VERSION "created by canmatrix"

NS_ :

BS_:

BU_: HUT T_BOX GW XBOX_D CEM Tester

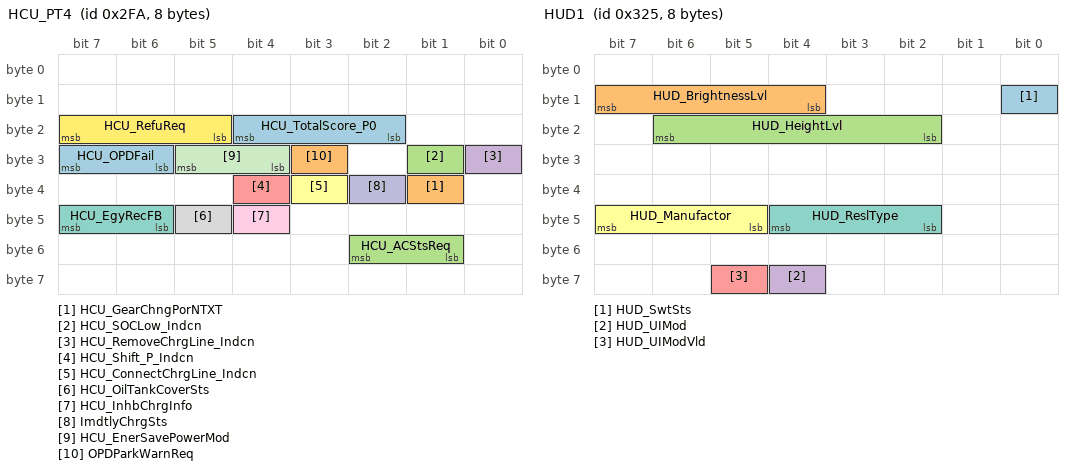
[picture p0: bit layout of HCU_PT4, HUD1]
BO_ 762 HCU_PT4: 8 GW
 SG_ HCU_TotalScore_P0 : 20|3@0+ (1,0) [0|5] "" HUT
 SG_ HCU_GearChngPorNTXT : 33|1@0+ (1,0) [0|1] "" HUT
 SG_ HCU_SOCLow_Indcn : 25|1@0+ (1,0) [0|1] "" HUT
 SG_ HCU_RemoveChrgLine_Indcn : 24|1@0+ (1,0) [0|1] "" HUT
 SG_ HCU_Shift_P_Indcn : 36|1@0+ (1,0) [0|1] "" HUT
 SG_ HCU_ConnectChrgLine_Indcn : 35|1@0+ (1,0) [0|1] "" HUT
 SG_ HCU_EgyRecFB : 47|2@0+ (1,0) [0|3] "" HUT
 SG_ HCU_OilTankCoverSts : 45|1@0+ (1,0) [0|1] "" HUT
 SG_ HCU_InhbChrgInfo : 44|1@0+ (1,0) [0|1] "" HUT
 SG_ ImdtlyChrgSts : 34|1@0+ (1,0) [0|1] "" HUT
 SG_ HCU_EnerSavePowerMod : 29|2@0+ (1,0) [0|3] "" HUT
 SG_ HCU_RefuReq : 23|3@0+ (1,0) [0|7] "" HUT
 SG_ HCU_OPDFail : 31|2@0+ (1,0) [0|3] "" HUT
 SG_ OPDParkWarnReq : 27|1@0+ (1,0) [0|1] "" HUT
 SG_ HCU_ACStsReq : 50|2@0+ (1,0) [0|3] "" HUT

BO_ 584 HCU_PT7: 8 GW
 SG_ HCU_12VSysErr_1 : 24|1@0+ (1,0) [0|1] "" HUT
 SG_ HCU_12VSysErr_2 : 39|1@0+ (1,0) [0|1] "" HUT
 SG_ HCU_HybSysErr_1 : 15|1@0+ (1,0) [0|1] "" HUT
 SG_ HCU_HybSysErr_2 : 14|1@0+ (1,0) [0|1] "" HUT
 SG_ HCU_HybSysErr_5 : 11|1@0+ (1,0) [0|1] "" HUT
 SG_ HCU_HybSysErr_6 : 10|1@0+ (1,0) [0|1] "" HUT
 SG_ HCU_HybSysErr_7 : 9|1@0+ (1,0) [0|1] "" HUT
 SG_ HCU_12VSysErrLmpSts : 8|1@0+ (1,0) [0|1] "" HUT
 SG_ HCU_HybSysErrLmpSts : 27|2@0+ (1,0) [0|3] "" HUT
 SG_ HCU_PowerRedWarnLmpCmd : 25|1@0+ (1,0) [0|1] "" HUT
 SG_ HCU_EnrgFlowInd : 55|5@0+ (1,0) [0|31] "" HUT
 SG_ HCU_HybSysErr_3 : 13|1@0+ (1,0) [0|1] "" HUT
 SG_ HCU_RdyLmpSts : 37|1@0+ (1,0) [0|1] "" HUT
 SG_ CheckSum_HCU_PT7 : 7|8@0+ (1,0) [0|255] "" HUT
 SG_ HCU_HybSysErr_4 : 12|1@0+ (1,0) [0|1] "" HUT
 SG_ HCU_EnrgFlowInd_P2 : 23|5@0+ (1,0) [0|31] "" HUT
 SG_ HCU_12VSysErr_3 : 38|1@0+ (1,0) [0|1] "" HUT
 SG_ HCU_OPDLmpSts : 36|1@0+ (1,0) [0|1] "" HUT
 SG_ HCU_OPDSts : 43|3@0+ (1,0) [0|7] "" HUT
 SG_ HCU_ModSwtFail : 63|4@0+ (1,0) [0|15] "" HUT
 SG_ RollingCounter_HCU_PT7 : 59|4@0+ (1,0) [0|15] "" HUT

BO_ 805 HUD1: 8 GW
 SG_ HUD_SwtSts : 8|1@0+ (1,0) [0|1] "" HUT
 SG_ HUD_BrightnessLvl : 15|4@0+ (1,0) [0|15] "" HUT
 SG_ HUD_HeightLvl : 22|5@0+ (1,0) [0|31] "" HUT
 SG_ HUD_UIMod : 60|1@0+ (1,0) [0|1] "" HUT
 SG_ HUD_UIModVld : 61|1@0+ (1,0) [0|1] "" HUT
 SG_ HUD_Manufactor : 47|3@0+ (1,0) [0|7] "" HUT
 SG_ HUD_ReslType : 44|3@0+ (1,0) [0|7] "" HUT

BO_ 707 HUT_FD1: 64 HUT
 SG_ SSSSet_HUT : 64|1@0+ (1,0) [0|1] "" Vector__XXX
 SG_ IFC_SnvtySet : 77|2@0+ (1,0) [0|3] "" GW
 SG_ DOWSwtReq : 104|1@0+ (1,0) [0|1] "" GW
 SG_ AEB_PedSwtReq : 105|1@0+ (1,0) [0|1] "" GW
 SG_ ALCMLightLvlSet : 75|4@0+ (1,0) [0|15] "" CEM
 SG_ FlashLmpSwtReq : 86|1@0+ (1,0) [0|1] "" CEM
 SG_ LCASwtReq : 85|1@0+ (1,0) [0|1] "" GW
 SG_ RCTASwtReq : 84|1@0+ (1,0) [0|1] "" GW
 SG_ RCTABrkSwtReq : 83|1@0+ (1,0) [0|1] "" GW
 SG_ RCWSwtReq : 82|1@0+ (1,0) [0|1] "" GW
 SG_ FCW_SnvtySet : 81|2@0+ (1,0) [0|3] "" GW
 SG_ AEB_VehSwtReq : 95|1@0+ (1,0) [0|1] "" GW
 SG_ LKASwtReq : 93|1@0+ (1,0) [0|1] "" GW
 SG_ LCKSwtReq : 92|1@0+ (1,0) [0|1] "" GW
 SG_ ELKSwtReq : 91|1@0+ (1,0) [0|1] "" GW
 SG_ ESS_PedSwtReq : 90|1@0+ (1,0) [0|1] "" GW
 SG_ ESS_VehSwtReq : 89|1@0+ (1,0) [0|1] "" GW
 SG_ LDWSwtReq : 88|1@0+ (1,0) [0|1] "" GW
 SG_ TSRSwtReq : 102|1@0+ (1,0) [0|1] "" GW
 SG_ TSRWarnSwtReq : 101|1@0+ (1,0) [0|1] "" GW
 SG_ ICA_HandsOffSwtReq : 127|1@0+ (1,0) [0|1] "" GW
 SG_ ISLSwtReq : 126|1@0+ (1,0) [0|1] "" GW
 SG_ TSR_SnvtySet : 125|5@0+ (1,-15) [-15|15] "kmh" GW
 SG_ HFASwtSts : 87|1@0+ (1,0) [0|1] "" CEM
 SG_ EPSSteerModSwtReq : 114|2@0+ (1,0) [0|3] "" GW
 SG_ DSTSwtReq : 112|1@0+ (1,0) [0|1] "" GW
 SG_ LSSWarnFormSwtReq : 100|2@0+ (1,0) [0|3] "" GW
 SG_ HUT_ESPFuncOffSwtSts : 98|1@0+ (1,0) [0|1] "" GW
 SG_ DrivingModReq_HUT : 111|4@0+ (1,0) [0|15] "" GW
 SG_ OilLvlDispReq : 115|1@0+ (1,0) [0|1] "" GW
 SG_ DrvgModeMemReq : 120|1@0+ (1,0) [0|1] "" CEM,T_BOX
 SG_ IntelligentEvaSwtReq : 107|1@0+ (1,0) [0|1] "" GW
 SG_ LSSSwtReq : 106|1@0+ (1,0) [0|1] "" GW
 SG_ HUTRadioFrq : 143|12@0+ (1,0) [0|4095] "AM: kHzFM: MHz" Vector__XXX
 SG_ MediaPlaySrc : 159|4@0+ (1,0) [0|15] "" Vector__XXX
 SG_ USB_AudioSts : 169|2@0+ (1,0) [0|3] "" Vector__XXX
 SG_ USB_VideoSts : 177|2@0+ (1,0) [0|3] "" Vector__XXX
 SG_ BT_AudioSts : 179|2@0+ (1,0) [0|3] "" Vector__XXX
 SG_ IPod_Sts : 181|2@0+ (1,0) [0|3] "" Vector__XXX
 SG_ AM_Sts : 183|2@0+ (1,0) [0|3] "" Vector__XXX
 SG_ FM_Sts : 185|2@0+ (1,0) [0|3] "" Vector__XXX
 SG_ APPLink_Sts : 187|2@0+ (1,0) [0|3] "" Vector__XXX
 SG_ QQMusic_Sts : 189|2@0+ (1,0) [0|3] "" Vector__XXX
 SG_ KaolaFM_Sts : 191|2@0+ (1,0) [0|3] "" Vector__XXX
 SG_ OnlineNews_Sts : 145|2@0+ (1,0) [0|3] "" Vector__XXX
 SG_ HUT_WadeModeSet : 161|1@0+ (1,0) [0|1] "" GW
 SG_ ExpertModReq_HUT_ECM : 175|3@0+ (1,0) [0|7] "" GW
 SG_ ExpertModReq_HUT_TCU : 172|3@0+ (1,0) [0|7] "" GW
 SG_ ExpertModReq_HUT_TOD : 163|2@0+ (1,0) [0|3] "" GW
 SG_ ChairMemPosnSet : 244|2@0+ (1,0) [0|3] "" CEM
 SG_ ChairMemPosnSetResult : 255|4@0+ (1,0) [0|15] "" CEM
 SG_ TABSwtReq_HUT : 224|1@0+ (1,0) [0|1] "" Vector__XXX
 SG_ NavVehToTrafEyeDist : 239|10@0+ (1,0) [0|1023] "" GW
 SG_ NavRoadType : 311|4@0+ (1,0) [0|15] "" GW
 SG_ NavSpdLimType : 307|2@0+ (1,0) [0|3] "" GW
 SG_ NavSpdLimValue : 271|6@0+ (1,0) [0|63] "" GW
 SG_ NavSpdLimUnit_HUT : 265|2@0+ (1,0) [0|3] "" GW
 SG_ NavCtryType : 279|10@0+ (1,0) [0|1023] "" GW
 SG_ NavSpdLimSignSts : 285|3@0+ (1,0) [0|7] "" GW
 SG_ NavTSRTrafSign : 295|8@0+ (1,0) [0|255] "" GW
 SG_ AESSwtReq : 298|1@0+ (1,0) [0|1] "" GW
 SG_ HWA_SwtReq : 280|1@0+ (1,0) [0|1] "" GW
 SG_ HWA_SnvtySet : 303|2@0+ (1,0) [0|3] "" GW
 SG_ FCTASwtReq : 301|1@0+ (1,0) [0|1] "" GW
 SG_ FCTABrkSwtReq : 300|1@0+ (1,0) [0|1] "" GW
 SG_ AEB_JASwtReq : 299|1@0+ (1,0) [0|1] "" GW
 SG_ HWA_WarnFormSwtReq : 297|1@0+ (1,0) [0|1] "" Vector__XXX
 SG_ SteerCorrnReq : 316|1@0+ (1,0) [0|1] "" GW
 SG_ ALC_SwtReq : 296|1@0+ (1,0) [0|1] "" GW
 SG_ ExpertModSwtReq_HUT : 319|1@0+ (1,0) [0|1] "" GW
 SG_ ExpertModReq_HUT_ESP : 318|2@0+ (1,0) [0|3] "" GW
 SG_ ADAS_Posn_MsgTye : 327|3@0+ (1,0) [0|7] "" GW
 SG_ ADAS_Posn_Offset : 324|13@0+ (1,0) [0|8190] "m" GW
 SG_ ADAS_Posn_CycCnt : 343|2@0+ (1,0) [0|3] "" GW
 SG_ ADAS_Posn_Pathldx : 341|6@0+ (1,0) [0|63] "" GW
 SG_ ADAS_Posn_Idx : 351|2@0+ (1,0) [0|3] "m" GW
 SG_ ADAS_Posn_PosProbb : 349|5@0+ (3.33,0) [0|100] "" GW
 SG_ ADAS_Posn_Age : 344|9@0+ (5,0) [0|2545] "ms" GW
 SG_ ADAS_Posn_PosConfdc : 366|3@0+ (1,0) [0|7] "" GW
 SG_ ADAS_Posn_CurLane : 363|3@0+ (1,0) [0|7] "" GW
 SG_ ADAS_Posn_Spd : 360|9@0+ (0.2,-12.8) [-12.8|89.2] "ms" GW
 SG_ ADAS_Posn_Rehead : 383|8@0+ (1.41732283464567,0) [0|358.583] "" GW
 SG_ FreshnessValue_HUT_FD1 : 455|16@0+ (1,0) [0|65535] "" GW
 SG_ MAC_Check_HUT_FD1 : 471|48@0+ (1,0) [0|281474976710655] "" GW
 SG_ EngStrtDischrgn : 70|1@0+ (1,0) [0|1] "" GW
 SG_ HUT_HybModReq : 119|2@0+ (1,0) [0|3] "" GW
 SG_ HUT_HybFctnReq : 117|2@0+ (1,0) [0|3] "" GW
 SG_ HUT_DrvModReq : 167|4@0+ (1,0) [0|15] "" GW

BO_ 515 HUT_FD2: 64 HUT
 SG_ HUT_OD_Obj0_ID : 15|4@0+ (1,0) [0|9] "" GW
 SG_ HUT_OD_Obj0_type : 23|3@0+ (1,0) [0|7] "" GW
 SG_ HUT_OD_Obj0_Confidence : 11|4@0+ (0.1,0) [0|1] "" GW
 SG_ HUT_OD_Obj0_width : 20|7@0+ (0.1,0) [0|12.6] "m" GW
 SG_ HUT_OD_Obj0_Ground_Pos_X : 39|12@0+ (0.01,0) [0|40] "m" GW
 SG_ HUT_OD_Obj0_Ground_Pos_Y : 43|12@0+ (0.01,-20) [-20|20] "m" GW
 SG_ HTU_OD_Obj1_ID : 79|4@0+ (1,0) [0|9] "" GW
 SG_ HUT_OD_Obj1_type : 87|3@0+ (1,0) [0|7] "" GW
 SG_ HUT_OD_Obj1_Confidence : 75|4@0+ (0.1,0) [0|1] "" GW
 SG_ HUT_OD_Obj1_width : 84|7@0+ (0.1,0) [0|12.6] "m" GW
 SG_ HUT_OD_Obj1_Ground_Pos_X : 103|12@0+ (0.01,0) [0|40] "m" GW
 SG_ HUT_OD_Obj1_Ground_Pos_Y : 107|12@0+ (0.01,-20) [-20|20] "m" GW
 SG_ HUT_OD_Obj2_ID : 143|4@0+ (1,0) [0|9] "" GW
 SG_ HUT_OD_Obj2_type : 151|3@0+ (1,0) [0|7] "" GW
 SG_ HUT_OD_Obj2_Confidence : 139|4@0+ (0.1,0) [0|1] "" GW
 SG_ HUT_OD_Obj2_width : 148|7@0+ (0.1,0) [0|12.6] "m" GW
 SG_ HUT_OD_Obj2_Ground_Pos_X : 167|12@0+ (0.01,0) [0|40] "m" GW
 SG_ HUT_OD_Obj2_Ground_Pos_Y : 171|12@0+ (0.01,-20) [-20|20] "m" GW
 SG_ HUT_OD_Obj3_ID : 207|4@0+ (1,0) [0|9] "" GW
 SG_ HUT_OD_Obj3_type : 215|3@0+ (1,0) [0|7] "" GW
 SG_ HUT_OD_Obj3_Confidence : 203|4@0+ (0.1,0) [0|1] "" GW
 SG_ HUT_OD_Obj3_width : 212|7@0+ (0.1,0) [0|12.6] "m" GW
 SG_ HUT_OD_Obj3_Ground_Pos_X : 231|12@0+ (0.01,0) [0|40] "m" GW
 SG_ HUT_OD_Obj3_Ground_Pos_Y : 235|12@0+ (0.01,-20) [-20|20] "m" GW
 SG_ HUT_OD_Obj4_ID : 271|4@0+ (1,0) [0|9] "" GW
 SG_ HUT_OD_Obj4_type : 279|3@0+ (1,0) [0|7] "" GW
 SG_ HUT_OD_Obj4_Confidence : 267|4@0+ (0.1,0) [0|1] "" GW
 SG_ HUT_OD_Obj4_width : 276|7@0+ (0.1,0) [0|12.6] "m" GW
 SG_ HUT_OD_Obj4_Ground_Pos_X : 295|12@0+ (0.01,0) [0|40] "m" GW
 SG_ HUT_OD_Obj4_Ground_Pos_Y : 299|12@0+ (0.01,-20) [-20|20] "m" GW
 SG_ HUT_OD_Obj5_ID : 335|4@0+ (1,0) [0|9] "" GW
 SG_ HUT_OD_Obj5_type : 343|3@0+ (1,0) [0|7] "" GW
 SG_ HUT_OD_Obj5_Confidence : 331|4@0+ (0.1,0) [0|1] "" GW
 SG_ HUT_OD_Obj5_width : 340|7@0+ (0.1,0) [0|12.6] "m" GW
 SG_ HUT_OD_Obj5_Ground_Pos_X : 359|12@0+ (0.01,0) [0|40] "m" GW
 SG_ HUT_OD_Obj5_Ground_Pos_Y : 363|12@0+ (0.01,-20) [-20|20] "m" GW
 SG_ HUT_OD_Obj6_ID : 399|4@0+ (1,0) [0|9] "" GW
 SG_ HUT_OD_Obj6_type : 407|3@0+ (1,0) [0|7] "" GW
 SG_ HUT_OD_Obj6_Confidence : 395|4@0+ (0.1,0) [0|1] "" GW
 SG_ HUT_OD_Obj6_width : 404|7@0+ (0.1,0) [0|12.6] "m" GW
 SG_ HUT_OD_Obj6_Ground_Pos_X : 423|12@0+ (0.01,0) [0|40] "m" GW
 SG_ HUT_OD_Obj6_Ground_Pos_Y : 427|12@0+ (0.01,-20) [-20|20] "m" GW

BO_ 579 HUT_FD3: 64 HUT
 SG_ HUT_OD_Obj7_ID : 15|4@0+ (1,0) [0|9] "" GW
 SG_ HUT_OD_Obj7_type : 23|3@0+ (1,0) [0|7] "" GW
 SG_ HUT_OD_Obj7_Confidence : 11|4@0+ (0.1,0) [0|1] "" GW
 SG_ HUT_OD_Obj7_width : 20|7@0+ (0.1,0) [0|12.6] "m" GW
 SG_ HUT_OD_Obj7_Ground_Pos_X : 39|12@0+ (0.01,0) [0|40] "m" GW
 SG_ HUT_OD_Obj7_Ground_Pos_Y : 43|12@0+ (0.01,-20) [-20|20] "m" GW
 SG_ AutoSpdSetSwt : 25|1@0+ (1,0) [0|1] "" GW
 SG_ LaneChngCfmSwt : 24|1@0+ (1,0) [0|1] "" GW
 SG_ VoiceBrdcSwt : 63|1@0+ (1,0) [0|1] "" GW
 SG_ UsrManSts : 29|4@0+ (1,0) [0|15] "" GW
 SG_ HUT_OD_WorkSts : 113|2@0+ (1,0) [0|3] "" GW
 SG_ HUT_OD_Obj_Timestamp : 79|16@0+ (1,0) [0|65535] "ms" GW
 SG_ HUT_FSD1_distance : 95|6@0+ (0.1,0) [0|6] "m" GW
 SG_ HUT_FSD2_distance : 89|6@0+ (0.1,0) [0|6] "m" GW
 SG_ HUT_FSD3_distance : 99|6@0+ (0.1,0) [0|6] "m" GW
 SG_ HUT_FSD4_distance : 109|6@0+ (0.1,0) [0|6] "m" GW
 SG_ HUT_FSD5_distance : 119|6@0+ (0.1,0) [0|6] "m" GW
 SG_ HUT_FSD6_distance : 143|6@0+ (0.1,0) [0|6] "m" GW
 SG_ HUT_FSD7_distance : 137|6@0+ (0.1,0) [0|6] "m" GW
 SG_ HUT_FSD8_distance : 147|6@0+ (0.1,0) [0|6] "m" GW
 SG_ HUT_FSD9_distance : 157|6@0+ (0.1,0) [0|6] "m" GW
 SG_ HUT_FSD10_distance : 167|6@0+ (0.1,0) [0|6] "m" GW
 SG_ HUT_FSD11_distance : 161|6@0+ (0.1,0) [0|6] "m" GW
 SG_ HUT_FSD12_distance : 171|6@0+ (0.1,0) [0|6] "m" GW
 SG_ HUT_FSD13_distance : 181|6@0+ (0.1,0) [0|6] "m" GW
 SG_ HUT_FSD14_distance : 207|6@0+ (0.1,0) [0|6] "m" GW
 SG_ HUT_FSD15_distance : 201|6@0+ (0.1,0) [0|6] "m" GW
 SG_ HUT_FSD16_distance : 211|6@0+ (0.1,0) [0|6] "m" GW
 SG_ HUT_FSD17_distance : 221|6@0+ (0.1,0) [0|6] "m" GW
 SG_ HUT_FSD18_distance : 231|6@0+ (0.1,0) [0|6] "m" GW
 SG_ NOH_Swt_Req : 335|1@0+ (1,0) [0|1] "" GW
 SG_ NOH_Act_Req : 334|1@0+ (1,0) [0|1] "" GW

BO_ 474 HUT_FD4: 64 HUT
 SG_ SlotNum_VR : 35|4@0+ (1,0) [0|15] "" GW
 SG_ UserDefinedParkCmd : 44|1@0+ (1,0) [0|1] "" GW
 SG_ HUT_HAVP_Set_Starting : 10|1@0+ (1,0) [0|1] "" GW
 SG_ HUT_HAVP_Set_Path_Ending : 21|1@0+ (1,0) [0|1] "" GW
 SG_ HUT_HAVP_APA_Permit : 43|2@0+ (1,0) [0|3] "" GW
 SG_ UserDefPrkMenuSelCmd : 18|3@0+ (1,0) [0|1] "" GW
 SG_ HUT_HAVP_SelfParLot_Ending : 9|1@0+ (1,0) [0|1] "" GW
 SG_ HUT_HAVP_Return_Btn : 11|1@0+ (1,0) [0|1] "" GW

BO_ 475 HUT_FD5: 64 HUT
 SG_ HUT_ExternalDevice : 7|512@0+ (1,0) [0|3.40282366920938E+038] "" XBOX_D

BO_ 871 HUT1: 8 HUT
 SG_ DomeLmpDlyTimSet : 7|3@0+ (1,0) [0|7] "" CEM
 SG_ FolwMeHomeDlyTimSet : 3|3@0+ (1,0) [0|7] "" CEM
 SG_ TranPMode_Req : 15|1@0+ (1,0) [0|1] "" GW,CEM
 SG_ RearviewFoldModSet : 14|1@0+ (1,0) [0|1] "" CEM
 SG_ BattSaveDelayTimeSet : 13|2@0+ (1,0) [0|3] "" CEM
 SG_ ACDualReq_TC : 21|2@0+ (1,0) [0|3] "" GW
 SG_ ACAutoModReq_TC : 19|2@0+ (1,0) [0|3] "" GW
 SG_ ACAirInletReq_TC : 17|2@0+ (1,0) [0|3] "" GW
 SG_ ACFrntHMIDis_TC : 33|1@0+ (1,0) [0|1] "" GW
 SG_ ACRearHMIDis_TC : 32|1@0+ (1,0) [0|1] "" GW
 SG_ ACAQSReq_TC : 31|2@0+ (1,0) [0|3] "" GW
 SG_ ACCmprReq_TC : 29|2@0+ (1,0) [0|3] "" GW
 SG_ ACFrntDefrstReq_TC : 27|2@0+ (1,0) [0|3] "" GW
 SG_ ACFrntBlwrSpdDecReq_TC : 25|2@0+ (1,0) [0|3] "" GW
 SG_ ACRearBlwrSpdDecReq_TC : 23|1@0+ (1,0) [0|1] "" GW
 SG_ ACRearBlwrSpdIncReq_TC : 22|1@0+ (1,0) [0|1] "" GW
 SG_ DrvDrowsnsDetnSet : 36|1@0+ (1,0) [0|1] "" CEM
 SG_ ACFrntBlwrSpdIncReq_TC : 47|2@0+ (1,0) [0|3] "" GW
 SG_ ACDrvAirDistribModReq_TC : 45|3@0+ (1,0) [0|7] "" GW
 SG_ ACDrvTempDecReq_TC : 42|2@0+ (1,0) [0|3] "" GW
 SG_ ChairMemPosnEna : 40|1@0+ (1,0) [0|1] "" CEM
 SG_ ACDrvTempIncReq_TC : 55|2@0+ (1,0) [0|3] "" GW
 SG_ ACFrntPassTempDecReq_TC : 53|2@0+ (1,0) [0|3] "" GW
 SG_ ACFrntPassTempIncReq_TC : 51|2@0+ (1,0) [0|3] "" GW
 SG_ ACAIUReq_TC : 48|1@0+ (1,0) [0|1] "" GW
 SG_ ACOffReq_TC : 63|2@0+ (1,0) [0|3] "" GW
 SG_ ACBlwrsteplsSpdReq_TC : 59|4@0+ (1,0) [0|15] "" GW
 SG_ ACZoneReq_TC : 4|1@0+ (1,0) [0|1] "" GW

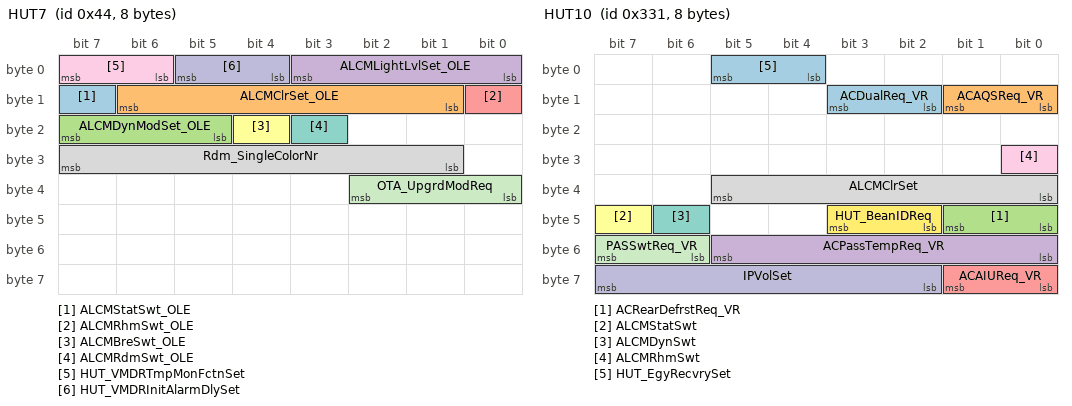
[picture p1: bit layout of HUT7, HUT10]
BO_ 68 HUT7: 8 HUT
 SG_ ALCMStatSwt_OLE : 15|1@0+ (1,0) [0|1] "" CEM
 SG_ ALCMClrSet_OLE : 14|6@0+ (1,0) [0|63] "" CEM
 SG_ ALCMDynModSet_OLE : 23|3@0+ (1,0) [0|7] "" CEM
 SG_ ALCMLightLvlSet_OLE : 3|4@0+ (1,0) [0|15] "" CEM
 SG_ ALCMRhmSwt_OLE : 8|1@0+ (1,0) [0|1] "" CEM
 SG_ ALCMBreSwt_OLE : 20|1@0+ (1,0) [0|1] "" CEM
 SG_ ALCMRdmSwt_OLE : 19|1@0+ (1,0) [0|1] "" CEM
 SG_ Rdm_SingleColorNr : 31|7@0+ (1,0) [0|127] "" CEM
 SG_ HUT_VMDRTmpMonFctnSet : 7|2@0+ (1,0) [0|3] "" Vector__XXX
 SG_ HUT_VMDRInitAlarmDlySet : 5|2@0+ (1,0) [0|3] "" Vector__XXX
 SG_ OTA_UpgrdModReq : 34|3@0+ (1,0) [0|7] "" CEM

BO_ 817 HUT10: 8 HUT
 SG_ ACDualReq_VR : 11|2@0+ (1,0) [0|3] "" GW,CEM
 SG_ ACAQSReq_VR : 9|2@0+ (1,0) [0|3] "" GW,CEM
 SG_ ACRearDefrstReq_VR : 41|2@0+ (1,0) [0|3] "" GW,CEM
 SG_ ACPassTempReq_VR : 53|6@0+ (0.5,15.5) [16|32] "Ã‚Â°C" GW,CEM
 SG_ ACAIUReq_VR : 57|2@0+ (1,0) [0|3] "" GW,CEM
 SG_ ALCMStatSwt : 47|1@0+ (1,0) [0|1] "" CEM
 SG_ ALCMDynSwt : 46|1@0+ (1,0) [0|1] "" CEM
 SG_ ALCMClrSet : 37|6@0+ (1,0) [0|63] "" CEM
 SG_ ALCMRhmSwt : 24|1@0+ (1,0) [0|1] "" CEM
 SG_ IPVolSet : 63|6@0+ (1,0) [0|63] "" GW
 SG_ PASSwtReq_VR : 55|2@0+ (1,0) [0|3] "" CEM
 SG_ HUT_BeanIDReq : 43|2@0+ (1,0) [0|3] "" GW
 SG_ HUT_EgyRecvrySet : 5|2@0+ (1,0) [0|3] "" GW

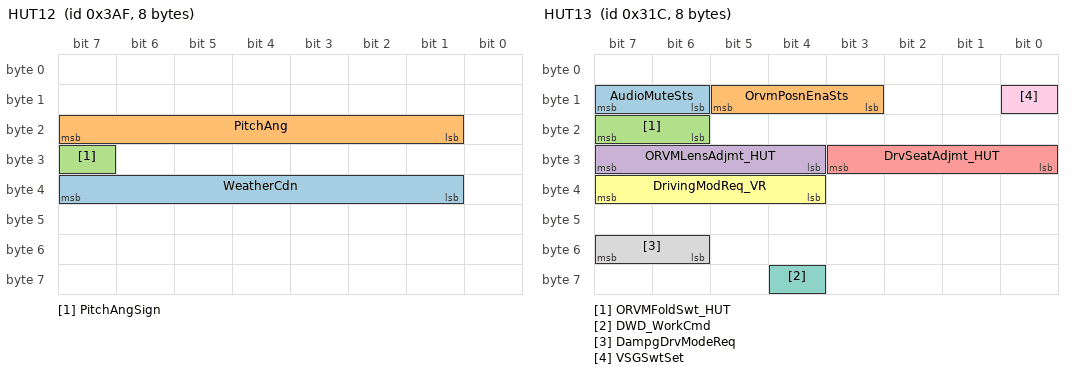
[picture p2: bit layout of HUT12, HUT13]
BO_ 943 HUT12: 8 HUT
 SG_ WeatherCdn : 39|7@0+ (1,0) [0|127] "" Vector__XXX
 SG_ PitchAng : 23|7@0+ (1,0) [0|90] "" Vector__XXX
 SG_ PitchAngSign : 31|1@0+ (1,0) [0|1] "" Vector__XXX

BO_ 796 HUT13: 8 HUT
 SG_ AudioMuteSts : 15|2@0+ (1,0) [0|3] "" T_BOX
 SG_ OrvmPosnEnaSts : 13|3@0+ (1,0) [0|7] "" CEM
 SG_ ORVMFoldSwt_HUT : 23|2@0+ (1,0) [0|3] "" CEM
 SG_ ORVMLensAdjmt_HUT : 31|4@0+ (1,0) [0|15] "" CEM
 SG_ DrvSeatAdjmt_HUT : 27|4@0+ (1,0) [0|15] "" CEM
 SG_ DrivingModReq_VR : 39|4@0+ (1,0) [0|15] "" Vector__XXX
 SG_ DWD_WorkCmd : 60|1@0+ (1,0) [0|1] "" Vector__XXX
 SG_ DampgDrvModeReq : 55|2@0+ (1,0) [0|3] "" Vector__XXX
 SG_ VSGSwtSet : 8|1@0+ (1,0) [0|1] "" GW

BO_ 494 HUT15: 16 HUT
 SG_ ACOperMod_TC : 7|2@0+ (1,0) [0|3] "" GW,CEM
 SG_ ACOperMod_VR : 5|2@0+ (1,0) [0|3] "" GW,CEM
 SG_ ACDrvSetTempSteplsReq_TC : 23|6@0+ (0.5,15.5) [16|32] "" GW,CEM
 SG_ ACPassSetTempSteplsReq_TC : 31|6@0+ (0.5,15.5) [16|32] "" GW,CEM
 SG_ SDWSwtSet : 39|1@0+ (1,0) [0|1] "" GW
 SG_ APSSwtReq_VR : 55|2@0+ (1,0) [0|3] "" GW
 SG_ APSPrkgTypSeln : 34|2@0+ (1,0) [0|3] "" GW
 SG_ SunShadeSwtReq_VR : 43|4@0+ (1,0) [0|15] "" CEM
 SG_ SunRoofSwtReq_VR : 47|4@0+ (1,0) [0|15] "" CEM
 SG_ SportModLightSet : 1|2@0+ (1,0) [0|3] "" CEM
 SG_ ABSLmpSet : 14|1@0+ (1,0) [0|1] "" CEM
 SG_ AutoWshWipSet : 12|2@0+ (1,0) [0|3] "" CEM
 SG_ SeekVehSet : 10|2@0+ (1,0) [0|3] "" CEM
 SG_ SpdAutoLockModSet : 25|2@0+ (1,0) [0|3] "" CEM
 SG_ ParkLmpSet : 8|1@0+ (1,0) [0|1] "" CEM
 SG_ DoorUnlockModSet : 15|1@0+ (1,0) [0|1] "" CEM
 SG_ SteerWheelHeatSwtReq : 3|2@0+ (1,0) [0|3] "" GW
 SG_ PASExitSpdSwt : 53|2@0+ (1,0) [0|3] "" CEM
 SG_ FrntRearACDispSts : 49|2@0+ (1,0) [0|3] "" GW,CEM
 SG_ FreshnessValue_HUT15 : 71|16@0+ (1,0) [0|65535] "" GW
 SG_ MAC_Check_HUT15 : 87|48@0+ (1,0) [0|281474976710655] "" GW

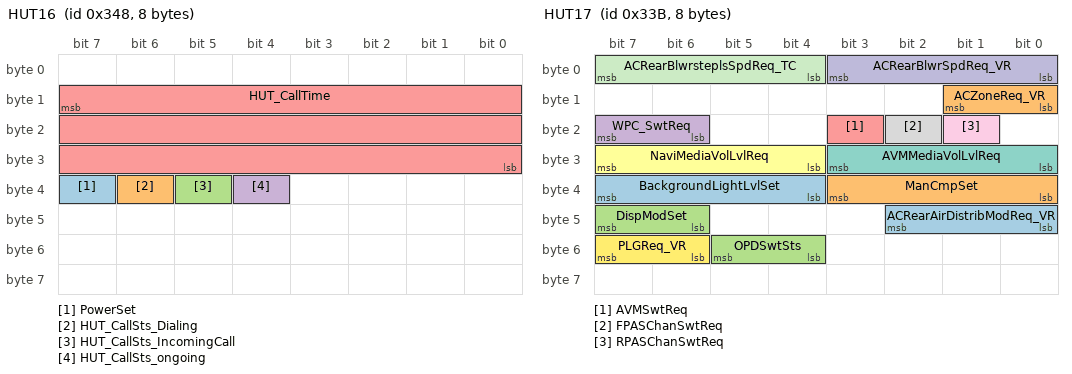
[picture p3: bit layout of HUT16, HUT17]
BO_ 840 HUT16: 8 HUT
 SG_ PowerSet : 39|1@0+ (1,0) [0|1] "" GW
 SG_ HUT_CallSts_Dialing : 38|1@0+ (1,0) [0|1] "" Vector__XXX
 SG_ HUT_CallSts_IncomingCall : 37|1@0+ (1,0) [0|1] "" Vector__XXX
 SG_ HUT_CallSts_ongoing : 36|1@0+ (1,0) [0|1] "" Vector__XXX
 SG_ HUT_CallTime : 15|24@0+ (1,0) [0|359999] "" Vector__XXX

BO_ 827 HUT17: 8 HUT
 SG_ BackgroundLightLvlSet : 39|4@0+ (1,0) [0|15] "" CEM
 SG_ ManCmpSet : 35|4@0+ (1,0) [0|15] "" Vector__XXX
 SG_ DispModSet : 47|2@0+ (1,0) [0|3] "" Vector__XXX
 SG_ WPC_SwtReq : 23|2@0+ (1,0) [0|3] "" GW
 SG_ AVMSwtReq : 19|1@0+ (1,0) [0|1] "" GW
 SG_ NaviMediaVolLvlReq : 31|4@0+ (1,0) [0|15] "" GW
 SG_ AVMMediaVolLvlReq : 27|4@0+ (1,0) [0|15] "" GW
 SG_ FPASChanSwtReq : 18|1@0+ (1,0) [0|1] "" GW
 SG_ RPASChanSwtReq : 17|1@0+ (1,0) [0|1] "" GW
 SG_ ACRearBlwrSpdReq_VR : 3|4@0+ (1,0) [0|15] "" GW,CEM
 SG_ ACRearBlwrsteplsSpdReq_TC : 7|4@0+ (1,0) [0|15] "" GW,CEM
 SG_ PLGReq_VR : 55|2@0+ (1,0) [0|3] "" CEM
 SG_ ACRearAirDistribModReq_VR : 42|3@0+ (1,0) [0|7] "" GW,CEM
 SG_ ACZoneReq_VR : 9|2@0+ (1,0) [0|3] "" GW,CEM
 SG_ OPDSwtSts : 53|2@0+ (1,0) [0|3] "" GW

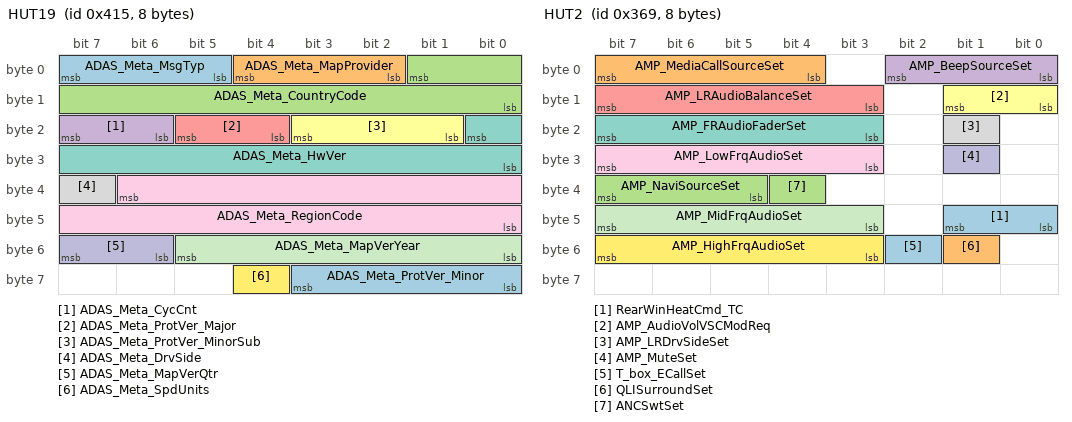
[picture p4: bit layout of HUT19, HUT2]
BO_ 1045 HUT19: 8 HUT
 SG_ ADAS_Meta_MsgTyp : 7|3@0+ (1,0) [0|7] "" GW
 SG_ ADAS_Meta_MapProvider : 4|3@0+ (1,0) [0|7] "" GW
 SG_ ADAS_Meta_CountryCode : 1|10@0+ (1,0) [0|1023] "" GW
 SG_ ADAS_Meta_CycCnt : 23|2@0+ (1,0) [0|3] "" GW
 SG_ ADAS_Meta_ProtVer_Major : 21|2@0+ (1,0) [0|3] "" GW
 SG_ ADAS_Meta_ProtVer_MinorSub : 19|3@0+ (1,0) [0|7] "" GW
 SG_ ADAS_Meta_HwVer : 16|9@0+ (1,0) [0|511] "" GW
 SG_ ADAS_Meta_DrvSide : 39|1@0+ (1,0) [0|1] "" GW
 SG_ ADAS_Meta_RegionCode : 38|15@0+ (1,0) [0|32767] "" GW
 SG_ ADAS_Meta_MapVerQtr : 55|2@0+ (1,0) [0|3] "" GW
 SG_ ADAS_Meta_MapVerYear : 53|6@0+ (1,0) [0|63] "" GW
 SG_ ADAS_Meta_SpdUnits : 60|1@0+ (1,0) [0|1] "" GW
 SG_ ADAS_Meta_ProtVer_Minor : 59|4@0+ (1,0) [0|15] "" GW

BO_ 873 HUT2: 8 HUT
 SG_ RearWinHeatCmd_TC : 41|2@0+ (1,0) [0|3] "" GW
 SG_ AMP_MediaCallSourceSet : 7|4@0+ (1,0) [0|15] "" GW
 SG_ AMP_NaviSourceSet : 39|3@0+ (1,0) [0|7] "" GW
 SG_ AMP_BeepSourceSet : 2|3@0+ (1,0) [0|7] "" GW
 SG_ AMP_LRAudioBalanceSet : 15|5@0+ (1,0) [0|20] "" GW
 SG_ AMP_AudioVolVSCModReq : 9|2@0+ (1,0) [0|3] "" GW
 SG_ AMP_FRAudioFaderSet : 23|5@0+ (1,0) [0|20] "" GW
 SG_ AMP_LRDrvSideSet : 17|1@0+ (1,0) [0|1] "" GW
 SG_ AMP_LowFrqAudioSet : 31|5@0+ (1,0) [0|20] "" GW
 SG_ AMP_MuteSet : 25|1@0+ (1,0) [0|1] "" GW
 SG_ AMP_MidFrqAudioSet : 47|5@0+ (1,0) [0|20] "" GW
 SG_ AMP_HighFrqAudioSet : 55|5@0+ (1,0) [0|20] "" GW
 SG_ T_box_ECallSet : 50|1@0+ (1,0) [0|1] "" GW
 SG_ QLISurroundSet : 49|1@0+ (1,0) [0|1] "" GW
 SG_ ANCSwtSet : 36|1@0+ (1,0) [0|1] "" GW

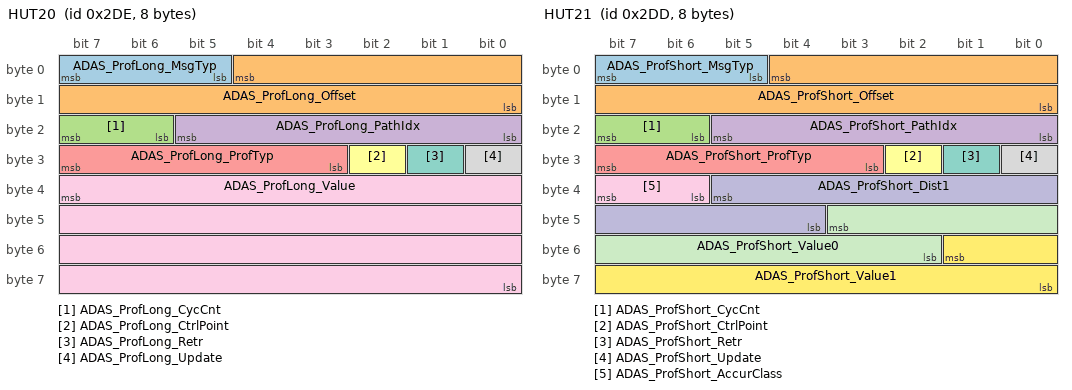
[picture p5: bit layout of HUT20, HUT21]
BO_ 734 HUT20: 8 HUT
 SG_ ADAS_ProfLong_MsgTyp : 7|3@0+ (1,0) [0|7] "" GW
 SG_ ADAS_ProfLong_Offset : 4|13@0+ (1,0) [0|8190] "m" GW
 SG_ ADAS_ProfLong_CycCnt : 23|2@0+ (1,0) [0|3] "" GW
 SG_ ADAS_ProfLong_PathIdx : 21|6@0+ (1,0) [0|63] "" GW
 SG_ ADAS_ProfLong_ProfTyp : 31|5@0+ (1,0) [0|31] "" GW
 SG_ ADAS_ProfLong_CtrlPoint : 26|1@0+ (1,0) [0|1] "" GW
 SG_ ADAS_ProfLong_Retr : 25|1@0+ (1,0) [0|1] "" GW
 SG_ ADAS_ProfLong_Update : 24|1@0+ (1,0) [0|1] "" GW
 SG_ ADAS_ProfLong_Value : 39|32@0+ (1,0) [0|4294967295] "" GW

BO_ 733 HUT21: 8 HUT
 SG_ ADAS_ProfShort_MsgTyp : 7|3@0+ (1,0) [0|7] "" GW
 SG_ ADAS_ProfShort_Offset : 4|13@0+ (1,0) [0|8190] "m" GW
 SG_ ADAS_ProfShort_CycCnt : 23|2@0+ (1,0) [0|3] "" GW
 SG_ ADAS_ProfShort_PathIdx : 21|6@0+ (1,0) [0|63] "" GW
 SG_ ADAS_ProfShort_ProfTyp : 31|5@0+ (1,0) [0|31] "" GW
 SG_ ADAS_ProfShort_CtrlPoint : 26|1@0+ (1,0) [0|1] "" GW
 SG_ ADAS_ProfShort_Retr : 25|1@0+ (1,0) [0|1] "" GW
 SG_ ADAS_ProfShort_Update : 24|1@0+ (1,0) [0|1] "" GW
 SG_ ADAS_ProfShort_AccurClass : 39|2@0+ (1,0) [0|3] "" GW
 SG_ ADAS_ProfShort_Dist1 : 37|10@0+ (1,0) [0|1022] "m" GW
 SG_ ADAS_ProfShort_Value0 : 43|10@0+ (1,0) [0|1022] "" GW
 SG_ ADAS_ProfShort_Value1 : 49|10@0+ (1,0) [0|1022] "" GW

BO_ 730 HUT22: 8 HUT
 SG_ ADAS_Seg_MsgTyp : 7|3@0+ (1,0) [0|7] "" GW
 SG_ ADAS_Seg_Offset : 4|13@0+ (1,0) [0|8190] "m" GW
 SG_ ADAS_Seg_CycCnt : 23|2@0+ (1,0) [0|3] "" GW
 SG_ ADAS_Seg_PathIdx : 21|6@0+ (1,0) [0|63] "" GW
 SG_ ADAS_Seg_Tunnel : 31|2@0+ (1,0) [0|3] "" GW
 SG_ ADAS_Seg_Brdg : 29|2@0+ (1,0) [0|3] "" GW
 SG_ ADAS_Seg_BuildUpArea : 27|2@0+ (1,0) [0|3] "" GW
 SG_ ADAS_Seg_Retr : 25|1@0+ (1,0) [0|1] "" GW
 SG_ ADAS_Seg_Update : 24|1@0+ (1,0) [0|1] "" GW
 SG_ ADAS_Seg_RelProbb : 39|5@0+ (3.33333333333333,0) [0|100] "" GW
 SG_ ADAS_Seg_FuncRoadClass : 34|3@0+ (1,0) [0|7] "" GW
 SG_ ADAS_Seg_PartOfCalcRoute : 47|2@0+ (1,0) [0|3] "" GW
 SG_ ADAS_Seg_CmplxInsct : 45|2@0+ (1,0) [0|3] "" GW
 SG_ ADAS_Seg_FormOfWay : 43|4@0+ (1,0) [0|15] "" GW
 SG_ ADAS_Seg_EffSpdLmt : 55|5@0+ (1,0) [0|31] "" GW
 SG_ ADAS_Seg_EffSpdLmtTyp : 50|3@0+ (1,0) [0|7] "" GW
 SG_ ADAS_Seg_DivideRoad : 62|2@0+ (1,0) [0|3] "" GW
 SG_ ADAS_Seg_NumOfLaneOppDir : 60|2@0+ (1,0) [0|3] "" GW
 SG_ ADAS_Seg_NumOfLaneDrvDir : 58|3@0+ (1,0) [0|7] "" GW

CM_ SG_ 762 HCU_TotalScore_P0 "the Total score of the  driverÃ¢Â€Â˜s drive style and  energy consumption in this dirve cycle";
CM_ SG_ 762 HCU_GearChngPorNTXT "Change To Gear P or N Ã¯Â¼ÂˆÃ¦ÂÂÃ§Â¤ÂºÃ¤Â¿Â¡Ã¦ÂÂ¯Ã¯Â¼ÂšÃ¨Â¯Â·Ã¥ÂˆÂ‡Ã¦ÂÂ¢Ã¨Â‡Â³PÃ¦Â¡Â£Ã¦ÂˆÂ–NÃ¦Â¡Â£Ã¯Â¼Â‰IP Received";
CM_ SG_ 762 HCU_SOCLow_Indcn "Indicate word:
Battery lowÃ¯Â¼ÂŒcharge immediatelyIP Received";
CM_ SG_ 762 HCU_RemoveChrgLine_Indcn "Indicate word:
Remove the charge lineIP Received";
CM_ SG_ 762 HCU_Shift_P_Indcn "Indicate word:
Shift to P gear levelIP Received";
CM_ SG_ 762 HCU_ConnectChrgLine_Indcn "Indicate word:
connect  the charge lineIP Received";
CM_ SG_ 762 HCU_EgyRecFB "Energy recuperation FeedbackHUT";
CM_ SG_ 762 HCU_OilTankCoverSts "Oil tank cover status";
CM_ SG_ 762 HCU_InhbChrgInfo "Inhibit Charge InformationIP Received";
CM_ SG_ 762 ImdtlyChrgSts "Immediately Charge Status";
CM_ SG_ 762 HCU_EnerSavePowerMod "Storage battery power low active , vehicle enter save power mode.HUT";
CM_ SG_ 762 HCU_RefuReq "HCU refueling  RequestIP Received";
CM_ SG_ 762 HCU_OPDFail "One Pedal Driving Failure Status";
CM_ SG_ 762 OPDParkWarnReq "OPD Parking Warning Request";
CM_ SG_ 762 HCU_ACStsReq "AC status requestHUT";
CM_ SG_ 584 HCU_12VSysErr_1 "12V system error indicate word:12V system error Ã¯Â¼ÂŒstop the vehicle in a safety place.IP Received";
CM_ SG_ 584 HCU_12VSysErr_2 "12V system error indicate word:12V system error Ã¯Â¼ÂŒgo to the service piont.IP Received";
CM_ SG_ 584 HCU_HybSysErr_1 "Hybrid error indicate word: Hybrid system error stop the vehicle in a safety place.IP Received";
CM_ SG_ 584 HCU_HybSysErr_2 "Hybrid error indicate word: Hybrid system not available due to collision .IP Received";
CM_ SG_ 584 HCU_HybSysErr_5 "Hybrid error indicate word: BSG system error Ã¯Â¼ÂŒgo to the service piont.IP Received";
CM_ SG_ 584 HCU_HybSysErr_6 "Hybrid error indicate word:  temporary hybrid system limitations drive carefullyIP Received";
CM_ SG_ 584 HCU_HybSysErr_7 "Hybrid error indicate word: Braking energy recovery system error,go to the service piont.IP Received";
CM_ SG_ 584 HCU_12VSysErrLmpSts "12V system error indicate lamp  statusIP Received";
CM_ SG_ 584 HCU_HybSysErrLmpSts "Hybrid system error  indicate lamp statusIP Received";
CM_ SG_ 584 HCU_PowerRedWarnLmpCmd "The power reduction warning lamp comes on. Whenever a power reduction warning happens.IP Received";
CM_ SG_ 584 HCU_EnrgFlowInd "the mode of current energy flowIP Received";
CM_ SG_ 584 HCU_HybSysErr_3 "Hybrid error indicate word: Hybrid system error ,go to the service piont.IP Received";
CM_ SG_ 584 HCU_RdyLmpSts "Hybrid system ready lampÃ¯Â¼ÂˆÃ§Â‚Â¹Ã¤ÂºÂ®readyÃ§ÂÂ¯Ã¯Â¼Â‰";
CM_ SG_ 584 CheckSum_HCU_PT7 "Use the checksum strategy from document Ã¢Â€ÂœEnd-to-End Communication Protection SpecificationÃ¢Â€Â";
CM_ SG_ 584 HCU_HybSysErr_4 "Hybrid error indicate word: Rear traction system error ,go to the service piont.IP";
CM_ SG_ 584 HCU_EnrgFlowInd_P2 "the mode of current energy flowHUT";
CM_ SG_ 584 HCU_12VSysErr_3 "12V system error indicate word:12V system error Ã¯Â¼ÂŒcomfort function limited.IP";
CM_ SG_ 584 HCU_OPDLmpSts "OPD indicator light requestIP Received";
CM_ SG_ 584 HCU_OPDSts "One Pedal Driving StatusIP Received";
CM_ SG_ 584 HCU_ModSwtFail "Mode Switch Failure prompt MessageIPHUT Received";
CM_ SG_ 584 RollingCounter_HCU_PT7 "Rolling counter";
CM_ SG_ 805 HUD_SwtSts "Status of HUD Switch";
CM_ SG_ 805 HUD_BrightnessLvl "Brightness Level of HUD";
CM_ SG_ 805 HUD_HeightLvl "Height Level of HUD";
CM_ SG_ 805 HUD_UIMod "UI Mode of HUD";
CM_ SG_ 805 HUD_UIModVld "UI Mode Valid of HUD";
CM_ SG_ 805 HUD_Manufactor "HUD manufactor";
CM_ SG_ 805 HUD_ReslType "Resolution type of HUD";
CM_ SG_ 707 SSSSet_HUT "Smart Start and stop set by HUT";
CM_ SG_ 707 IFC_SnvtySet "IFC(Intelligent Forward Camera) sensitivity setADAS-CANFD To:IFC,IDC_L2";
CM_ SG_ 707 DOWSwtReq "Request of DOW(Door Open Warning) function SwitchADAS-CANFD To:RSDS_R,RSDS_L";
CM_ SG_ 707 AEB_PedSwtReq "Request of AEB(Auto Emergency Brake) function Switch for Pedestrian modeADAS-CANFD To:IFC,IDC_L2";
CM_ SG_ 707 ALCMLightLvlSet "ALCM(Ambient Light Control Module) Light level set";
CM_ SG_ 707 FlashLmpSwtReq "Request of Flash Lamp Switch";
CM_ SG_ 707 LCASwtReq "Request of LCA (Lane Change Assist) function SwitchADAS-CANFD To:RSDS_R,RSDS_L";
CM_ SG_ 707 RCTASwtReq "Request of CTA(Cross Traffic Assist) function SwitchADAS-CANFD To:RSDS_R,RSDS_L";
CM_ SG_ 707 RCTABrkSwtReq "Request of CTABrake(Cross Traffic Assist with Brake) SwitchADAS-CANFD To:RSDS_R,RSDS_L";
CM_ SG_ 707 RCWSwtReq "Request of Control RCW (Rear Collision Warning ) SwitchADAS-CANFD To:RSDS_R,RSDS_L";
CM_ SG_ 707 FCW_SnvtySet "FCW(Front Crash Warning) sensitivity setADAS-CANFD To:IFC,CR_L,CR_R,IDC_L2";
CM_ SG_ 707 AEB_VehSwtReq "Request of Control AEB (Auto Emergency Brake) Switch for Vehicle modeADAS-CANFD To:IFC,IDC_L2";
CM_ SG_ 707 LKASwtReq "Request of Control LKA(Lane Keeping Assist) SwitchADAS-CANFD To:IFC,IDC_L2";
CM_ SG_ 707 LCKSwtReq "Request of Control LCK(Lane Center Keeping) SwitchADAS-CANFD To:IFC,IDC_L2";
CM_ SG_ 707 ELKSwtReq "Request of Control ELK(Emergency Lane Keeping) SwitchADAS-CANFD To:IFC,IDC_L2";
CM_ SG_ 707 ESS_PedSwtReq "ESS(Evasive Steering Support)-Pedestrian switch requestADAS-CANFD To:IFC,IDC_L2";
CM_ SG_ 707 ESS_VehSwtReq "ESS(Evasive Steering Support)-Vehicle switch requestADAS-CANFD To:IFC,IDC_L2";
CM_ SG_ 707 LDWSwtReq "Request of Control LDW(Lane Detection Warning) SwitchADAS-CANFD To:IFC,IDC_L2";
CM_ SG_ 707 TSRSwtReq "Request of Control TSR(Traffic Sign Recognition) SwitchADAS-CANFD To:IFC,IDC_L2";
CM_ SG_ 707 TSRWarnSwtReq "Request of Control TSRWarn(Traffic Sign Recognition Warning) SwitchADAS-CANFD To:IFC,IDC_L2";
CM_ SG_ 707 ICA_HandsOffSwtReq "Request of Control ICA_HandsOff(Intelligent Cruise Assist Hands Off) SwitchADAS-CANFD To:IFC,IDC_L2";
CM_ SG_ 707 ISLSwtReq "Request of Control ISL(Intelligent Speed Limit) SwitchADAS-CANFD To:IFC,IDC_L2";
CM_ SG_ 707 TSR_SnvtySet "TSR(Traffic Sign Recognition) sensitivity setADAS-CANFD To:IFC,IDC_L2";
CM_ SG_ 707 HFASwtSts "HFA(Hands Free Access) Switch Status";
CM_ SG_ 707 EPSSteerModSwtReq "Resquet of EPS(Electric Power Steering) steering mode switchPT_CAN To:EPS";
CM_ SG_ 707 DSTSwtReq "Request of DST(Dynamic Steering Torque) SwitchPT_CAN To:ESP";
CM_ SG_ 707 LSSWarnFormSwtReq "LSS(Lane Support System) Warning Form SwitchADAS-CANFD To:IFC,IDC_L2";
CM_ SG_ 707 HUT_ESPFuncOffSwtSts "Control ESP switch status of HUTÃ£Â€Â‚
When it is 0x0, switch is not pressed,ESP function is ON
when it is 0x1, switch is pressed,ESP function is OffPT_CAN:To ESP";
CM_ SG_ 707 DrivingModReq_HUT "Driving mode request by HUT(Head Unit System)BD2_CAN:To AMP";
CM_ SG_ 707 OilLvlDispReq "Oil level display requestPT_CAN:To ECM";
CM_ SG_ 707 DrvgModeMemReq "Driving mode memory request";
CM_ SG_ 707 IntelligentEvaSwtReq "Intelligent evade switch requestADAS-CANFD To:IFC,IDC_L2";
CM_ SG_ 707 LSSSwtReq "Request of Control  LSS(Lane Support System) SwitchADAS-CANFD To:IFC,IDC_L2";
CM_ SG_ 707 HUTRadioFrq "HUT(Head Unit System) Radio frequencyÃ§Â‹Â¬Ã§Â«Â‹AMP";
CM_ SG_ 707 MediaPlaySrc "Media Play SourcesÃ¤Â¸ÂŽRHDSÃ¥ÂÂŒÃ¦Â­Â¥";
CM_ SG_ 707 USB_AudioSts "USB Audio StatusÃ¤Â¸ÂŽRHDSÃ¥ÂÂŒÃ¦Â­Â¥";
CM_ SG_ 707 USB_VideoSts "USB Video StatusÃ¤Â¸ÂŽRHDSÃ¥ÂÂŒÃ¦Â­Â¥";
CM_ SG_ 707 BT_AudioSts "BT Audio StatusÃ¤Â¸ÂŽRHDSÃ¥ÂÂŒÃ¦Â­Â¥";
CM_ SG_ 707 IPod_Sts "IPod StatusÃ¤Â¸ÂŽRHDSÃ¥ÂÂŒÃ¦Â­Â¥";
CM_ SG_ 707 AM_Sts "AM StatusÃ¤Â¸ÂŽRHDSÃ¥ÂÂŒÃ¦Â­Â¥";
CM_ SG_ 707 FM_Sts "FM StatusÃ¤Â¸ÂŽRHDSÃ¥ÂÂŒÃ¦Â­Â¥";
CM_ SG_ 707 APPLink_Sts "APPLink StatusÃ¤Â¸ÂŽRHDSÃ¥ÂÂŒÃ¦Â­Â¥";
CM_ SG_ 707 QQMusic_Sts "QQ Music StatusÃ¤Â¸ÂŽRHDSÃ¥ÂÂŒÃ¦Â­Â¥";
CM_ SG_ 707 KaolaFM_Sts "Kaola FM StatusÃ¤Â¸ÂŽRHDSÃ¥ÂÂŒÃ¦Â­Â¥";
CM_ SG_ 707 OnlineNews_Sts "Online News StatusÃ¤Â¸ÂŽRHDSÃ¥ÂÂŒÃ¦Â­Â¥";
CM_ SG_ 707 HUT_WadeModeSet "Wade Mode SetPT-CAN To:ESP";
CM_ SG_ 707 ExpertModReq_HUT_ECM "ECM mode  request by HUTPT_CAN:To ECM";
CM_ SG_ 707 ExpertModReq_HUT_TCU "TCU mode  request by HUTPT_CAN:To TCU";
CM_ SG_ 707 ExpertModReq_HUT_TOD "TOD mode  request by HUTBD2_CAN:To TOD";
CM_ SG_ 707 ChairMemPosnSet "Chair Memory Position Set";
CM_ SG_ 707 ChairMemPosnSetResult "Chair memory position set result";
CM_ SG_ 707 TABSwtReq_HUT "TAB(Turning Assistant by Braking) Switch Request";
CM_ SG_ 707 NavVehToTrafEyeDist "Indicate the distance between the vehicle and  traffic EyeADAS_CAN:To IFC,IDC_L2";
CM_ SG_ 707 NavRoadType "Indicate the rode type of current location that this vehicle is driving detected by navigationADAS_CAN:To IFC,IDC_L2";
CM_ SG_ 707 NavSpdLimType "Indicate speed limit  sign type of current road detected by navigationADAS_CAN:To IFC,IDC_L2";
CM_ SG_ 707 NavSpdLimValue "Indicate the value of speed limit sign of current road detected by navigationADAS_CAN:To IFC,IDC_L2";
CM_ SG_ 707 NavSpdLimUnit_HUT "Indicate speed limit unit of current rode detected by navigationADAS_CAN:To IFC,IDC_L2";
CM_ SG_ 707 NavCtryType "Indicate the country type of current location that this vehicle is drivingADAS_CAN:To IFC,IDC_L2";
CM_ SG_ 707 NavSpdLimSignSts "Indicate whether the navigation detects single or multiple speed limit signsADAS_CAN:To IFC,IDC_L2";
CM_ SG_ 707 NavTSRTrafSign "Indicate the value of traffic sign of current road detected by navigationADAS_CAN:To IFC,IDC_L2";
CM_ SG_ 707 AESSwtReq "AES(Automatic Emergency Steering) function switch requestADAS_CAN:To IFC,IDC_L2";
CM_ SG_ 707 HWA_SwtReq "HWA Switch RequestADAS-CANFD To:IDC_L2";
CM_ SG_ 707 HWA_SnvtySet "HWA Sensitive SetADAS-CANFD To:IDC_L2";
CM_ SG_ 707 FCTASwtReq "FCTA Switch RequestADAS-CANFD To:CR_L,CR_R";
CM_ SG_ 707 FCTABrkSwtReq "FCTA Brake Switch RequestADAS-CANFD To:CR_L,CR_R";
CM_ SG_ 707 AEB_JASwtReq "AEB-JA fuction switch requestADAS-CANFD To:IFC,IDC_L2";
CM_ SG_ 707 HWA_WarnFormSwtReq "HWA(Highway Assist) Warning Form Switch";
CM_ SG_ 707 SteerCorrnReq "Steering Correction Reminder Switch RequestPT_CAN:To EPS";
CM_ SG_ 707 ALC_SwtReq "ALC(Automatic lane change assistance) fuction switch requestADAS-CANFD To:IDC_L2";
CM_ SG_ 707 ExpertModSwtReq_HUT "Expert mode switch request by HUTPT_CAN:To ESP,TCU,ECM
BD2_CAN:To TOD";
CM_ SG_ 707 ExpertModReq_HUT_ESP "Expert mode  request by HUTPT_CAN:To ESP";
CM_ SG_ 707 ADAS_Posn_MsgTye "Identify type of messageADAS-CANFD To:IFC,IDC_L2";
CM_ SG_ 707 ADAS_Posn_Offset "Distance btween vehicle and start locationADAS-CANFD To:IFC,IDC_L2";
CM_ SG_ 707 ADAS_Posn_CycCnt "Message rollingcounterADAS-CANFD To:IFC,IDC_L2";
CM_ SG_ 707 ADAS_Posn_Pathldx "Current path quotation markADAS-CANFD To:IFC,IDC_L2";
CM_ SG_ 707 ADAS_Posn_Idx "If  Av2HP supports Positioning alternative ,this is condidate quotation markADAS-CANFD To:IFC,IDC_L2";
CM_ SG_ 707 ADAS_Posn_PosProbb "ADAS_Posn_PosProbbADAS-CANFD To:IFC,IDC_L2";
CM_ SG_ 707 ADAS_Posn_Age "Duration between message transmits and vehcle position is gotADAS-CANFD To:IFC,IDC_L2";
CM_ SG_ 707 ADAS_Posn_PosConfdc "Confidence degree of positionADAS-CANFD To:IFC,IDC_L2";
CM_ SG_ 707 ADAS_Posn_CurLane "Type of currentADAS-CANFD To:IFC,IDC_L2";
CM_ SG_ 707 ADAS_Posn_Spd "Estimated speed of vehicles along the pathADAS-CANFD To:IFC,IDC_L2";
CM_ SG_ 707 ADAS_Posn_Rehead "Head orientation relative to pathADAS-CANFD To:IFC,IDC_L2";
CM_ SG_ 707 FreshnessValue_HUT_FD1 "ADAS-CANFD To:IDC_L2";
CM_ SG_ 707 MAC_Check_HUT_FD1 "MAC protection mechanism should comply with the GWM MAC SpecificatioADAS-CANFD To:IDC_L2";
CM_ SG_ 707 EngStrtDischrgn "enable start engine for dischargingPT_CAN:To PDCU";
CM_ SG_ 707 HUT_HybModReq "Hybrid mode requestPT_CAN:To PDCU";
CM_ SG_ 707 HUT_HybFctnReq "Hybrid Battery SOC management mode and Sport plus mode reqestPT_CAN:To PDCU";
CM_ SG_ 707 HUT_DrvModReq "driver mode requestHC_CAN:To PDCU";
CM_ SG_ 515 HUT_OD_Obj0_ID "ID of the Target obstacleADAS-CANFD To:PAS,RPAS";
CM_ SG_ 515 HUT_OD_Obj0_type "OD_typeADAS-CANFD To:PAS,RPAS";
CM_ SG_ 515 HUT_OD_Obj0_Confidence "Confidence of the Target obstacleADAS-CANFD To:PAS,RPAS";
CM_ SG_ 515 HUT_OD_Obj0_width "Width of the Target obstacleADAS-CANFD To:PAS,RPAS";
CM_ SG_ 515 HUT_OD_Obj0_Ground_Pos_X "X-Axis Position of the Target obstacleADAS-CANFD To:PAS,RPAS";
CM_ SG_ 515 HUT_OD_Obj0_Ground_Pos_Y "Y-Axis Position of the Target obstacleADAS-CANFD To:PAS,RPAS";
CM_ SG_ 515 HTU_OD_Obj1_ID "ID of the Target obstacleADAS-CANFD To:PAS,RPAS";
CM_ SG_ 515 HUT_OD_Obj1_type "OD_typeADAS-CANFD To:PAS,RPAS";
CM_ SG_ 515 HUT_OD_Obj1_Confidence "Confidence of the Target obstacleADAS-CANFD To:PAS,RPAS";
CM_ SG_ 515 HUT_OD_Obj1_width "Width of the Target obstacleADAS-CANFD To:PAS,RPAS";
CM_ SG_ 515 HUT_OD_Obj1_Ground_Pos_X "X-Axis Position of the Target obstacleADAS-CANFD To:PAS,RPAS";
CM_ SG_ 515 HUT_OD_Obj1_Ground_Pos_Y "Y-Axis Position of the Target obstacleADAS-CANFD To:PAS,RPAS";
CM_ SG_ 515 HUT_OD_Obj2_ID "ID of the Target obstacleADAS-CANFD To:PAS,RPAS";
CM_ SG_ 515 HUT_OD_Obj2_type "OD_typeADAS-CANFD To:PAS,RPAS";
CM_ SG_ 515 HUT_OD_Obj2_Confidence "Confidence of the Target obstacleADAS-CANFD To:PAS,RPAS";
CM_ SG_ 515 HUT_OD_Obj2_width "Width of the Target obstacleADAS-CANFD To:PAS,RPAS";
CM_ SG_ 515 HUT_OD_Obj2_Ground_Pos_X "X-Axis Position of the Target obstacleADAS-CANFD To:PAS,RPAS";
CM_ SG_ 515 HUT_OD_Obj2_Ground_Pos_Y "Y-Axis Position of the Target obstacleADAS-CANFD To:PAS,RPAS";
CM_ SG_ 515 HUT_OD_Obj3_ID "ID of the Target obstacleADAS-CANFD To:PAS,RPAS";
CM_ SG_ 515 HUT_OD_Obj3_type "OD_typeADAS-CANFD To:PAS,RPAS";
CM_ SG_ 515 HUT_OD_Obj3_Confidence "Confidence of the Target obstacleADAS-CANFD To:PAS,RPAS";
CM_ SG_ 515 HUT_OD_Obj3_width "Width of the Target obstacleADAS-CANFD To:PAS,RPAS";
CM_ SG_ 515 HUT_OD_Obj3_Ground_Pos_X "X-Axis Position of the Target obstacleADAS-CANFD To:PAS,RPAS";
CM_ SG_ 515 HUT_OD_Obj3_Ground_Pos_Y "Y-Axis Position of the Target obstacleADAS-CANFD To:PAS,RPAS";
CM_ SG_ 515 HUT_OD_Obj4_ID "ID of the Target obstacleADAS-CANFD To:PAS,RPAS";
CM_ SG_ 515 HUT_OD_Obj4_type "OD_typeADAS-CANFD To:PAS,RPAS";
CM_ SG_ 515 HUT_OD_Obj4_Confidence "Confidence of the Target obstacleADAS-CANFD To:PAS,RPAS";
CM_ SG_ 515 HUT_OD_Obj4_width "Width of the Target obstacleADAS-CANFD To:PAS,RPAS";
CM_ SG_ 515 HUT_OD_Obj4_Ground_Pos_X "X-Axis Position of the Target obstacleADAS-CANFD To:PAS,RPAS";
CM_ SG_ 515 HUT_OD_Obj4_Ground_Pos_Y "Y-Axis Position of the Target obstacleADAS-CANFD To:PAS,RPAS";
CM_ SG_ 515 HUT_OD_Obj5_ID "ID of the Target obstacleADAS-CANFD To:PAS,RPAS";
CM_ SG_ 515 HUT_OD_Obj5_type "OD_typeADAS-CANFD To:PAS,RPAS";
CM_ SG_ 515 HUT_OD_Obj5_Confidence "Confidence of the Target obstacleADAS-CANFD To:PAS,RPAS";
CM_ SG_ 515 HUT_OD_Obj5_width "Width of the Target obstacleADAS-CANFD To:PAS,RPAS";
CM_ SG_ 515 HUT_OD_Obj5_Ground_Pos_X "X-Axis Position of the Target obstacleADAS-CANFD To:PAS,RPAS";
CM_ SG_ 515 HUT_OD_Obj5_Ground_Pos_Y "Y-Axis Position of the Target obstacleADAS-CANFD To:PAS,RPAS";
CM_ SG_ 515 HUT_OD_Obj6_ID "ID of the Target obstacleADAS-CANFD To:PAS,RPAS";
CM_ SG_ 515 HUT_OD_Obj6_type "OD_typeADAS-CANFD To:PAS,RPAS";
CM_ SG_ 515 HUT_OD_Obj6_Confidence "Confidence of the Target obstacleADAS-CANFD To:PAS,RPAS";
CM_ SG_ 515 HUT_OD_Obj6_width "Width of the Target obstacleADAS-CANFD To:PAS,RPAS";
CM_ SG_ 515 HUT_OD_Obj6_Ground_Pos_X "X-Axis Position of the Target obstacleADAS-CANFD To:PAS,RPAS";
CM_ SG_ 515 HUT_OD_Obj6_Ground_Pos_Y "Y-Axis Position of the Target obstacleADAS-CANFD To:PAS,RPAS";
CM_ SG_ 579 HUT_OD_Obj7_ID "ID of the Target obstacleADAS-CANFD To:PAS,RPAS";
CM_ SG_ 579 HUT_OD_Obj7_type "OD_typeADAS-CANFD To:PAS,RPAS";
CM_ SG_ 579 HUT_OD_Obj7_Confidence "Confidence of the Target obstacleADAS-CANFD To:PAS,RPAS";
CM_ SG_ 579 HUT_OD_Obj7_width "Width of the Target obstacleADAS-CANFD To:PAS,RPAS";
CM_ SG_ 579 HUT_OD_Obj7_Ground_Pos_X "X-Axis Position of the Target obstacleADAS-CANFD To:PAS,RPAS";
CM_ SG_ 579 HUT_OD_Obj7_Ground_Pos_Y "Y-Axis Position of the Target obstacleADAS-CANFD To:PAS,RPAS";
CM_ SG_ 579 AutoSpdSetSwt "switch for adjusting cruise speed automatically Ã¨Â‡ÂªÃ¥ÂŠÂ¨Ã¨Â°ÂƒÃ¨ÂŠÂ‚Ã¨Â½Â¦Ã¨Â¾Â†Ã©Â™ÂÃ©Â€ÂŸÃ¥ÂŠÂŸÃ¨ÂƒÂ½Ã¥Â¼Â€Ã¥Â…Â³(Ã¦ÂŒÂ‰Ã¨Â®Â°Ã¥Â½Â•Ã§ÂšÂ„Ã§ÂŠÂ¶Ã¦Â€ÂÃ¨Â¿Â›Ã¨Â¡ÂŒÃ¥ÂÂ‘Ã©Â€Â)ADAS1_CAN:To ICU1.5";
CM_ SG_ 579 LaneChngCfmSwt "switch for manual confirmation of lane change Ã§Â”Â¨Ã¦ÂˆÂ·Ã©Â€ÂšÃ¨Â¿Â‡Ã¤Â¸Â­Ã¦ÂŽÂ§Ã¨Â®Â¾Ã§Â½Â®Ã§Â•ÂŒÃ©ÂÂ¢Ã¨Â®Â¾Ã§Â½Â®Ã¦Â„ÂÃ¥Â›Â¾Ã§Â¡Â®Ã¨Â®Â¤Ã¥ÂŠÂŸÃ¨ÂƒÂ½Ã¤Â¸ÂºÃ¥Â¼Â€Ã¥ÂÂ¯Ã¦ÂˆÂ–Ã¥Â…Â³Ã©Â—Â­ADAS1_CAN:To ICU1.5";
CM_ SG_ 579 VoiceBrdcSwt "Switch for adas voice broadcastÃ§Â”Â¨Ã¦ÂˆÂ·Ã¦Â‰Â“Ã¥Â¼Â€Ã¥Â’ÂŒÃ¥Â…Â³Ã©Â—Â­Ã¨Â¯Â­Ã©ÂŸÂ³Ã¦Â’Â­Ã¦ÂŠÂ¥Ã§ÂšÂ„Ã¦ÂƒÂ…Ã¥Â†ÂµÃ¯Â¼ÂˆÃ§Â”Â¨Ã¤ÂºÂŽÃ¦Â•Â°Ã¦ÂÂ®Ã¥Â›ÂžÃ¤Â¼Â Ã¯Â¼Â‰ADAS1_CAN:To ICU1.5";
CM_ SG_ 579 UsrManSts "survey of user manual usage Ã§Â”Â¨Ã¦ÂˆÂ·Ã¦Â‰Â“Ã¥Â¼Â€Ã¥Â’ÂŒÃ¥Â…Â³Ã©Â—Â­Ã¦Â–Â°Ã¦Â‰Â‹Ã¦Â•Â™Ã§Â¨Â‹Ã§ÂšÂ„Ã¦ÂƒÂ…Ã¥Â†ÂµÃ¯Â¼ÂˆÃ§Â”Â¨Ã¤ÂºÂŽÃ¦Â•Â°Ã¦ÂÂ®Ã¥Â›ÂžÃ¤Â¼Â Ã¯Â¼Â‰ADAS1_CAN:To ICU1.5";
CM_ SG_ 579 HUT_OD_WorkSts "Working Status of HUT CameraADAS-CANFD To:PAS,RPAS";
CM_ SG_ 579 HUT_OD_Obj_Timestamp "Timestamp of detecting the targetADAS-CANFD To:PAS,RPAS";
CM_ SG_ 579 HUT_FSD1_distance "Freespace_distance to pointADAS-CANFD To:PAS,RPAS";
CM_ SG_ 579 HUT_FSD2_distance "Freespace_distance to pointADAS-CANFD To:PAS,RPAS";
CM_ SG_ 579 HUT_FSD3_distance "Freespace_distance to pointADAS-CANFD To:PAS,RPAS";
CM_ SG_ 579 HUT_FSD4_distance "Freespace_distance to pointADAS-CANFD To:PAS,RPAS";
CM_ SG_ 579 HUT_FSD5_distance "Freespace_distance to pointADAS-CANFD To:PAS,RPAS";
CM_ SG_ 579 HUT_FSD6_distance "Freespace_distance to pointADAS-CANFD To:PAS,RPAS";
CM_ SG_ 579 HUT_FSD7_distance "Freespace_distance to pointADAS-CANFD To:PAS,RPAS";
CM_ SG_ 579 HUT_FSD8_distance "Freespace_distance to pointADAS-CANFD To:PAS,RPAS";
CM_ SG_ 579 HUT_FSD9_distance "Freespace_distance to pointADAS-CANFD To:PAS,RPAS";
CM_ SG_ 579 HUT_FSD10_distance "Freespace_distance to pointADAS-CANFD To:PAS,RPAS";
CM_ SG_ 579 HUT_FSD11_distance "Freespace_distance to pointADAS-CANFD To:PAS,RPAS";
CM_ SG_ 579 HUT_FSD12_distance "Freespace_distance to pointADAS-CANFD To:PAS,RPAS";
CM_ SG_ 579 HUT_FSD13_distance "Freespace_distance to pointADAS-CANFD To:PAS,RPAS";
CM_ SG_ 579 HUT_FSD14_distance "Freespace_distance to pointADAS-CANFD To:PAS,RPAS";
CM_ SG_ 579 HUT_FSD15_distance "Freespace_distance to pointADAS-CANFD To:PAS,RPAS";
CM_ SG_ 579 HUT_FSD16_distance "Freespace_distance to pointADAS-CANFD To:PAS,RPAS";
CM_ SG_ 579 HUT_FSD17_distance "Freespace_distance to pointADAS-CANFD To:PAS,RPAS";
CM_ SG_ 579 HUT_FSD18_distance "Freespace_distance to pointADAS-CANFD To:PAS,RPAS";
CM_ SG_ 579 NOH_Swt_Req "Indicate Switch  of NOH switch statusADAS_CAN:To ICU1.5";
CM_ SG_ 579 NOH_Act_Req "Indicate Switch  of NOH activate statusADAS_CAN:To ICU1.5";
CM_ SG_ 474 SlotNum_VR "select parking lot through voice controlÃ©ÂÂ¥Ã¦ÂŽÂ§Ã¦ÂÂœÃ§Â´Â¢Ã¨Â½Â¦Ã¤Â½ÂÃ¥ÂŠÂŸÃ¨ÂƒÂ½Ã¥Â¢ÂžÃ¥ÂŠÂ Ã§ÂšÂ„HUTÃ¥ÂÂ‘Ã¥Â‡ÂºÃ§ÂšÂ„Ã¥Â£Â°Ã©ÂŸÂ³Ã¦ÂŽÂ§Ã¥ÂˆÂ¶Ã©Â€Â‰Ã¨Â½Â¦Ã¤Â½ÂÃ¥ÂÂ·Ã¤Â¿Â¡Ã¥ÂÂ·ADAS1_CAN:To ICU1.5";
CM_ SG_ 474 UserDefinedParkCmd "Used to configure the display mothod of guidance overlay
Ã§Â”Â¨Ã¦ÂˆÂ·Ã§Â‚Â¹Ã¥Â‡Â»Ã¨Â‡ÂªÃ©Â€Â‰Ã¨Â½Â¦Ã¤Â½ÂÃ¨Â½Â¯Ã¦ÂŒÂ‰Ã©Â”Â®ADAS1_CAN:To ICU1.5";
CM_ SG_ 474 HUT_HAVP_Set_Starting "Starting point button status
Ã§Â”Â¨Ã¦ÂˆÂ·Ã¦ÂŒÂ‰Ã©Â”Â®Ã¨Â®Â¾Ã§Â½Â®Ã¨ÂµÂ·Ã§Â‚Â¹ADAS1_CAN:To ICU1.5";
CM_ SG_ 474 HUT_HAVP_Set_Path_Ending "Set path ending pointÃ§Â”Â¨Ã¦ÂˆÂ·Ã¦ÂŒÂ‰Ã©Â”Â®Ã¨Â®Â¾Ã§Â½Â®Ã§Â»ÂˆÃ§Â‚Â¹ADAS1_CAN:To ICU1.5";
CM_ SG_ 474 HUT_HAVP_APA_Permit "HAVP auto parking in permitÃ¨Â®Â°Ã¥Â¿Â†Ã¦Â³ÂŠÃ¨Â½Â¦Ã¨Â‡ÂªÃ¥ÂŠÂ¨Ã¦Â³ÂŠÃ¥Â…Â¥Ã¨Â¯Â¢Ã©Â—Â®Ã§Â¡Â®Ã¨Â®Â¤ADAS1_CAN:To ICU1.5";
CM_ SG_ 474 UserDefPrkMenuSelCmd "Used to configure the display mothod of guidance overlay
Ã§Â”Â¨Ã¦ÂˆÂ·Ã¥ÂœÂ¨Ã¨Â‡ÂªÃ©Â€Â‰Ã¨Â½Â¦Ã¤Â½ÂÃ¥ÂŠÂŸÃ¨ÂƒÂ½Ã¤Â¸Â‹Ã©Â€Â‰Ã¦Â‹Â©Ã¦Â°Â´Ã¥Â¹Â³Ã¨Â½Â¦Ã¤Â½ÂÃ£Â€ÂÃ¥Â¹Â³Ã¨Â¡ÂŒÃ¨Â½Â¦Ã¤Â½ÂÃ¦ÂˆÂ–Ã©Â¡ÂºÃ¦Â—Â¶Ã©Â’ÂˆÃ£Â€ÂÃ©Â€Â†Ã¦Â—Â¶Ã©Â’ÂˆÃ¦Â—Â‹Ã¨Â½Â¬ADAS1_CAN:To ICU1.5";
CM_ SG_ 474 HUT_HAVP_SelfParLot_Ending "Set self-select parking lot to endingÃ§Â”Â¨Ã¦ÂˆÂ·Ã¦ÂŒÂ‰Ã©Â”Â®Ã¨Â®Â¾Ã§Â½Â®Ã§Â›Â®Ã¥Â‰ÂÃ¨Â½Â¦Ã¤Â½ÂÃ¤Â¸ÂºÃ§Â»ÂˆÃ§Â‚Â¹ADAS1_CAN:To ICU1.5";
CM_ SG_ 474 HUT_HAVP_Return_Btn "HAVP return button
Ã¨Â½Â¦Ã¦ÂœÂºÃ§Â«Â¯Ã¨Â®Â°Ã¥Â¿Â†Ã¦Â³ÂŠÃ¨Â½Â¦Ã¥ÂŠÂŸÃ¨ÂƒÂ½Ã¨Â¿Â”Ã¥Â›ÂžÃ¦ÂŒÂ‰Ã©Â”Â®ADAS1_CAN:To ICU1.5";
CM_ SG_ 475 HUT_ExternalDevice "HUT_DOCK External Device";
CM_ SG_ 871 DomeLmpDlyTimSet "Dome lamp delay time set:3s 10s2030s.";
CM_ SG_ 871 FolwMeHomeDlyTimSet "Follow me home delay time set:0s 30s60s90s.";
CM_ SG_ 871 TranPMode_Req "Transport Mode Switch";
CM_ SG_ 871 RearviewFoldModSet "Rearview mirror fold mode set";
CM_ SG_ 871 BattSaveDelayTimeSet "Battery saver delay time set:2m5m8m.";
CM_ SG_ 871 ACDualReq_TC "AC(Air Conditioning) Dual Request-Touch ControlBD1-CAN To:AC";
CM_ SG_ 871 ACAutoModReq_TC "AC(Air Conditioning) Auto Mode Request-Touch ControlBD1-CAN To:AC";
CM_ SG_ 871 ACAirInletReq_TC "AC(Air Conditioning) FreshRecirculation mode request-Touch ControlBD1-CAN To:AC";
CM_ SG_ 871 ACFrntHMIDis_TC "Front HMI display -Touch ControlBD1-CAN To:AC";
CM_ SG_ 871 ACRearHMIDis_TC "Rear HMI display -Touch ControlBD1-CAN To:AC";
CM_ SG_ 871 ACAQSReq_TC "AC(Air Conditioning) AQS(air quality sensor)  Request-Touch ControlBD1-CAN To:AC";
CM_ SG_ 871 ACCmprReq_TC "AC(Air Conditioning) Compressor request -Touch ControlBD1-CAN To:AC";
CM_ SG_ 871 ACFrntDefrstReq_TC "AC(Air Conditioning) Front Defrost OnOff  request-Touch ControlBD1-CAN To:AC";
CM_ SG_ 871 ACFrntBlwrSpdDecReq_TC "AC(Air Conditioning) Front Blower Speed Decrease request -Touch ControlBD1-CAN To:AC";
CM_ SG_ 871 ACRearBlwrSpdDecReq_TC "AC(Air Conditioning) Rear Blower Speed Decrease request -Touch ControlBD1-CAN To:AC";
CM_ SG_ 871 ACRearBlwrSpdIncReq_TC "AC(Air Conditioning) Rear Blower Speed Increase  Request-Touch ControlBD1-CAN To:AC";
CM_ SG_ 871 DrvDrowsnsDetnSet "DMS(Driver Monitoring System) Driver drowsiness detection set";
CM_ SG_ 871 ACFrntBlwrSpdIncReq_TC "AC(Air Conditioning) Front Blower Speed Increase  Request-Touch ControlBD1-CAN To:AC";
CM_ SG_ 871 ACDrvAirDistribModReq_TC "AC(Air Conditioning) Driver Air Distribution Mode Request-Touch ControlBD1-CAN To:AC";
CM_ SG_ 871 ACDrvTempDecReq_TC "AC(Air Conditioning) Driver Temperature Decrease Request-Touch ControlBD1-CAN To:AC";
CM_ SG_ 871 ChairMemPosnEna "Chair  memory position enable";
CM_ SG_ 871 ACDrvTempIncReq_TC "AC(Air Conditioning) Driver Temperature Increase  Request-Touch ControlBD1-CAN To:AC";
CM_ SG_ 871 ACFrntPassTempDecReq_TC "AC(Air Conditioning) Front passenger Temperature Decrease Request-Touch ControlBD1-CAN To:AC";
CM_ SG_ 871 ACFrntPassTempIncReq_TC "AC(Air Conditioning) Front passenger Temperature Increase Request-Touch ControlBD1-CAN To:AC";
CM_ SG_ 871 ACAIUReq_TC "Control AC(Air Conditioning) Air Ionizer Unit Request-Touch ControlBD1-CAN To:AC";
CM_ SG_ 871 ACOffReq_TC "Turn Off AC(Air Conditioning) Request by HUT(Head Unit System)-Touch ControlBD1-CAN To:AC";
CM_ SG_ 871 ACBlwrsteplsSpdReq_TC "Blower Stepless speed request for AC(Air Conditioning) controlling-Touch ControlBD1-CAN To:AC";
CM_ SG_ 871 ACZoneReq_TC "Zone Request-Touch ControlBD1-CAN To:AC";
CM_ SG_ 68 ALCMStatSwt_OLE "Unlimited ALCM(Ambient Light Control Module) static switch";
CM_ SG_ 68 ALCMClrSet_OLE "Unlimited ALCM(Ambient Light Control Module) colour set";
CM_ SG_ 68 ALCMDynModSet_OLE "Unlimited ALCM(Ambient Light Control Module) dynamic switch";
CM_ SG_ 68 ALCMLightLvlSet_OLE "ALCM(Ambient Light Control Module) Light level set";
CM_ SG_ 68 ALCMRhmSwt_OLE "ALCM(Ambient Light Control Module) rhythm switch";
CM_ SG_ 68 ALCMBreSwt_OLE "ALCM(Ambient Light Control Module) breathing switch";
CM_ SG_ 68 ALCMRdmSwt_OLE "ALCM(Ambient Light Control Module) random switch outline";
CM_ SG_ 68 Rdm_SingleColorNr "Random Single color number";
CM_ SG_ 68 HUT_VMDRTmpMonFctnSet "VMDR Temporary monitoring function set";
CM_ SG_ 68 HUT_VMDRInitAlarmDlySet "VMDR Initial alarm delay set";
CM_ SG_ 68 OTA_UpgrdModReq "HUT triggers OTA requests";
CM_ SG_ 817 ACDualReq_VR "AC(Air Conditioning) Dual Request(Voice Request)BD1-CAN To:AC";
CM_ SG_ 817 ACAQSReq_VR "AC(Air Conditioning) AQS(air quality sensor) Request(Voice Request)BD1-CAN To:AC";
CM_ SG_ 817 ACRearDefrstReq_VR "AC(Air Conditioning) Rear Defrost request(Voice Request)BD1-CAN To:AC";
CM_ SG_ 817 ACPassTempReq_VR "AC(Air Conditioning) Front Passenger Temperature Requset(Voice Request)BD1-CAN To:AC";
CM_ SG_ 817 ACAIUReq_VR "AC(Air Conditioning) Control Air Ionizer Unit Request(Voice Request)BD1-CAN To:AC";
CM_ SG_ 817 ALCMStatSwt "Unlimited ALCM(Ambient Light Control Module) static switch";
CM_ SG_ 817 ALCMDynSwt "Unlimited ALCM(Ambient Light Control Module) dynamic switch";
CM_ SG_ 817 ALCMClrSet "Unlimited ALCM(Ambient Light Control Module) colour set";
CM_ SG_ 817 ALCMRhmSwt "ALCM(Ambient Light Control Module) rhythm switch";
CM_ SG_ 817 IPVolSet "IP Volume SetBD2-CAN To:AMP";
CM_ SG_ 817 PASSwtReq_VR "Radar switch Request(Voice Request)";
CM_ SG_ 817 HUT_BeanIDReq "Bluetooth bean ID request by HUTBD1-CAN To:BLE";
CM_ SG_ 817 HUT_EgyRecvrySet "HUT energy recovery setHC_CAN:To PDCU";
CM_ SG_ 943 WeatherCdn "Weather Condition";
CM_ SG_ 943 PitchAng "Pitch Angle";
CM_ SG_ 943 PitchAngSign "Pitch Angle Sign";
CM_ SG_ 796 AudioMuteSts "Audio Mute Status.";
CM_ SG_ 796 OrvmPosnEnaSts "Outside rear view mirror position set enable ststus";
CM_ SG_ 796 ORVMFoldSwt_HUT "Outside rear-view mirror folding switch";
CM_ SG_ 796 ORVMLensAdjmt_HUT "Lens adjustment for Outside rear-view mirror";
CM_ SG_ 796 DrvSeatAdjmt_HUT "Driver seat adjustment";
CM_ SG_ 796 DrivingModReq_VR "Drive mode voice request
Ã©Â©Â¾Ã©Â©Â¶Ã¦Â¨Â¡Ã¥Â¼ÂÃ¨Â¯Â­Ã©ÂŸÂ³Ã¦ÂŽÂ§Ã¥ÂˆÂ¶Ã¨Â¯Â·Ã¦Â±Â‚Ã¤Â¿Â¡Ã¥ÂÂ·";
CM_ SG_ 796 DWD_WorkCmd "DWD work command";
CM_ SG_ 796 DampgDrvModeReq "damping drive mode request";
CM_ SG_ 796 VSGSwtSet "Control VSG switch onoff setHC_CAN:To PDCU";
CM_ SG_ 494 ACOperMod_TC "AC(Air Conditioning) operation mode request-Touch ControlBD1-CAN To:AC";
CM_ SG_ 494 ACOperMod_VR "AC(Air Conditioning) operation mode request (Voice Request)BD1-CAN To:AC";
CM_ SG_ 494 ACDrvSetTempSteplsReq_TC "AC(Air Conditioning) Driver Set Temperature Stepless Request-Touch ControlBD1-CAN To:AC";
CM_ SG_ 494 ACPassSetTempSteplsReq_TC "AC(Air Conditioning) Passenger Set Temperature Stepless Request-Touch ControlBD1-CAN To:AC";
CM_ SG_ 494 SDWSwtSet "Side Distance Warning  switch SetADAS-CANFD To:HAP";
CM_ SG_ 494 APSSwtReq_VR "APS(Automatic Parking System) switch request(Voice Request)ADAS-CANFD To:HAP";
CM_ SG_ 494 APSPrkgTypSeln "APS(Automatic Parking System) parking type selectionADAS-CANFD To:HAP";
CM_ SG_ 494 SunShadeSwtReq_VR "Sun shade switch request(Voice Request)";
CM_ SG_ 494 SunRoofSwtReq_VR "Sun roof switch request(Voice Request)";
CM_ SG_ 494 SportModLightSet "The light mode set in the sport mode";
CM_ SG_ 494 ABSLmpSet "ABS Lamp Setting";
CM_ SG_ 494 AutoWshWipSet "Auto Wash Wipe Setting";
CM_ SG_ 494 SeekVehSet "Seek Vehicle Setting";
CM_ SG_ 494 SpdAutoLockModSet "Speed Auto Lock Mode Setting";
CM_ SG_ 494 ParkLmpSet "Set the park lamp state";
CM_ SG_ 494 DoorUnlockModSet "Door  Unlock Mode Setting";
CM_ SG_ 494 SteerWheelHeatSwtReq "Steer wheel Heating Switch Request by HUTBD1-CAN To:CSA";
CM_ SG_ 494 PASExitSpdSwt "PAS exit speed switch";
CM_ SG_ 494 FrntRearACDispSts "Feedback current front&rear AC display status on HMIBD1-CAN To:AC";
CM_ SG_ 494 MAC_Check_HUT15 "MAC protection mechanism should comply with the GWM MAC Specificatio";
CM_ SG_ 840 PowerSet "AMP power set. When the systerm power mode (from PEPS or BCM)change to OFF,the bluetooh communication should't be interrupted ,so AMP need this signal to turn off.BD2_CAN:To AMP";
CM_ SG_ 840 HUT_CallSts_Dialing "Call_Status(Dialing)";
CM_ SG_ 840 HUT_CallSts_IncomingCall "Call_Status(Incoming Call)";
CM_ SG_ 840 HUT_CallSts_ongoing "Call_Status(ongoing Call)";
CM_ SG_ 840 HUT_CallTime "Call Duration";
CM_ SG_ 827 BackgroundLightLvlSet "Back ground Light level Set";
CM_ SG_ 827 ManCmpSet "Manual compensation setÃ§Â‹Â¬Ã§Â«Â‹AMP";
CM_ SG_ 827 DispModSet "Display Mode SetÃ§Â‹Â¬Ã§Â«Â‹AMP";
CM_ SG_ 827 WPC_SwtReq "Request of WPC(Wireless Power Charger) SwitchBD1-CAN To:WPC";
CM_ SG_ 827 AVMSwtReq "AVM(Around View Monitoring) switch requestBD2_CAN:To AMP";
CM_ SG_ 827 NaviMediaVolLvlReq "Navigation Media Volume Level RequestBD2_CAN:To AMP";
CM_ SG_ 827 AVMMediaVolLvlReq "AVM(Around View Monitoring) Media Volume Level RequestBD2_CAN:To AMP";
CM_ SG_ 827 FPASChanSwtReq "Front  Park Assistant System channel Status RequestBD2_CAN:To AMP";
CM_ SG_ 827 RPASChanSwtReq "Rear Park Assistant System channel Status RequestBD2_CAN:To AMP";
CM_ SG_ 827 ACRearBlwrSpdReq_VR "Blower speed request  for rear AC(Air Conditioning) controlling(Voice Request)BD1-CAN:To AC";
CM_ SG_ 827 ACRearBlwrsteplsSpdReq_TC "Blower Stepless speed request for rear AC(Air Conditioning) controlling-Touch ControlBD1-CAN:To AC";
CM_ SG_ 827 PLGReq_VR "Power Lift Gate Module request by HUT(Voice Request)";
CM_ SG_ 827 ACRearAirDistribModReq_VR "AC(Air Conditioning) Rear Air Distribution Mode Request-Touch ControlBD1-CAN:To AC";
CM_ SG_ 827 ACZoneReq_VR "AC(Air Conditioning) Zone Request(Voice Request)BD1-CAN:To AC";
CM_ SG_ 827 OPDSwtSts "One Pedal driving Switch StatusPT-CANFD To:PDCU";
CM_ SG_ 1045 ADAS_Meta_MsgTyp "Identify type of messageADAS-CANFD To:PAS,RPAS";
CM_ SG_ 1045 ADAS_Meta_MapProvider "Provider mapADAS-CANFD To:PAS,RPAS";
CM_ SG_ 1045 ADAS_Meta_CountryCode "CountryCodeADAS-CANFD To:PAS,RPAS";
CM_ SG_ 1045 ADAS_Meta_CycCnt "Message rollingcounterADAS-CANFD To:PAS,RPAS";
CM_ SG_ 1045 ADAS_Meta_ProtVer_Major "Main protocol versionADAS-CANFD To:PAS,RPAS";
CM_ SG_ 1045 ADAS_Meta_ProtVer_MinorSub "Minor protocol versionADAS-CANFD To:PAS,RPAS";
CM_ SG_ 1045 ADAS_Meta_HwVer "Hardwar version or software versionADAS-CANFD To:PAS,RPAS";
CM_ SG_ 1045 ADAS_Meta_DrvSide "Driving directionADAS-CANFD To:PAS,RPAS";
CM_ SG_ 1045 ADAS_Meta_RegionCode "Region CodeADAS-CANFD To:PAS,RPAS";
CM_ SG_ 1045 ADAS_Meta_MapVerQtr "Map version quarterlyADAS-CANFD To:PAS,RPAS";
CM_ SG_ 1045 ADAS_Meta_MapVerYear "Map version yearADAS-CANFD To:PAS,RPAS";
CM_ SG_ 1045 ADAS_Meta_SpdUnits "speed limit unitADAS-CANFD To:PAS,RPAS";
CM_ SG_ 1045 ADAS_Meta_ProtVer_Minor "Minor protocol versionADAS-CANFD To:PAS,RPAS";
CM_ SG_ 873 RearWinHeatCmd_TC "Rear Window Heating OnOff request-Touch ControlBD1-CAN To:AC";
CM_ SG_ 873 AMP_MediaCallSourceSet "MediaCall Source SetBD2-CAN To:AMP";
CM_ SG_ 873 AMP_NaviSourceSet "Navigation source set.BD2-CAN To:AMP";
CM_ SG_ 873 AMP_BeepSourceSet "Beep source set.BD2-CAN To:AMP";
CM_ SG_ 873 AMP_LRAudioBalanceSet "LeftRight Audio Balance setBD2-CAN To:AMP";
CM_ SG_ 873 AMP_AudioVolVSCModReq "Audio volume Vehicle Speed Compensation mode(onoff) request.BD2-CAN To:AMP";
CM_ SG_ 873 AMP_FRAudioFaderSet "Frontrear audio fader setBD2-CAN To:AMP";
CM_ SG_ 873 AMP_LRDrvSideSet "Drive side set(Left helm drive or right helm drive).BD2-CAN To:AMP";
CM_ SG_ 873 AMP_LowFrqAudioSet "Low frequency audio setBD2-CAN To:AMP";
CM_ SG_ 873 AMP_MuteSet "Mute all speakersBD2-CAN To:AMP";
CM_ SG_ 873 AMP_MidFrqAudioSet "Mid frequency audio setBD2-CAN To:AMP";
CM_ SG_ 873 AMP_HighFrqAudioSet "Middle frequency audio setBD2-CAN To:AMP";
CM_ SG_ 873 T_box_ECallSet "T_box Ecall(emergency call)  set (mute all speakers).When T_Box Ecall occurred,HUT sent this signal to AMP mute all speakers,off is not mute,on is mute.BD2-CAN To:AMP";
CM_ SG_ 873 QLISurroundSet "quantum logic surround or Stereo set.BD2-CAN To:AMP";
CM_ SG_ 873 ANCSwtSet "ANC(Active Noise Control) function switch set.BD2-CAN To:AMP";
CM_ SG_ 734 ADAS_ProfLong_MsgTyp "Identify type of messageADAS-CANFD To:IFC,IDC_L2";
CM_ SG_ 734 ADAS_ProfLong_Offset "Displacement duration between start position and profile spotADAS-CANFD To:IFC,IDC_L2";
CM_ SG_ 734 ADAS_ProfLong_CycCnt "Message rollingcounterADAS-CANFD To:IFC,IDC_L2";
CM_ SG_ 734 ADAS_ProfLong_PathIdx "ADAS_ProfLong_PathIdxADAS-CANFD To:IFC,IDC_L2";
CM_ SG_ 734 ADAS_ProfLong_ProfTyp "profile long typeADAS-CANFD To:IFC,IDC_L2";
CM_ SG_ 734 ADAS_ProfLong_CtrlPoint "Contrl pointADAS-CANFD To:IFC,IDC_L2";
CM_ SG_ 734 ADAS_ProfLong_Retr "ADAS_ProfLong_RetrADAS-CANFD To:IFC,IDC_L2";
CM_ SG_ 734 ADAS_ProfLong_Update "profile long  updateADAS-CANFD To:IFC,IDC_L2";
CM_ SG_ 734 ADAS_ProfLong_Value "profile long valueADAS-CANFD To:IFC,IDC_L2";
CM_ SG_ 733 ADAS_ProfShort_MsgTyp "Identify type of messageADAS-CANFD To:IFC,IDC_L2";
CM_ SG_ 733 ADAS_ProfShort_Offset "Displacement duration between start position and profile spotADAS-CANFD To:IFC,IDC_L2";
CM_ SG_ 733 ADAS_ProfShort_CycCnt "Message rollingcounterADAS-CANFD To:IFC,IDC_L2";
CM_ SG_ 733 ADAS_ProfShort_PathIdx "ADAS_ProfShort_PathIdxADAS-CANFD To:IFC,IDC_L2";
CM_ SG_ 733 ADAS_ProfShort_ProfTyp "profile short  typeADAS-CANFD To:IFC,IDC_L2";
CM_ SG_ 733 ADAS_ProfShort_CtrlPoint "Contrl pointADAS-CANFD To:IFC,IDC_L2";
CM_ SG_ 733 ADAS_ProfShort_Retr "ADAS_ProfShort_RetrADAS-CANFD To:IFC,IDC_L2";
CM_ SG_ 733 ADAS_ProfShort_Update "Profile short updateADAS-CANFD To:IFC,IDC_L2";
CM_ SG_ 733 ADAS_ProfShort_AccurClass "AccuracyADAS-CANFD To:IFC,IDC_L2";
CM_ SG_ 733 ADAS_ProfShort_Dist1 "Distance from the first profile spot to the second profile spotADAS-CANFD To:IFC,IDC_L2";
CM_ SG_ 733 ADAS_ProfShort_Value0 "Profile value in offsetADAS-CANFD To:IFC,IDC_L2";
CM_ SG_ 733 ADAS_ProfShort_Value1 "profile value in offset+distance1ADAS-CANFD To:IFC,IDC_L2";
CM_ SG_ 730 ADAS_Seg_MsgTyp "Identify type of messageADAS-CANFD To:IFC,IDC_L2";
CM_ SG_ 730 ADAS_Seg_Offset "Distance from segment start to Path startADAS-CANFD To:IFC,IDC_L2";
CM_ SG_ 730 ADAS_Seg_CycCnt "Message rollingcounterADAS-CANFD To:IFC,IDC_L2";
CM_ SG_ 730 ADAS_Seg_PathIdx "ADAS_Seg_PathIdxADAS-CANFD To:IFC,IDC_L2";
CM_ SG_ 730 ADAS_Seg_Tunnel "segment tunnel informationADAS-CANFD To:IFC,IDC_L2";
CM_ SG_ 730 ADAS_Seg_Brdg "segment bridge informationADAS-CANFD To:IFC,IDC_L2";
CM_ SG_ 730 ADAS_Seg_BuildUpArea "segment position informationADAS-CANFD To:IFC,IDC_L2";
CM_ SG_ 730 ADAS_Seg_Retr "ADAS_Seg_RetrADAS-CANFD To:IFC,IDC_L2";
CM_ SG_ 730 ADAS_Seg_Update "Segment updateADAS-CANFD To:IFC,IDC_L2";
CM_ SG_ 730 ADAS_Seg_RelProbb "ADAS_Seg_RelProbbADAS-CANFD To:IFC,IDC_L2";
CM_ SG_ 730 ADAS_Seg_FuncRoadClass "segment FRC informationADAS-CANFD To:IFC,IDC_L2";
CM_ SG_ 730 ADAS_Seg_PartOfCalcRoute "Whether segment plan path informationADAS-CANFD To:IFC,IDC_L2";
CM_ SG_ 730 ADAS_Seg_CmplxInsct "Complex intersection information from segmentADAS-CANFD To:IFC,IDC_L2";
CM_ SG_ 730 ADAS_Seg_FormOfWay "Roadfacilities information from segmentADAS-CANFD To:IFC,IDC_L2";
CM_ SG_ 730 ADAS_Seg_EffSpdLmt "Speed limt information from segmentADAS-CANFD To:IFC,IDC_L2";
CM_ SG_ 730 ADAS_Seg_EffSpdLmtTyp "Effective speed limt type information segmentADAS-CANFD To:IFC,IDC_L2";
CM_ SG_ 730 ADAS_Seg_DivideRoad "Isolation dtrip information from segmentADAS-CANFD To:IFC,IDC_L2";
CM_ SG_ 730 ADAS_Seg_NumOfLaneOppDir "Number of tfaffic lane in opposite  direction from segmentADAS-CANFD To:IFC,IDC_L2";
CM_ SG_ 730 ADAS_Seg_NumOfLaneDrvDir "Number of tfaffic lane in forward  direction from segmentADAS-CANFD To:IFC,IDC_L2";

BA_DEF_ BO_ "DiagRequest" ENUM  "No","Yes";
BA_DEF_ BO_ "DiagResponse" ENUM  "No","Yes";
BA_DEF_ BO_ "DiagState" ENUM  "No","Yes";
BA_DEF_ BO_ "GenMsgCycleTime" INT 0 65535;
BA_DEF_ BO_ "GenMsgCycleTimeFast" INT 0 65535;
BA_DEF_ BO_ "GenMsgILSupport" ENUM  "No","Yes";
BA_DEF_ BO_ "GenMsgNrOfRepetition" INT 0 65535;
BA_DEF_ BO_ "GenMsgSendType" ENUM  "Cyclic","CyclicAndSpontanX","Event";
BA_DEF_ BO_ "NmAsrMessage" ENUM  "No","Yes";
BA_DEF_ BO_ "OriginFrame" STRING;
BA_DEF_ BO_ "SCP_AuthInfoTxLength" INT 0 512;
BA_DEF_ BO_ "SCP_DataId" INT 0 65535;
BA_DEF_ BO_ "SCP_FreshnessValueLength" INT 0 512;
BA_DEF_ BO_ "SCP_FreshnessValueTxLength" INT 0 512;
BA_DEF_ BO_ "SC_Message" ENUM  "NO","YES";
BA_DEF_ BO_ "VFrameFormat" ENUM  "StandardCAN","ExtendedCAN","reserved","reserved","reserved","reserved","reserved","reserved","reserved","reserved","reserved","reserved","reserved","reserved","StandardCAN_FD","ExtendedCAN_FD";
BA_DEF_ SG_ "GenSigCycleTime" INT 0 65535;
BA_DEF_ SG_ "GenSigSendType" ENUM  "Cyclic","OnWrite","OnWriteWithRepetition","OnChange","OnChangeWithRepetition","NotUsed","NotUsed","NoSigSendType";
BA_DEF_ SG_ "GenSigStartValue" FLOAT 0 100000000000;
BA_DEF_ SG_ "Match" STRING;
BA_DEF_ SG_ "Origin" STRING;
BA_DEF_ SG_ "SystemSignalLongSymbol" STRING;
BA_DEF_DEF_ "DiagRequest" "No";
BA_DEF_DEF_ "DiagResponse" "No";
BA_DEF_DEF_ "DiagState" "No";
BA_DEF_DEF_ "GenMsgCycleTime" 0;
BA_DEF_DEF_ "GenMsgCycleTimeFast" 0;
BA_DEF_DEF_ "GenMsgILSupport" "No";
BA_DEF_DEF_ "GenMsgNrOfRepetition" 0;
BA_DEF_DEF_ "GenMsgSendType" "Cyclic";
BA_DEF_DEF_ "GenSigCycleTime" 0;
BA_DEF_DEF_ "GenSigSendType" "Cyclic";
BA_DEF_DEF_ "GenSigStartValue" 0;
BA_DEF_DEF_ "Match" "";
BA_DEF_DEF_ "NmAsrMessage" "No";
BA_DEF_DEF_ "Origin" "";
BA_DEF_DEF_ "OriginFrame" "";
BA_DEF_DEF_ "SCP_AuthInfoTxLength" 0;
BA_DEF_DEF_ "SCP_DataId" 0;
BA_DEF_DEF_ "SCP_FreshnessValueLength" 0;
BA_DEF_DEF_ "SCP_FreshnessValueTxLength" 0;
BA_DEF_DEF_ "SC_Message" "NO";
BA_DEF_DEF_ "SystemSignalLongSymbol" "";
BA_DEF_DEF_ "VFrameFormat" "";
BA_ "GenMsgCycleTime" BO_ 762 100;
BA_ "GenMsgILSupport" BO_ 762 1;
BA_ "OriginFrame" BO_ 762 "fuel,ev";
BA_ "VFrameFormat" BO_ 762 14;
BA_ "GenMsgCycleTime" BO_ 584 50;
BA_ "GenMsgILSupport" BO_ 584 1;
BA_ "OriginFrame" BO_ 584 "fuel,ev";
BA_ "VFrameFormat" BO_ 584 14;
BA_ "GenMsgCycleTime" BO_ 805 200;
BA_ "GenMsgILSupport" BO_ 805 1;
BA_ "OriginFrame" BO_ 805 "fuel,ev";
BA_ "VFrameFormat" BO_ 805 14;
BA_ "GenMsgCycleTime" BO_ 707 100;
BA_ "GenMsgILSupport" BO_ 707 1;
BA_ "OriginFrame" BO_ 707 "fuel,ev";
BA_ "SCP_AuthInfoTxLength" BO_ 707 48;
BA_ "SCP_DataId" BO_ 707 707;
BA_ "SCP_FreshnessValueLength" BO_ 707 64;
BA_ "SCP_FreshnessValueTxLength" BO_ 707 16;
BA_ "SC_Message" BO_ 707 1;
BA_ "VFrameFormat" BO_ 707 14;
BA_ "GenMsgCycleTime" BO_ 515 50;
BA_ "GenMsgILSupport" BO_ 515 1;
BA_ "OriginFrame" BO_ 515 "fuel,ev";
BA_ "VFrameFormat" BO_ 515 14;
BA_ "GenMsgCycleTime" BO_ 579 50;
BA_ "GenMsgILSupport" BO_ 579 1;
BA_ "OriginFrame" BO_ 579 "fuel,ev";
BA_ "VFrameFormat" BO_ 579 14;
BA_ "GenMsgCycleTimeFast" BO_ 474 20;
BA_ "GenMsgILSupport" BO_ 474 1;
BA_ "GenMsgNrOfRepetition" BO_ 474 5;
BA_ "GenMsgSendType" BO_ 474 2;
BA_ "OriginFrame" BO_ 474 "fuel,ev";
BA_ "VFrameFormat" BO_ 474 14;
BA_ "GenMsgCycleTimeFast" BO_ 475 20;
BA_ "GenMsgILSupport" BO_ 475 1;
BA_ "GenMsgNrOfRepetition" BO_ 475 5;
BA_ "GenMsgSendType" BO_ 475 2;
BA_ "OriginFrame" BO_ 475 "fuel,ev";
BA_ "VFrameFormat" BO_ 475 14;
BA_ "GenMsgCycleTimeFast" BO_ 871 20;
BA_ "GenMsgILSupport" BO_ 871 1;
BA_ "GenMsgNrOfRepetition" BO_ 871 5;
BA_ "GenMsgSendType" BO_ 871 2;
BA_ "OriginFrame" BO_ 871 "fuel,ev";
BA_ "VFrameFormat" BO_ 871 14;
BA_ "GenMsgCycleTimeFast" BO_ 68 20;
BA_ "GenMsgILSupport" BO_ 68 1;
BA_ "GenMsgNrOfRepetition" BO_ 68 5;
BA_ "GenMsgSendType" BO_ 68 2;
BA_ "OriginFrame" BO_ 68 "fuel,ev";
BA_ "VFrameFormat" BO_ 68 14;
BA_ "GenMsgCycleTimeFast" BO_ 817 20;
BA_ "GenMsgILSupport" BO_ 817 1;
BA_ "GenMsgNrOfRepetition" BO_ 817 5;
BA_ "GenMsgSendType" BO_ 817 2;
BA_ "OriginFrame" BO_ 817 "fuel,ev";
BA_ "VFrameFormat" BO_ 817 14;
BA_ "GenMsgCycleTime" BO_ 943 1000;
BA_ "GenMsgILSupport" BO_ 943 1;
BA_ "OriginFrame" BO_ 943 "fuel,ev";
BA_ "VFrameFormat" BO_ 943 14;
BA_ "GenMsgCycleTime" BO_ 796 100;
BA_ "GenMsgILSupport" BO_ 796 1;
BA_ "OriginFrame" BO_ 796 "fuel,ev";
BA_ "VFrameFormat" BO_ 796 14;
BA_ "GenMsgCycleTimeFast" BO_ 494 20;
BA_ "GenMsgILSupport" BO_ 494 1;
BA_ "GenMsgNrOfRepetition" BO_ 494 5;
BA_ "GenMsgSendType" BO_ 494 2;
BA_ "OriginFrame" BO_ 494 "fuel,ev";
BA_ "SCP_AuthInfoTxLength" BO_ 494 48;
BA_ "SCP_DataId" BO_ 494 494;
BA_ "SCP_FreshnessValueLength" BO_ 494 64;
BA_ "SCP_FreshnessValueTxLength" BO_ 494 16;
BA_ "SC_Message" BO_ 494 1;
BA_ "VFrameFormat" BO_ 494 14;
BA_ "GenMsgCycleTime" BO_ 840 500;
BA_ "GenMsgILSupport" BO_ 840 1;
BA_ "OriginFrame" BO_ 840 "fuel,ev";
BA_ "VFrameFormat" BO_ 840 14;
BA_ "GenMsgCycleTimeFast" BO_ 827 20;
BA_ "GenMsgILSupport" BO_ 827 1;
BA_ "GenMsgNrOfRepetition" BO_ 827 5;
BA_ "GenMsgSendType" BO_ 827 2;
BA_ "OriginFrame" BO_ 827 "fuel,ev";
BA_ "VFrameFormat" BO_ 827 14;
BA_ "GenMsgCycleTime" BO_ 1045 5000;
BA_ "GenMsgILSupport" BO_ 1045 1;
BA_ "OriginFrame" BO_ 1045 "fuel,ev";
BA_ "VFrameFormat" BO_ 1045 14;
BA_ "GenMsgCycleTimeFast" BO_ 873 20;
BA_ "GenMsgILSupport" BO_ 873 1;
BA_ "GenMsgNrOfRepetition" BO_ 873 5;
BA_ "GenMsgSendType" BO_ 873 2;
BA_ "OriginFrame" BO_ 873 "fuel,ev";
BA_ "VFrameFormat" BO_ 873 14;
BA_ "GenMsgCycleTimeFast" BO_ 734 20;
BA_ "GenMsgILSupport" BO_ 734 1;
BA_ "GenMsgNrOfRepetition" BO_ 734 5;
BA_ "GenMsgSendType" BO_ 734 2;
BA_ "OriginFrame" BO_ 734 "fuel,ev";
BA_ "VFrameFormat" BO_ 734 14;
BA_ "GenMsgCycleTimeFast" BO_ 733 20;
BA_ "GenMsgILSupport" BO_ 733 1;
BA_ "GenMsgNrOfRepetition" BO_ 733 5;
BA_ "GenMsgSendType" BO_ 733 2;
BA_ "OriginFrame" BO_ 733 "fuel,ev";
BA_ "VFrameFormat" BO_ 733 14;
BA_ "GenMsgCycleTimeFast" BO_ 730 20;
BA_ "GenMsgILSupport" BO_ 730 1;
BA_ "GenMsgNrOfRepetition" BO_ 730 5;
BA_ "GenMsgSendType" BO_ 730 2;
BA_ "OriginFrame" BO_ 730 "fuel,ev";
BA_ "VFrameFormat" BO_ 730 14;
BA_ "GenSigCycleTime" SG_ 762 HCU_TotalScore_P0 100;
BA_ "GenSigStartValue" SG_ 762 HCU_TotalScore_P0 5;
BA_ "Match" SG_ 762 HCU_TotalScore_P0 "HCU_TotalScore_P0";
BA_ "Origin" SG_ 762 HCU_TotalScore_P0 "fuel";
BA_ "GenSigCycleTime" SG_ 762 HCU_GearChngPorNTXT 100;
BA_ "Match" SG_ 762 HCU_GearChngPorNTXT "HCU_GearChngPorNTXT";
BA_ "Origin" SG_ 762 HCU_GearChngPorNTXT "fuel";
BA_ "GenSigCycleTime" SG_ 762 HCU_SOCLow_Indcn 100;
BA_ "Match" SG_ 762 HCU_SOCLow_Indcn "HCU_SOCLow_Indcn";
BA_ "Origin" SG_ 762 HCU_SOCLow_Indcn "ev";
BA_ "GenSigCycleTime" SG_ 762 HCU_RemoveChrgLine_Indcn 100;
BA_ "Match" SG_ 762 HCU_RemoveChrgLine_Indcn "HCU_RemoveChrgLine_Indcn";
BA_ "Origin" SG_ 762 HCU_RemoveChrgLine_Indcn "ev";
BA_ "GenSigCycleTime" SG_ 762 HCU_Shift_P_Indcn 100;
BA_ "Match" SG_ 762 HCU_Shift_P_Indcn "HCU_Shift_P_Indcn";
BA_ "Origin" SG_ 762 HCU_Shift_P_Indcn "ev";
BA_ "GenSigCycleTime" SG_ 762 HCU_ConnectChrgLine_Indcn 100;
BA_ "Match" SG_ 762 HCU_ConnectChrgLine_Indcn "HCU_ConnectChrgLine_Indcn";
BA_ "Origin" SG_ 762 HCU_ConnectChrgLine_Indcn "ev";
BA_ "GenSigCycleTime" SG_ 762 HCU_EgyRecFB 100;
BA_ "Match" SG_ 762 HCU_EgyRecFB "HCU_EgyRecFB";
BA_ "Origin" SG_ 762 HCU_EgyRecFB "ev";
BA_ "GenSigCycleTime" SG_ 762 HCU_OilTankCoverSts 100;
BA_ "Match" SG_ 762 HCU_OilTankCoverSts "HCU_OilTankCoverSts";
BA_ "Origin" SG_ 762 HCU_OilTankCoverSts "ev";
BA_ "GenSigCycleTime" SG_ 762 HCU_InhbChrgInfo 100;
BA_ "Match" SG_ 762 HCU_InhbChrgInfo "HCU_InhbChrgInfo";
BA_ "Origin" SG_ 762 HCU_InhbChrgInfo "ev";
BA_ "GenSigCycleTime" SG_ 762 ImdtlyChrgSts 100;
BA_ "Match" SG_ 762 ImdtlyChrgSts "ImdtlyChrgSts";
BA_ "Origin" SG_ 762 ImdtlyChrgSts "ev";
BA_ "GenSigCycleTime" SG_ 762 HCU_EnerSavePowerMod 100;
BA_ "Match" SG_ 762 HCU_EnerSavePowerMod "HCU_EnerSavePowerMod";
BA_ "Origin" SG_ 762 HCU_EnerSavePowerMod "ev";
BA_ "GenSigCycleTime" SG_ 762 HCU_RefuReq 100;
BA_ "Match" SG_ 762 HCU_RefuReq "HCU_RefuReq";
BA_ "Origin" SG_ 762 HCU_RefuReq "ev";
BA_ "GenSigCycleTime" SG_ 762 HCU_OPDFail 100;
BA_ "Match" SG_ 762 HCU_OPDFail "HCU_OPDFail";
BA_ "Origin" SG_ 762 HCU_OPDFail "ev";
BA_ "GenSigCycleTime" SG_ 762 OPDParkWarnReq 100;
BA_ "Match" SG_ 762 OPDParkWarnReq "OPDParkWarnReq";
BA_ "Origin" SG_ 762 OPDParkWarnReq "ev";
BA_ "GenSigCycleTime" SG_ 762 HCU_ACStsReq 100;
BA_ "GenSigStartValue" SG_ 762 HCU_ACStsReq 2;
BA_ "Match" SG_ 762 HCU_ACStsReq "HCU_ACStsReq";
BA_ "Origin" SG_ 762 HCU_ACStsReq "ev";
BA_ "GenSigCycleTime" SG_ 584 HCU_12VSysErr_1 50;
BA_ "Match" SG_ 584 HCU_12VSysErr_1 "HCU_12VSysErr_1";
BA_ "Origin" SG_ 584 HCU_12VSysErr_1 "fuel,ev";
BA_ "GenSigCycleTime" SG_ 584 HCU_12VSysErr_2 50;
BA_ "Match" SG_ 584 HCU_12VSysErr_2 "HCU_12VSysErr_2";
BA_ "Origin" SG_ 584 HCU_12VSysErr_2 "fuel,ev";
BA_ "GenSigCycleTime" SG_ 584 HCU_HybSysErr_1 50;
BA_ "Match" SG_ 584 HCU_HybSysErr_1 "HCU_HybSysErr_1";
BA_ "Origin" SG_ 584 HCU_HybSysErr_1 "fuel,ev";
BA_ "GenSigCycleTime" SG_ 584 HCU_HybSysErr_2 50;
BA_ "Match" SG_ 584 HCU_HybSysErr_2 "HCU_HybSysErr_2";
BA_ "Origin" SG_ 584 HCU_HybSysErr_2 "fuel,ev";
BA_ "GenSigCycleTime" SG_ 584 HCU_HybSysErr_5 50;
BA_ "Match" SG_ 584 HCU_HybSysErr_5 "HCU_HybSysErr_5";
BA_ "Origin" SG_ 584 HCU_HybSysErr_5 "fuel,ev";
BA_ "GenSigCycleTime" SG_ 584 HCU_HybSysErr_6 50;
BA_ "Match" SG_ 584 HCU_HybSysErr_6 "HCU_HybSysErr_6";
BA_ "Origin" SG_ 584 HCU_HybSysErr_6 "fuel,ev";
BA_ "GenSigCycleTime" SG_ 584 HCU_HybSysErr_7 50;
BA_ "Match" SG_ 584 HCU_HybSysErr_7 "HCU_HybSysErr_7";
BA_ "Origin" SG_ 584 HCU_HybSysErr_7 "fuel,ev";
BA_ "GenSigCycleTime" SG_ 584 HCU_12VSysErrLmpSts 50;
BA_ "Match" SG_ 584 HCU_12VSysErrLmpSts "HCU_12VSysErrLmpSts";
BA_ "Origin" SG_ 584 HCU_12VSysErrLmpSts "fuel,ev";
BA_ "GenSigCycleTime" SG_ 584 HCU_HybSysErrLmpSts 50;
BA_ "Match" SG_ 584 HCU_HybSysErrLmpSts "HCU_HybSysErrLmpSts";
BA_ "Origin" SG_ 584 HCU_HybSysErrLmpSts "fuel,ev";
BA_ "GenSigCycleTime" SG_ 584 HCU_PowerRedWarnLmpCmd 50;
BA_ "Match" SG_ 584 HCU_PowerRedWarnLmpCmd "HCU_PowerRedWarnLmpCmd";
BA_ "Origin" SG_ 584 HCU_PowerRedWarnLmpCmd "fuel,ev";
BA_ "GenSigCycleTime" SG_ 584 HCU_EnrgFlowInd 50;
BA_ "Match" SG_ 584 HCU_EnrgFlowInd "HCU_EnrgFlowInd";
BA_ "Origin" SG_ 584 HCU_EnrgFlowInd "fuel";
BA_ "GenSigCycleTime" SG_ 584 HCU_HybSysErr_3 50;
BA_ "Match" SG_ 584 HCU_HybSysErr_3 "HCU_HybSysErr_3";
BA_ "Origin" SG_ 584 HCU_HybSysErr_3 "fuel,ev";
BA_ "GenSigCycleTime" SG_ 584 HCU_RdyLmpSts 50;
BA_ "Match" SG_ 584 HCU_RdyLmpSts "HCU_RdyLmpSts";
BA_ "Origin" SG_ 584 HCU_RdyLmpSts "fuel,ev";
BA_ "GenSigCycleTime" SG_ 584 CheckSum_HCU_PT7 50;
BA_ "Match" SG_ 584 CheckSum_HCU_PT7 "CheckSum_HCU_PT7";
BA_ "Origin" SG_ 584 CheckSum_HCU_PT7 "ev,ev";
BA_ "GenSigCycleTime" SG_ 584 HCU_HybSysErr_4 50;
BA_ "Match" SG_ 584 HCU_HybSysErr_4 "HCU_HybSysErr_4";
BA_ "Origin" SG_ 584 HCU_HybSysErr_4 "ev,ev";
BA_ "GenSigCycleTime" SG_ 584 HCU_EnrgFlowInd_P2 50;
BA_ "Match" SG_ 584 HCU_EnrgFlowInd_P2 "HCU_EnrgFlowInd_P2";
BA_ "Origin" SG_ 584 HCU_EnrgFlowInd_P2 "ev,ev";
BA_ "GenSigCycleTime" SG_ 584 HCU_12VSysErr_3 50;
BA_ "Match" SG_ 584 HCU_12VSysErr_3 "HCU_12VSysErr_3";
BA_ "Origin" SG_ 584 HCU_12VSysErr_3 "ev,ev";
BA_ "GenSigCycleTime" SG_ 584 HCU_OPDLmpSts 50;
BA_ "Match" SG_ 584 HCU_OPDLmpSts "HCU_OPDLmpSts";
BA_ "Origin" SG_ 584 HCU_OPDLmpSts "ev,ev";
BA_ "GenSigCycleTime" SG_ 584 HCU_OPDSts 50;
BA_ "Match" SG_ 584 HCU_OPDSts "HCU_OPDSts";
BA_ "Origin" SG_ 584 HCU_OPDSts "ev,ev";
BA_ "GenSigCycleTime" SG_ 584 HCU_ModSwtFail 50;
BA_ "Match" SG_ 584 HCU_ModSwtFail "HCU_ModSwtFail";
BA_ "Origin" SG_ 584 HCU_ModSwtFail "ev,ev";
BA_ "GenSigCycleTime" SG_ 584 RollingCounter_HCU_PT7 50;
BA_ "Match" SG_ 584 RollingCounter_HCU_PT7 "RollingCounter_HCU_PT7";
BA_ "Origin" SG_ 584 RollingCounter_HCU_PT7 "ev,ev";
BA_ "GenSigCycleTime" SG_ 805 HUD_SwtSts 200;
BA_ "GenSigStartValue" SG_ 805 HUD_SwtSts 1;
BA_ "Match" SG_ 805 HUD_SwtSts "HUD_SwtSts";
BA_ "Origin" SG_ 805 HUD_SwtSts "fuel,ev";
BA_ "GenSigCycleTime" SG_ 805 HUD_BrightnessLvl 200;
BA_ "GenSigStartValue" SG_ 805 HUD_BrightnessLvl 4;
BA_ "Match" SG_ 805 HUD_BrightnessLvl "HUD_BrightnessLvl";
BA_ "Origin" SG_ 805 HUD_BrightnessLvl "fuel,ev";
BA_ "GenSigCycleTime" SG_ 805 HUD_HeightLvl 200;
BA_ "GenSigStartValue" SG_ 805 HUD_HeightLvl 10;
BA_ "Match" SG_ 805 HUD_HeightLvl "HUD_HeightLvl";
BA_ "Origin" SG_ 805 HUD_HeightLvl "fuel,ev";
BA_ "GenSigCycleTime" SG_ 805 HUD_UIMod 200;
BA_ "Match" SG_ 805 HUD_UIMod "HUD_UIMod";
BA_ "Origin" SG_ 805 HUD_UIMod "fuel,ev";
BA_ "GenSigCycleTime" SG_ 805 HUD_UIModVld 200;
BA_ "Match" SG_ 805 HUD_UIModVld "HUD_UIModVld";
BA_ "Origin" SG_ 805 HUD_UIModVld "fuel,ev";
BA_ "GenSigCycleTime" SG_ 805 HUD_Manufactor 200;
BA_ "GenSigStartValue" SG_ 805 HUD_Manufactor 7;
BA_ "Match" SG_ 805 HUD_Manufactor "HUD_Manufactor";
BA_ "Origin" SG_ 805 HUD_Manufactor "fuel,ev";
BA_ "GenSigCycleTime" SG_ 805 HUD_ReslType 200;
BA_ "GenSigStartValue" SG_ 805 HUD_ReslType 7;
BA_ "Match" SG_ 805 HUD_ReslType "HUD_ReslType";
BA_ "Origin" SG_ 805 HUD_ReslType "fuel,ev";
BA_ "GenSigCycleTime" SG_ 707 SSSSet_HUT 100;
BA_ "GenSigStartValue" SG_ 707 SSSSet_HUT 1;
BA_ "Match" SG_ 707 SSSSet_HUT "SSSSet_HUT";
BA_ "Origin" SG_ 707 SSSSet_HUT "fuel,ev";
BA_ "GenSigCycleTime" SG_ 707 IFC_SnvtySet 100;
BA_ "Match" SG_ 707 IFC_SnvtySet "IFC_SnvtySet";
BA_ "Origin" SG_ 707 IFC_SnvtySet "fuel,ev";
BA_ "GenSigCycleTime" SG_ 707 DOWSwtReq 100;
BA_ "Match" SG_ 707 DOWSwtReq "DOWSwtReq";
BA_ "Origin" SG_ 707 DOWSwtReq "fuel,ev";
BA_ "GenSigCycleTime" SG_ 707 AEB_PedSwtReq 100;
BA_ "GenSigStartValue" SG_ 707 AEB_PedSwtReq 1;
BA_ "Match" SG_ 707 AEB_PedSwtReq "AEB_PedSwtReq";
BA_ "Origin" SG_ 707 AEB_PedSwtReq "fuel,ev";
BA_ "GenSigCycleTime" SG_ 707 ALCMLightLvlSet 100;
BA_ "GenSigStartValue" SG_ 707 ALCMLightLvlSet 5;
BA_ "Match" SG_ 707 ALCMLightLvlSet "ALCMLightLvlSet";
BA_ "Origin" SG_ 707 ALCMLightLvlSet "fuel,ev";
BA_ "GenSigCycleTime" SG_ 707 FlashLmpSwtReq 100;
BA_ "GenSigStartValue" SG_ 707 FlashLmpSwtReq 1;
BA_ "Match" SG_ 707 FlashLmpSwtReq "FlashLmpSwtReq";
BA_ "Origin" SG_ 707 FlashLmpSwtReq "fuel,ev";
BA_ "GenSigCycleTime" SG_ 707 LCASwtReq 100;
BA_ "Match" SG_ 707 LCASwtReq "LCASwtReq";
BA_ "Origin" SG_ 707 LCASwtReq "fuel,ev";
BA_ "GenSigCycleTime" SG_ 707 RCTASwtReq 100;
BA_ "Match" SG_ 707 RCTASwtReq "RCTASwtReq";
BA_ "Origin" SG_ 707 RCTASwtReq "fuel,ev";
BA_ "GenSigCycleTime" SG_ 707 RCTABrkSwtReq 100;
BA_ "Match" SG_ 707 RCTABrkSwtReq "RCTABrkSwtReq";
BA_ "Origin" SG_ 707 RCTABrkSwtReq "fuel,ev";
BA_ "GenSigCycleTime" SG_ 707 RCWSwtReq 100;
BA_ "Match" SG_ 707 RCWSwtReq "RCWSwtReq";
BA_ "Origin" SG_ 707 RCWSwtReq "fuel,ev";
BA_ "GenSigCycleTime" SG_ 707 FCW_SnvtySet 100;
BA_ "Match" SG_ 707 FCW_SnvtySet "FCW_SnvtySet";
BA_ "Origin" SG_ 707 FCW_SnvtySet "fuel,ev";
BA_ "GenSigCycleTime" SG_ 707 AEB_VehSwtReq 100;
BA_ "GenSigStartValue" SG_ 707 AEB_VehSwtReq 1;
BA_ "Match" SG_ 707 AEB_VehSwtReq "AEB_VehSwtReq";
BA_ "Origin" SG_ 707 AEB_VehSwtReq "fuel,ev";
BA_ "GenSigCycleTime" SG_ 707 LKASwtReq 100;
BA_ "Match" SG_ 707 LKASwtReq "LKASwtReq";
BA_ "Origin" SG_ 707 LKASwtReq "fuel,ev";
BA_ "GenSigCycleTime" SG_ 707 LCKSwtReq 100;
BA_ "Match" SG_ 707 LCKSwtReq "LCKSwtReq";
BA_ "Origin" SG_ 707 LCKSwtReq "fuel,ev";
BA_ "GenSigCycleTime" SG_ 707 ELKSwtReq 100;
BA_ "Match" SG_ 707 ELKSwtReq "ELKSwtReq";
BA_ "Origin" SG_ 707 ELKSwtReq "fuel,ev";
BA_ "GenSigCycleTime" SG_ 707 ESS_PedSwtReq 100;
BA_ "Match" SG_ 707 ESS_PedSwtReq "ESS_PedSwtReq";
BA_ "Origin" SG_ 707 ESS_PedSwtReq "fuel,ev";
BA_ "GenSigCycleTime" SG_ 707 ESS_VehSwtReq 100;
BA_ "Match" SG_ 707 ESS_VehSwtReq "ESS_VehSwtReq";
BA_ "Origin" SG_ 707 ESS_VehSwtReq "fuel,ev";
BA_ "GenSigCycleTime" SG_ 707 LDWSwtReq 100;
BA_ "Match" SG_ 707 LDWSwtReq "LDWSwtReq";
BA_ "Origin" SG_ 707 LDWSwtReq "fuel,ev";
BA_ "GenSigCycleTime" SG_ 707 TSRSwtReq 100;
BA_ "Match" SG_ 707 TSRSwtReq "TSRSwtReq";
BA_ "Origin" SG_ 707 TSRSwtReq "fuel,ev";
BA_ "GenSigCycleTime" SG_ 707 TSRWarnSwtReq 100;
BA_ "Match" SG_ 707 TSRWarnSwtReq "TSRWarnSwtReq";
BA_ "Origin" SG_ 707 TSRWarnSwtReq "fuel,ev";
BA_ "GenSigCycleTime" SG_ 707 ICA_HandsOffSwtReq 100;
BA_ "Match" SG_ 707 ICA_HandsOffSwtReq "ICA_HandsOffSwtReq";
BA_ "Origin" SG_ 707 ICA_HandsOffSwtReq "fuel,ev";
BA_ "GenSigCycleTime" SG_ 707 ISLSwtReq 100;
BA_ "Match" SG_ 707 ISLSwtReq "ISLSwtReq";
BA_ "Origin" SG_ 707 ISLSwtReq "fuel,ev";
BA_ "GenSigCycleTime" SG_ 707 TSR_SnvtySet 100;
BA_ "GenSigStartValue" SG_ 707 TSR_SnvtySet 15;
BA_ "Match" SG_ 707 TSR_SnvtySet "TSR_SnvtySet";
BA_ "Origin" SG_ 707 TSR_SnvtySet "fuel,ev";
BA_ "GenSigCycleTime" SG_ 707 HFASwtSts 100;
BA_ "GenSigStartValue" SG_ 707 HFASwtSts 1;
BA_ "Match" SG_ 707 HFASwtSts "HFASwtSts";
BA_ "Origin" SG_ 707 HFASwtSts "fuel,ev";
BA_ "GenSigCycleTime" SG_ 707 EPSSteerModSwtReq 100;
BA_ "Match" SG_ 707 EPSSteerModSwtReq "EPSSteerModSwtReq";
BA_ "Origin" SG_ 707 EPSSteerModSwtReq "fuel,ev";
BA_ "GenSigCycleTime" SG_ 707 DSTSwtReq 100;
BA_ "Match" SG_ 707 DSTSwtReq "DSTSwtReq";
BA_ "Origin" SG_ 707 DSTSwtReq "fuel,ev";
BA_ "GenSigCycleTime" SG_ 707 LSSWarnFormSwtReq 100;
BA_ "Match" SG_ 707 LSSWarnFormSwtReq "LSSWarnFormSwtReq";
BA_ "Origin" SG_ 707 LSSWarnFormSwtReq "fuel,ev";
BA_ "GenSigCycleTime" SG_ 707 HUT_ESPFuncOffSwtSts 100;
BA_ "Match" SG_ 707 HUT_ESPFuncOffSwtSts "HUT_ESPFuncOffSwtSts";
BA_ "Origin" SG_ 707 HUT_ESPFuncOffSwtSts "fuel,ev";
BA_ "GenSigCycleTime" SG_ 707 DrivingModReq_HUT 100;
BA_ "Match" SG_ 707 DrivingModReq_HUT "DrivingModReq_HUT";
BA_ "Origin" SG_ 707 DrivingModReq_HUT "fuel,ev";
BA_ "GenSigCycleTime" SG_ 707 OilLvlDispReq 100;
BA_ "Match" SG_ 707 OilLvlDispReq "OilLvlDispReq";
BA_ "Origin" SG_ 707 OilLvlDispReq "fuel";
BA_ "GenSigCycleTime" SG_ 707 DrvgModeMemReq 100;
BA_ "Match" SG_ 707 DrvgModeMemReq "DrvgModeMemReq";
BA_ "Origin" SG_ 707 DrvgModeMemReq "fuel,ev";
BA_ "GenSigCycleTime" SG_ 707 IntelligentEvaSwtReq 100;
BA_ "Match" SG_ 707 IntelligentEvaSwtReq "IntelligentEvaSwtReq";
BA_ "Origin" SG_ 707 IntelligentEvaSwtReq "fuel,ev";
BA_ "GenSigCycleTime" SG_ 707 LSSSwtReq 100;
BA_ "Match" SG_ 707 LSSSwtReq "LSSSwtReq";
BA_ "Origin" SG_ 707 LSSSwtReq "fuel,ev";
BA_ "GenSigCycleTime" SG_ 707 HUTRadioFrq 100;
BA_ "Match" SG_ 707 HUTRadioFrq "HUTRadioFrq";
BA_ "Origin" SG_ 707 HUTRadioFrq "fuel,ev";
BA_ "GenSigCycleTime" SG_ 707 MediaPlaySrc 100;
BA_ "Match" SG_ 707 MediaPlaySrc "MediaPlaySrc";
BA_ "Origin" SG_ 707 MediaPlaySrc "fuel,ev";
BA_ "GenSigCycleTime" SG_ 707 USB_AudioSts 100;
BA_ "Match" SG_ 707 USB_AudioSts "USB_AudioSts";
BA_ "Origin" SG_ 707 USB_AudioSts "fuel,ev";
BA_ "GenSigCycleTime" SG_ 707 USB_VideoSts 100;
BA_ "Match" SG_ 707 USB_VideoSts "USB_VideoSts";
BA_ "Origin" SG_ 707 USB_VideoSts "fuel,ev";
BA_ "GenSigCycleTime" SG_ 707 BT_AudioSts 100;
BA_ "Match" SG_ 707 BT_AudioSts "BT_AudioSts";
BA_ "Origin" SG_ 707 BT_AudioSts "fuel,ev";
BA_ "GenSigCycleTime" SG_ 707 IPod_Sts 100;
BA_ "Match" SG_ 707 IPod_Sts "IPod_Sts";
BA_ "Origin" SG_ 707 IPod_Sts "fuel,ev";
BA_ "GenSigCycleTime" SG_ 707 AM_Sts 100;
BA_ "Match" SG_ 707 AM_Sts "AM_Sts";
BA_ "Origin" SG_ 707 AM_Sts "fuel,ev";
BA_ "GenSigCycleTime" SG_ 707 FM_Sts 100;
BA_ "Match" SG_ 707 FM_Sts "FM_Sts";
BA_ "Origin" SG_ 707 FM_Sts "fuel,ev";
BA_ "GenSigCycleTime" SG_ 707 APPLink_Sts 100;
BA_ "Match" SG_ 707 APPLink_Sts "APPLink_Sts";
BA_ "Origin" SG_ 707 APPLink_Sts "fuel,ev";
BA_ "GenSigCycleTime" SG_ 707 QQMusic_Sts 100;
BA_ "Match" SG_ 707 QQMusic_Sts "QQMusic_Sts";
BA_ "Origin" SG_ 707 QQMusic_Sts "fuel,ev";
BA_ "GenSigCycleTime" SG_ 707 KaolaFM_Sts 100;
BA_ "Match" SG_ 707 KaolaFM_Sts "KaolaFM_Sts";
BA_ "Origin" SG_ 707 KaolaFM_Sts "fuel,ev";
BA_ "GenSigCycleTime" SG_ 707 OnlineNews_Sts 100;
BA_ "Match" SG_ 707 OnlineNews_Sts "OnlineNews_Sts";
BA_ "Origin" SG_ 707 OnlineNews_Sts "fuel,ev";
BA_ "GenSigCycleTime" SG_ 707 HUT_WadeModeSet 100;
BA_ "Match" SG_ 707 HUT_WadeModeSet "HUT_WadeModeSet";
BA_ "Origin" SG_ 707 HUT_WadeModeSet "fuel,ev";
BA_ "GenSigCycleTime" SG_ 707 ExpertModReq_HUT_ECM 100;
BA_ "Match" SG_ 707 ExpertModReq_HUT_ECM "ExpertModReq_HUT_ECM";
BA_ "Origin" SG_ 707 ExpertModReq_HUT_ECM "fuel,ev";
BA_ "GenSigCycleTime" SG_ 707 ExpertModReq_HUT_TCU 100;
BA_ "Match" SG_ 707 ExpertModReq_HUT_TCU "ExpertModReq_HUT_TCU";
BA_ "Origin" SG_ 707 ExpertModReq_HUT_TCU "fuel,ev";
BA_ "GenSigCycleTime" SG_ 707 ExpertModReq_HUT_TOD 100;
BA_ "Match" SG_ 707 ExpertModReq_HUT_TOD "ExpertModReq_HUT_TOD";
BA_ "Origin" SG_ 707 ExpertModReq_HUT_TOD "fuel,ev";
BA_ "GenSigCycleTime" SG_ 707 ChairMemPosnSet 100;
BA_ "Match" SG_ 707 ChairMemPosnSet "ChairMemPosnSet";
BA_ "Origin" SG_ 707 ChairMemPosnSet "fuel,ev";
BA_ "GenSigCycleTime" SG_ 707 ChairMemPosnSetResult 100;
BA_ "Match" SG_ 707 ChairMemPosnSetResult "ChairMemPosnSetResult";
BA_ "Origin" SG_ 707 ChairMemPosnSetResult "fuel,ev";
BA_ "GenSigCycleTime" SG_ 707 TABSwtReq_HUT 100;
BA_ "Match" SG_ 707 TABSwtReq_HUT "TABSwtReq_HUT";
BA_ "Origin" SG_ 707 TABSwtReq_HUT "fuel,ev";
BA_ "GenSigCycleTime" SG_ 707 NavVehToTrafEyeDist 100;
BA_ "Match" SG_ 707 NavVehToTrafEyeDist "NavVehToTrafEyeDist";
BA_ "Origin" SG_ 707 NavVehToTrafEyeDist "fuel,ev";
BA_ "GenSigCycleTime" SG_ 707 NavRoadType 100;
BA_ "Match" SG_ 707 NavRoadType "NavRoadType";
BA_ "Origin" SG_ 707 NavRoadType "fuel,ev";
BA_ "GenSigCycleTime" SG_ 707 NavSpdLimType 100;
BA_ "Match" SG_ 707 NavSpdLimType "NavSpdLimType";
BA_ "Origin" SG_ 707 NavSpdLimType "fuel,ev";
BA_ "GenSigCycleTime" SG_ 707 NavSpdLimValue 100;
BA_ "Match" SG_ 707 NavSpdLimValue "NavSpdLimValue";
BA_ "Origin" SG_ 707 NavSpdLimValue "fuel,ev";
BA_ "GenSigCycleTime" SG_ 707 NavSpdLimUnit_HUT 100;
BA_ "GenSigStartValue" SG_ 707 NavSpdLimUnit_HUT 1;
BA_ "Match" SG_ 707 NavSpdLimUnit_HUT "NavSpdLimUnit_HUT";
BA_ "Origin" SG_ 707 NavSpdLimUnit_HUT "fuel,ev";
BA_ "GenSigCycleTime" SG_ 707 NavCtryType 100;
BA_ "GenSigStartValue" SG_ 707 NavCtryType 156;
BA_ "Match" SG_ 707 NavCtryType "NavCtryType";
BA_ "Origin" SG_ 707 NavCtryType "fuel,ev";
BA_ "GenSigCycleTime" SG_ 707 NavSpdLimSignSts 100;
BA_ "Match" SG_ 707 NavSpdLimSignSts "NavSpdLimSignSts";
BA_ "Origin" SG_ 707 NavSpdLimSignSts "fuel,ev";
BA_ "GenSigCycleTime" SG_ 707 NavTSRTrafSign 100;
BA_ "Match" SG_ 707 NavTSRTrafSign "NavTSRTrafSign";
BA_ "Origin" SG_ 707 NavTSRTrafSign "fuel,ev";
BA_ "GenSigCycleTime" SG_ 707 AESSwtReq 100;
BA_ "Match" SG_ 707 AESSwtReq "AESSwtReq";
BA_ "Origin" SG_ 707 AESSwtReq "fuel,ev";
BA_ "GenSigCycleTime" SG_ 707 HWA_SwtReq 100;
BA_ "GenSigStartValue" SG_ 707 HWA_SwtReq 1;
BA_ "Match" SG_ 707 HWA_SwtReq "HWA_SwtReq";
BA_ "Origin" SG_ 707 HWA_SwtReq "fuel,ev";
BA_ "GenSigCycleTime" SG_ 707 HWA_SnvtySet 100;
BA_ "Match" SG_ 707 HWA_SnvtySet "HWA_SnvtySet";
BA_ "Origin" SG_ 707 HWA_SnvtySet "fuel,ev";
BA_ "GenSigCycleTime" SG_ 707 FCTASwtReq 100;
BA_ "Match" SG_ 707 FCTASwtReq "FCTASwtReq";
BA_ "Origin" SG_ 707 FCTASwtReq "fuel,ev";
BA_ "GenSigCycleTime" SG_ 707 FCTABrkSwtReq 100;
BA_ "Match" SG_ 707 FCTABrkSwtReq "FCTABrkSwtReq";
BA_ "Origin" SG_ 707 FCTABrkSwtReq "fuel,ev";
BA_ "GenSigCycleTime" SG_ 707 AEB_JASwtReq 100;
BA_ "Match" SG_ 707 AEB_JASwtReq "AEB_JASwtReq";
BA_ "Origin" SG_ 707 AEB_JASwtReq "fuel,ev";
BA_ "GenSigCycleTime" SG_ 707 HWA_WarnFormSwtReq 100;
BA_ "Match" SG_ 707 HWA_WarnFormSwtReq "HWA_WarnFormSwtReq";
BA_ "Origin" SG_ 707 HWA_WarnFormSwtReq "fuel,ev";
BA_ "GenSigCycleTime" SG_ 707 SteerCorrnReq 100;
BA_ "GenSigStartValue" SG_ 707 SteerCorrnReq 1;
BA_ "Match" SG_ 707 SteerCorrnReq "SteerCorrnReq";
BA_ "Origin" SG_ 707 SteerCorrnReq "fuel,ev";
BA_ "GenSigCycleTime" SG_ 707 ALC_SwtReq 100;
BA_ "Match" SG_ 707 ALC_SwtReq "ALC_SwtReq";
BA_ "Origin" SG_ 707 ALC_SwtReq "fuel,ev";
BA_ "GenSigCycleTime" SG_ 707 ExpertModSwtReq_HUT 100;
BA_ "Match" SG_ 707 ExpertModSwtReq_HUT "ExpertModSwtReq_HUT";
BA_ "Origin" SG_ 707 ExpertModSwtReq_HUT "fuel,ev";
BA_ "GenSigCycleTime" SG_ 707 ExpertModReq_HUT_ESP 100;
BA_ "Match" SG_ 707 ExpertModReq_HUT_ESP "ExpertModReq_HUT_ESP";
BA_ "Origin" SG_ 707 ExpertModReq_HUT_ESP "fuel,ev";
BA_ "GenSigCycleTime" SG_ 707 ADAS_Posn_MsgTye 100;
BA_ "Match" SG_ 707 ADAS_Posn_MsgTye "ADAS_Posn_MsgTye";
BA_ "Origin" SG_ 707 ADAS_Posn_MsgTye "fuel,ev";
BA_ "GenSigCycleTime" SG_ 707 ADAS_Posn_Offset 100;
BA_ "GenSigStartValue" SG_ 707 ADAS_Posn_Offset 8191;
BA_ "Match" SG_ 707 ADAS_Posn_Offset "ADAS_Posn_Offset";
BA_ "Origin" SG_ 707 ADAS_Posn_Offset "fuel,ev";
BA_ "GenSigCycleTime" SG_ 707 ADAS_Posn_CycCnt 100;
BA_ "Match" SG_ 707 ADAS_Posn_CycCnt "ADAS_Posn_CycCnt";
BA_ "Origin" SG_ 707 ADAS_Posn_CycCnt "fuel,ev";
BA_ "GenSigCycleTime" SG_ 707 ADAS_Posn_Pathldx 100;
BA_ "Match" SG_ 707 ADAS_Posn_Pathldx "ADAS_Posn_Pathldx";
BA_ "Origin" SG_ 707 ADAS_Posn_Pathldx "fuel,ev";
BA_ "GenSigCycleTime" SG_ 707 ADAS_Posn_Idx 100;
BA_ "Match" SG_ 707 ADAS_Posn_Idx "ADAS_Posn_Idx";
BA_ "Origin" SG_ 707 ADAS_Posn_Idx "fuel,ev";
BA_ "GenSigCycleTime" SG_ 707 ADAS_Posn_PosProbb 100;
BA_ "Match" SG_ 707 ADAS_Posn_PosProbb "ADAS_Posn_PosProbb";
BA_ "Origin" SG_ 707 ADAS_Posn_PosProbb "fuel,ev";
BA_ "GenSigCycleTime" SG_ 707 ADAS_Posn_Age 100;
BA_ "Match" SG_ 707 ADAS_Posn_Age "ADAS_Posn_Age";
BA_ "Origin" SG_ 707 ADAS_Posn_Age "fuel,ev";
BA_ "GenSigCycleTime" SG_ 707 ADAS_Posn_PosConfdc 100;
BA_ "Match" SG_ 707 ADAS_Posn_PosConfdc "ADAS_Posn_PosConfdc";
BA_ "Origin" SG_ 707 ADAS_Posn_PosConfdc "fuel,ev";
BA_ "GenSigCycleTime" SG_ 707 ADAS_Posn_CurLane 100;
BA_ "Match" SG_ 707 ADAS_Posn_CurLane "ADAS_Posn_CurLane";
BA_ "Origin" SG_ 707 ADAS_Posn_CurLane "fuel,ev";
BA_ "GenSigCycleTime" SG_ 707 ADAS_Posn_Spd 100;
BA_ "GenSigStartValue" SG_ 707 ADAS_Posn_Spd 511;
BA_ "Match" SG_ 707 ADAS_Posn_Spd "ADAS_Posn_Spd";
BA_ "Origin" SG_ 707 ADAS_Posn_Spd "fuel,ev";
BA_ "GenSigCycleTime" SG_ 707 ADAS_Posn_Rehead 100;
BA_ "Match" SG_ 707 ADAS_Posn_Rehead "ADAS_Posn_Rehead";
BA_ "Origin" SG_ 707 ADAS_Posn_Rehead "fuel,ev";
BA_ "GenSigCycleTime" SG_ 707 FreshnessValue_HUT_FD1 100;
BA_ "Match" SG_ 707 FreshnessValue_HUT_FD1 "FreshnessValue_HUT_FD1";
BA_ "Origin" SG_ 707 FreshnessValue_HUT_FD1 "fuel,ev";
BA_ "GenSigCycleTime" SG_ 707 MAC_Check_HUT_FD1 100;
BA_ "Match" SG_ 707 MAC_Check_HUT_FD1 "MAC_Check_HUT_FD1";
BA_ "Origin" SG_ 707 MAC_Check_HUT_FD1 "fuel,ev";
BA_ "GenSigCycleTime" SG_ 707 EngStrtDischrgn 100;
BA_ "GenSigStartValue" SG_ 707 EngStrtDischrgn 1;
BA_ "Match" SG_ 707 EngStrtDischrgn "EngStrtDischrgn";
BA_ "Origin" SG_ 707 EngStrtDischrgn "ev";
BA_ "GenSigCycleTime" SG_ 707 HUT_HybModReq 100;
BA_ "Match" SG_ 707 HUT_HybModReq "HUT_HybModReq";
BA_ "Origin" SG_ 707 HUT_HybModReq "ev";
BA_ "GenSigCycleTime" SG_ 707 HUT_HybFctnReq 100;
BA_ "Match" SG_ 707 HUT_HybFctnReq "HUT_HybFctnReq";
BA_ "Origin" SG_ 707 HUT_HybFctnReq "ev";
BA_ "GenSigCycleTime" SG_ 707 HUT_DrvModReq 100;
BA_ "Match" SG_ 707 HUT_DrvModReq "HUT_DrvModReq";
BA_ "Origin" SG_ 707 HUT_DrvModReq "ev";
BA_ "GenSigCycleTime" SG_ 515 HUT_OD_Obj0_ID 50;
BA_ "Match" SG_ 515 HUT_OD_Obj0_ID "HUT_OD_Obj0_ID";
BA_ "Origin" SG_ 515 HUT_OD_Obj0_ID "fuel,ev";
BA_ "GenSigCycleTime" SG_ 515 HUT_OD_Obj0_type 50;
BA_ "Match" SG_ 515 HUT_OD_Obj0_type "HUT_OD_Obj0_type";
BA_ "Origin" SG_ 515 HUT_OD_Obj0_type "fuel,ev";
BA_ "GenSigCycleTime" SG_ 515 HUT_OD_Obj0_Confidence 50;
BA_ "Match" SG_ 515 HUT_OD_Obj0_Confidence "HUT_OD_Obj0_Confidence";
BA_ "Origin" SG_ 515 HUT_OD_Obj0_Confidence "fuel,ev";
BA_ "GenSigCycleTime" SG_ 515 HUT_OD_Obj0_width 50;
BA_ "Match" SG_ 515 HUT_OD_Obj0_width "HUT_OD_Obj0_width";
BA_ "Origin" SG_ 515 HUT_OD_Obj0_width "fuel,ev";
BA_ "GenSigCycleTime" SG_ 515 HUT_OD_Obj0_Ground_Pos_X 50;
BA_ "Match" SG_ 515 HUT_OD_Obj0_Ground_Pos_X "HUT_OD_Obj0_Ground_Pos_X";
BA_ "Origin" SG_ 515 HUT_OD_Obj0_Ground_Pos_X "fuel,ev";
BA_ "GenSigCycleTime" SG_ 515 HUT_OD_Obj0_Ground_Pos_Y 50;
BA_ "Match" SG_ 515 HUT_OD_Obj0_Ground_Pos_Y "HUT_OD_Obj0_Ground_Pos_Y";
BA_ "Origin" SG_ 515 HUT_OD_Obj0_Ground_Pos_Y "fuel,ev";
BA_ "GenSigCycleTime" SG_ 515 HTU_OD_Obj1_ID 50;
BA_ "Match" SG_ 515 HTU_OD_Obj1_ID "HTU_OD_Obj1_ID";
BA_ "Origin" SG_ 515 HTU_OD_Obj1_ID "fuel,ev";
BA_ "GenSigCycleTime" SG_ 515 HUT_OD_Obj1_type 50;
BA_ "Match" SG_ 515 HUT_OD_Obj1_type "HUT_OD_Obj1_type";
BA_ "Origin" SG_ 515 HUT_OD_Obj1_type "fuel,ev";
BA_ "GenSigCycleTime" SG_ 515 HUT_OD_Obj1_Confidence 50;
BA_ "Match" SG_ 515 HUT_OD_Obj1_Confidence "HUT_OD_Obj1_Confidence";
BA_ "Origin" SG_ 515 HUT_OD_Obj1_Confidence "fuel,ev";
BA_ "GenSigCycleTime" SG_ 515 HUT_OD_Obj1_width 50;
BA_ "Match" SG_ 515 HUT_OD_Obj1_width "HUT_OD_Obj1_width";
BA_ "Origin" SG_ 515 HUT_OD_Obj1_width "fuel,ev";
BA_ "GenSigCycleTime" SG_ 515 HUT_OD_Obj1_Ground_Pos_X 50;
BA_ "Match" SG_ 515 HUT_OD_Obj1_Ground_Pos_X "HUT_OD_Obj1_Ground_Pos_X";
BA_ "Origin" SG_ 515 HUT_OD_Obj1_Ground_Pos_X "fuel,ev";
BA_ "GenSigCycleTime" SG_ 515 HUT_OD_Obj1_Ground_Pos_Y 50;
BA_ "Match" SG_ 515 HUT_OD_Obj1_Ground_Pos_Y "HUT_OD_Obj1_Ground_Pos_Y";
BA_ "Origin" SG_ 515 HUT_OD_Obj1_Ground_Pos_Y "fuel,ev";
BA_ "GenSigCycleTime" SG_ 515 HUT_OD_Obj2_ID 50;
BA_ "Match" SG_ 515 HUT_OD_Obj2_ID "HUT_OD_Obj2_ID";
BA_ "Origin" SG_ 515 HUT_OD_Obj2_ID "fuel,ev";
BA_ "GenSigCycleTime" SG_ 515 HUT_OD_Obj2_type 50;
BA_ "Match" SG_ 515 HUT_OD_Obj2_type "HUT_OD_Obj2_type";
BA_ "Origin" SG_ 515 HUT_OD_Obj2_type "fuel,ev";
BA_ "GenSigCycleTime" SG_ 515 HUT_OD_Obj2_Confidence 50;
BA_ "Match" SG_ 515 HUT_OD_Obj2_Confidence "HUT_OD_Obj2_Confidence";
BA_ "Origin" SG_ 515 HUT_OD_Obj2_Confidence "fuel,ev";
BA_ "GenSigCycleTime" SG_ 515 HUT_OD_Obj2_width 50;
BA_ "Match" SG_ 515 HUT_OD_Obj2_width "HUT_OD_Obj2_width";
BA_ "Origin" SG_ 515 HUT_OD_Obj2_width "fuel,ev";
BA_ "GenSigCycleTime" SG_ 515 HUT_OD_Obj2_Ground_Pos_X 50;
BA_ "Match" SG_ 515 HUT_OD_Obj2_Ground_Pos_X "HUT_OD_Obj2_Ground_Pos_X";
BA_ "Origin" SG_ 515 HUT_OD_Obj2_Ground_Pos_X "fuel,ev";
BA_ "GenSigCycleTime" SG_ 515 HUT_OD_Obj2_Ground_Pos_Y 50;
BA_ "Match" SG_ 515 HUT_OD_Obj2_Ground_Pos_Y "HUT_OD_Obj2_Ground_Pos_Y";
BA_ "Origin" SG_ 515 HUT_OD_Obj2_Ground_Pos_Y "fuel,ev";
BA_ "GenSigCycleTime" SG_ 515 HUT_OD_Obj3_ID 50;
BA_ "Match" SG_ 515 HUT_OD_Obj3_ID "HUT_OD_Obj3_ID";
BA_ "Origin" SG_ 515 HUT_OD_Obj3_ID "fuel,ev";
BA_ "GenSigCycleTime" SG_ 515 HUT_OD_Obj3_type 50;
BA_ "Match" SG_ 515 HUT_OD_Obj3_type "HUT_OD_Obj3_type";
BA_ "Origin" SG_ 515 HUT_OD_Obj3_type "fuel,ev";
BA_ "GenSigCycleTime" SG_ 515 HUT_OD_Obj3_Confidence 50;
BA_ "Match" SG_ 515 HUT_OD_Obj3_Confidence "HUT_OD_Obj3_Confidence";
BA_ "Origin" SG_ 515 HUT_OD_Obj3_Confidence "fuel,ev";
BA_ "GenSigCycleTime" SG_ 515 HUT_OD_Obj3_width 50;
BA_ "Match" SG_ 515 HUT_OD_Obj3_width "HUT_OD_Obj3_width";
BA_ "Origin" SG_ 515 HUT_OD_Obj3_width "fuel,ev";
BA_ "GenSigCycleTime" SG_ 515 HUT_OD_Obj3_Ground_Pos_X 50;
BA_ "Match" SG_ 515 HUT_OD_Obj3_Ground_Pos_X "HUT_OD_Obj3_Ground_Pos_X";
BA_ "Origin" SG_ 515 HUT_OD_Obj3_Ground_Pos_X "fuel,ev";
BA_ "GenSigCycleTime" SG_ 515 HUT_OD_Obj3_Ground_Pos_Y 50;
BA_ "Match" SG_ 515 HUT_OD_Obj3_Ground_Pos_Y "HUT_OD_Obj3_Ground_Pos_Y";
BA_ "Origin" SG_ 515 HUT_OD_Obj3_Ground_Pos_Y "fuel,ev";
BA_ "GenSigCycleTime" SG_ 515 HUT_OD_Obj4_ID 50;
BA_ "Match" SG_ 515 HUT_OD_Obj4_ID "HUT_OD_Obj4_ID";
BA_ "Origin" SG_ 515 HUT_OD_Obj4_ID "fuel,ev";
BA_ "GenSigCycleTime" SG_ 515 HUT_OD_Obj4_type 50;
BA_ "Match" SG_ 515 HUT_OD_Obj4_type "HUT_OD_Obj4_type";
BA_ "Origin" SG_ 515 HUT_OD_Obj4_type "fuel,ev";
BA_ "GenSigCycleTime" SG_ 515 HUT_OD_Obj4_Confidence 50;
BA_ "Match" SG_ 515 HUT_OD_Obj4_Confidence "HUT_OD_Obj4_Confidence";
BA_ "Origin" SG_ 515 HUT_OD_Obj4_Confidence "fuel,ev";
BA_ "GenSigCycleTime" SG_ 515 HUT_OD_Obj4_width 50;
BA_ "Match" SG_ 515 HUT_OD_Obj4_width "HUT_OD_Obj4_width";
BA_ "Origin" SG_ 515 HUT_OD_Obj4_width "fuel,ev";
BA_ "GenSigCycleTime" SG_ 515 HUT_OD_Obj4_Ground_Pos_X 50;
BA_ "Match" SG_ 515 HUT_OD_Obj4_Ground_Pos_X "HUT_OD_Obj4_Ground_Pos_X";
BA_ "Origin" SG_ 515 HUT_OD_Obj4_Ground_Pos_X "fuel,ev";
BA_ "GenSigCycleTime" SG_ 515 HUT_OD_Obj4_Ground_Pos_Y 50;
BA_ "Match" SG_ 515 HUT_OD_Obj4_Ground_Pos_Y "HUT_OD_Obj4_Ground_Pos_Y";
BA_ "Origin" SG_ 515 HUT_OD_Obj4_Ground_Pos_Y "fuel,ev";
BA_ "GenSigCycleTime" SG_ 515 HUT_OD_Obj5_ID 50;
BA_ "Match" SG_ 515 HUT_OD_Obj5_ID "HUT_OD_Obj5_ID";
BA_ "Origin" SG_ 515 HUT_OD_Obj5_ID "fuel,ev";
BA_ "GenSigCycleTime" SG_ 515 HUT_OD_Obj5_type 50;
BA_ "Match" SG_ 515 HUT_OD_Obj5_type "HUT_OD_Obj5_type";
BA_ "Origin" SG_ 515 HUT_OD_Obj5_type "fuel,ev";
BA_ "GenSigCycleTime" SG_ 515 HUT_OD_Obj5_Confidence 50;
BA_ "Match" SG_ 515 HUT_OD_Obj5_Confidence "HUT_OD_Obj5_Confidence";
BA_ "Origin" SG_ 515 HUT_OD_Obj5_Confidence "fuel,ev";
BA_ "GenSigCycleTime" SG_ 515 HUT_OD_Obj5_width 50;
BA_ "Match" SG_ 515 HUT_OD_Obj5_width "HUT_OD_Obj5_width";
BA_ "Origin" SG_ 515 HUT_OD_Obj5_width "fuel,ev";
BA_ "GenSigCycleTime" SG_ 515 HUT_OD_Obj5_Ground_Pos_X 50;
BA_ "Match" SG_ 515 HUT_OD_Obj5_Ground_Pos_X "HUT_OD_Obj5_Ground_Pos_X";
BA_ "Origin" SG_ 515 HUT_OD_Obj5_Ground_Pos_X "fuel,ev";
BA_ "GenSigCycleTime" SG_ 515 HUT_OD_Obj5_Ground_Pos_Y 50;
BA_ "Match" SG_ 515 HUT_OD_Obj5_Ground_Pos_Y "HUT_OD_Obj5_Ground_Pos_Y";
BA_ "Origin" SG_ 515 HUT_OD_Obj5_Ground_Pos_Y "fuel,ev";
BA_ "GenSigCycleTime" SG_ 515 HUT_OD_Obj6_ID 50;
BA_ "Match" SG_ 515 HUT_OD_Obj6_ID "HUT_OD_Obj6_ID";
BA_ "Origin" SG_ 515 HUT_OD_Obj6_ID "fuel,ev";
BA_ "GenSigCycleTime" SG_ 515 HUT_OD_Obj6_type 50;
BA_ "Match" SG_ 515 HUT_OD_Obj6_type "HUT_OD_Obj6_type";
BA_ "Origin" SG_ 515 HUT_OD_Obj6_type "fuel,ev";
BA_ "GenSigCycleTime" SG_ 515 HUT_OD_Obj6_Confidence 50;
BA_ "Match" SG_ 515 HUT_OD_Obj6_Confidence "HUT_OD_Obj6_Confidence";
BA_ "Origin" SG_ 515 HUT_OD_Obj6_Confidence "fuel,ev";
BA_ "GenSigCycleTime" SG_ 515 HUT_OD_Obj6_width 50;
BA_ "Match" SG_ 515 HUT_OD_Obj6_width "HUT_OD_Obj6_width";
BA_ "Origin" SG_ 515 HUT_OD_Obj6_width "fuel,ev";
BA_ "GenSigCycleTime" SG_ 515 HUT_OD_Obj6_Ground_Pos_X 50;
BA_ "Match" SG_ 515 HUT_OD_Obj6_Ground_Pos_X "HUT_OD_Obj6_Ground_Pos_X";
BA_ "Origin" SG_ 515 HUT_OD_Obj6_Ground_Pos_X "fuel,ev";
BA_ "GenSigCycleTime" SG_ 515 HUT_OD_Obj6_Ground_Pos_Y 50;
BA_ "Match" SG_ 515 HUT_OD_Obj6_Ground_Pos_Y "HUT_OD_Obj6_Ground_Pos_Y";
BA_ "Origin" SG_ 515 HUT_OD_Obj6_Ground_Pos_Y "fuel,ev";
BA_ "GenSigCycleTime" SG_ 579 HUT_OD_Obj7_ID 50;
BA_ "Match" SG_ 579 HUT_OD_Obj7_ID "HUT_OD_Obj7_ID";
BA_ "Origin" SG_ 579 HUT_OD_Obj7_ID "fuel,ev";
BA_ "GenSigCycleTime" SG_ 579 HUT_OD_Obj7_type 50;
BA_ "Match" SG_ 579 HUT_OD_Obj7_type "HUT_OD_Obj7_type";
BA_ "Origin" SG_ 579 HUT_OD_Obj7_type "fuel,ev";
BA_ "GenSigCycleTime" SG_ 579 HUT_OD_Obj7_Confidence 50;
BA_ "Match" SG_ 579 HUT_OD_Obj7_Confidence "HUT_OD_Obj7_Confidence";
BA_ "Origin" SG_ 579 HUT_OD_Obj7_Confidence "fuel,ev";
BA_ "GenSigCycleTime" SG_ 579 HUT_OD_Obj7_width 50;
BA_ "Match" SG_ 579 HUT_OD_Obj7_width "HUT_OD_Obj7_width";
BA_ "Origin" SG_ 579 HUT_OD_Obj7_width "fuel,ev";
BA_ "GenSigCycleTime" SG_ 579 HUT_OD_Obj7_Ground_Pos_X 50;
BA_ "Match" SG_ 579 HUT_OD_Obj7_Ground_Pos_X "HUT_OD_Obj7_Ground_Pos_X";
BA_ "Origin" SG_ 579 HUT_OD_Obj7_Ground_Pos_X "fuel,ev";
BA_ "GenSigCycleTime" SG_ 579 HUT_OD_Obj7_Ground_Pos_Y 50;
BA_ "Match" SG_ 579 HUT_OD_Obj7_Ground_Pos_Y "HUT_OD_Obj7_Ground_Pos_Y";
BA_ "Origin" SG_ 579 HUT_OD_Obj7_Ground_Pos_Y "fuel,ev";
BA_ "GenSigCycleTime" SG_ 579 AutoSpdSetSwt 50;
BA_ "Match" SG_ 579 AutoSpdSetSwt "AutoSpdSetSwt";
BA_ "Origin" SG_ 579 AutoSpdSetSwt "fuel,ev";
BA_ "GenSigCycleTime" SG_ 579 LaneChngCfmSwt 50;
BA_ "Match" SG_ 579 LaneChngCfmSwt "LaneChngCfmSwt";
BA_ "Origin" SG_ 579 LaneChngCfmSwt "fuel,ev";
BA_ "GenSigCycleTime" SG_ 579 VoiceBrdcSwt 50;
BA_ "Match" SG_ 579 VoiceBrdcSwt "VoiceBrdcSwt";
BA_ "Origin" SG_ 579 VoiceBrdcSwt "fuel,ev";
BA_ "GenSigCycleTime" SG_ 579 UsrManSts 50;
BA_ "Match" SG_ 579 UsrManSts "UsrManSts";
BA_ "Origin" SG_ 579 UsrManSts "fuel,ev";
BA_ "GenSigCycleTime" SG_ 579 HUT_OD_WorkSts 50;
BA_ "Match" SG_ 579 HUT_OD_WorkSts "HUT_OD_WorkSts";
BA_ "Origin" SG_ 579 HUT_OD_WorkSts "fuel,ev";
BA_ "GenSigCycleTime" SG_ 579 HUT_OD_Obj_Timestamp 50;
BA_ "Match" SG_ 579 HUT_OD_Obj_Timestamp "HUT_OD_Obj_Timestamp";
BA_ "Origin" SG_ 579 HUT_OD_Obj_Timestamp "fuel,ev";
BA_ "GenSigCycleTime" SG_ 579 HUT_FSD1_distance 50;
BA_ "Match" SG_ 579 HUT_FSD1_distance "HUT_FSD1_distance";
BA_ "Origin" SG_ 579 HUT_FSD1_distance "fuel,ev";
BA_ "GenSigCycleTime" SG_ 579 HUT_FSD2_distance 50;
BA_ "Match" SG_ 579 HUT_FSD2_distance "HUT_FSD2_distance";
BA_ "Origin" SG_ 579 HUT_FSD2_distance "fuel,ev";
BA_ "GenSigCycleTime" SG_ 579 HUT_FSD3_distance 50;
BA_ "Match" SG_ 579 HUT_FSD3_distance "HUT_FSD3_distance";
BA_ "Origin" SG_ 579 HUT_FSD3_distance "fuel,ev";
BA_ "GenSigCycleTime" SG_ 579 HUT_FSD4_distance 50;
BA_ "Match" SG_ 579 HUT_FSD4_distance "HUT_FSD4_distance";
BA_ "Origin" SG_ 579 HUT_FSD4_distance "fuel,ev";
BA_ "GenSigCycleTime" SG_ 579 HUT_FSD5_distance 50;
BA_ "Match" SG_ 579 HUT_FSD5_distance "HUT_FSD5_distance";
BA_ "Origin" SG_ 579 HUT_FSD5_distance "fuel,ev";
BA_ "GenSigCycleTime" SG_ 579 HUT_FSD6_distance 50;
BA_ "Match" SG_ 579 HUT_FSD6_distance "HUT_FSD6_distance";
BA_ "Origin" SG_ 579 HUT_FSD6_distance "fuel,ev";
BA_ "GenSigCycleTime" SG_ 579 HUT_FSD7_distance 50;
BA_ "Match" SG_ 579 HUT_FSD7_distance "HUT_FSD7_distance";
BA_ "Origin" SG_ 579 HUT_FSD7_distance "fuel,ev";
BA_ "GenSigCycleTime" SG_ 579 HUT_FSD8_distance 50;
BA_ "Match" SG_ 579 HUT_FSD8_distance "HUT_FSD8_distance";
BA_ "Origin" SG_ 579 HUT_FSD8_distance "fuel,ev";
BA_ "GenSigCycleTime" SG_ 579 HUT_FSD9_distance 50;
BA_ "Match" SG_ 579 HUT_FSD9_distance "HUT_FSD9_distance";
BA_ "Origin" SG_ 579 HUT_FSD9_distance "fuel,ev";
BA_ "GenSigCycleTime" SG_ 579 HUT_FSD10_distance 50;
BA_ "Match" SG_ 579 HUT_FSD10_distance "HUT_FSD10_distance";
BA_ "Origin" SG_ 579 HUT_FSD10_distance "fuel,ev";
BA_ "GenSigCycleTime" SG_ 579 HUT_FSD11_distance 50;
BA_ "Match" SG_ 579 HUT_FSD11_distance "HUT_FSD11_distance";
BA_ "Origin" SG_ 579 HUT_FSD11_distance "fuel,ev";
BA_ "GenSigCycleTime" SG_ 579 HUT_FSD12_distance 50;
BA_ "Match" SG_ 579 HUT_FSD12_distance "HUT_FSD12_distance";
BA_ "Origin" SG_ 579 HUT_FSD12_distance "fuel,ev";
BA_ "GenSigCycleTime" SG_ 579 HUT_FSD13_distance 50;
BA_ "Match" SG_ 579 HUT_FSD13_distance "HUT_FSD13_distance";
BA_ "Origin" SG_ 579 HUT_FSD13_distance "fuel,ev";
BA_ "GenSigCycleTime" SG_ 579 HUT_FSD14_distance 50;
BA_ "Match" SG_ 579 HUT_FSD14_distance "HUT_FSD14_distance";
BA_ "Origin" SG_ 579 HUT_FSD14_distance "fuel,ev";
BA_ "GenSigCycleTime" SG_ 579 HUT_FSD15_distance 50;
BA_ "Match" SG_ 579 HUT_FSD15_distance "HUT_FSD15_distance";
BA_ "Origin" SG_ 579 HUT_FSD15_distance "fuel,ev";
BA_ "GenSigCycleTime" SG_ 579 HUT_FSD16_distance 50;
BA_ "Match" SG_ 579 HUT_FSD16_distance "HUT_FSD16_distance";
BA_ "Origin" SG_ 579 HUT_FSD16_distance "fuel,ev";
BA_ "GenSigCycleTime" SG_ 579 HUT_FSD17_distance 50;
BA_ "Match" SG_ 579 HUT_FSD17_distance "HUT_FSD17_distance";
BA_ "Origin" SG_ 579 HUT_FSD17_distance "fuel,ev";
BA_ "GenSigCycleTime" SG_ 579 HUT_FSD18_distance 50;
BA_ "Match" SG_ 579 HUT_FSD18_distance "HUT_FSD18_distance";
BA_ "Origin" SG_ 579 HUT_FSD18_distance "fuel,ev";
BA_ "GenSigCycleTime" SG_ 579 NOH_Swt_Req 50;
BA_ "Match" SG_ 579 NOH_Swt_Req "NOH_Swt_Req";
BA_ "Origin" SG_ 579 NOH_Swt_Req "fuel,ev";
BA_ "GenSigCycleTime" SG_ 579 NOH_Act_Req 50;
BA_ "Match" SG_ 579 NOH_Act_Req "NOH_Act_Req";
BA_ "Origin" SG_ 579 NOH_Act_Req "fuel,ev";
BA_ "GenSigSendType" SG_ 474 SlotNum_VR 2;
BA_ "Match" SG_ 474 SlotNum_VR "SlotNum_VR";
BA_ "Origin" SG_ 474 SlotNum_VR "fuel,ev";
BA_ "GenSigSendType" SG_ 474 UserDefinedParkCmd 2;
BA_ "Match" SG_ 474 UserDefinedParkCmd "UserDefinedParkCmd";
BA_ "Origin" SG_ 474 UserDefinedParkCmd "fuel,ev";
BA_ "GenSigSendType" SG_ 474 HUT_HAVP_Set_Starting 2;
BA_ "Match" SG_ 474 HUT_HAVP_Set_Starting "HUT_HAVP_Set_Starting";
BA_ "Origin" SG_ 474 HUT_HAVP_Set_Starting "fuel,ev";
BA_ "GenSigSendType" SG_ 474 HUT_HAVP_Set_Path_Ending 2;
BA_ "Match" SG_ 474 HUT_HAVP_Set_Path_Ending "HUT_HAVP_Set_Path_Ending";
BA_ "Origin" SG_ 474 HUT_HAVP_Set_Path_Ending "fuel,ev";
BA_ "GenSigSendType" SG_ 474 HUT_HAVP_APA_Permit 2;
BA_ "Match" SG_ 474 HUT_HAVP_APA_Permit "HUT_HAVP_APA_Permit";
BA_ "Origin" SG_ 474 HUT_HAVP_APA_Permit "fuel,ev";
BA_ "GenSigSendType" SG_ 474 UserDefPrkMenuSelCmd 2;
BA_ "Match" SG_ 474 UserDefPrkMenuSelCmd "UserDefPrkMenuSelCmd";
BA_ "Origin" SG_ 474 UserDefPrkMenuSelCmd "fuel,ev";
BA_ "GenSigSendType" SG_ 474 HUT_HAVP_SelfParLot_Ending 2;
BA_ "Match" SG_ 474 HUT_HAVP_SelfParLot_Ending "HUT_HAVP_SelfParLot_Ending";
BA_ "Origin" SG_ 474 HUT_HAVP_SelfParLot_Ending "fuel,ev";
BA_ "GenSigSendType" SG_ 474 HUT_HAVP_Return_Btn 2;
BA_ "Match" SG_ 474 HUT_HAVP_Return_Btn "HUT_HAVP_Return_Btn";
BA_ "Origin" SG_ 474 HUT_HAVP_Return_Btn "fuel,ev";
BA_ "GenSigSendType" SG_ 475 HUT_ExternalDevice 2;
BA_ "Match" SG_ 475 HUT_ExternalDevice "HUT_ExternalDevice";
BA_ "Origin" SG_ 475 HUT_ExternalDevice "fuel,ev";
BA_ "GenSigSendType" SG_ 871 DomeLmpDlyTimSet 2;
BA_ "GenSigStartValue" SG_ 871 DomeLmpDlyTimSet 1;
BA_ "Match" SG_ 871 DomeLmpDlyTimSet "DomeLmpDlyTimSet";
BA_ "Origin" SG_ 871 DomeLmpDlyTimSet "fuel,ev";
BA_ "GenSigSendType" SG_ 871 FolwMeHomeDlyTimSet 2;
BA_ "GenSigStartValue" SG_ 871 FolwMeHomeDlyTimSet 1;
BA_ "Match" SG_ 871 FolwMeHomeDlyTimSet "FolwMeHomeDlyTimSet";
BA_ "Origin" SG_ 871 FolwMeHomeDlyTimSet "fuel,ev";
BA_ "GenSigSendType" SG_ 871 TranPMode_Req 2;
BA_ "Match" SG_ 871 TranPMode_Req "TranPMode_Req";
BA_ "Origin" SG_ 871 TranPMode_Req "fuel,ev";
BA_ "GenSigSendType" SG_ 871 RearviewFoldModSet 2;
BA_ "GenSigStartValue" SG_ 871 RearviewFoldModSet 1;
BA_ "Match" SG_ 871 RearviewFoldModSet "RearviewFoldModSet";
BA_ "Origin" SG_ 871 RearviewFoldModSet "fuel,ev";
BA_ "GenSigSendType" SG_ 871 BattSaveDelayTimeSet 2;
BA_ "GenSigStartValue" SG_ 871 BattSaveDelayTimeSet 1;
BA_ "Match" SG_ 871 BattSaveDelayTimeSet "BattSaveDelayTimeSet";
BA_ "Origin" SG_ 871 BattSaveDelayTimeSet "fuel,ev";
BA_ "GenSigSendType" SG_ 871 ACDualReq_TC 2;
BA_ "Match" SG_ 871 ACDualReq_TC "ACDualReq_TC";
BA_ "Origin" SG_ 871 ACDualReq_TC "fuel,ev";
BA_ "GenSigSendType" SG_ 871 ACAutoModReq_TC 2;
BA_ "Match" SG_ 871 ACAutoModReq_TC "ACAutoModReq_TC";
BA_ "Origin" SG_ 871 ACAutoModReq_TC "fuel,ev";
BA_ "GenSigSendType" SG_ 871 ACAirInletReq_TC 2;
BA_ "Match" SG_ 871 ACAirInletReq_TC "ACAirInletReq_TC";
BA_ "Origin" SG_ 871 ACAirInletReq_TC "fuel,ev";
BA_ "GenSigSendType" SG_ 871 ACFrntHMIDis_TC 2;
BA_ "Match" SG_ 871 ACFrntHMIDis_TC "ACFrntHMIDis_TC";
BA_ "Origin" SG_ 871 ACFrntHMIDis_TC "fuel,ev";
BA_ "GenSigSendType" SG_ 871 ACRearHMIDis_TC 2;
BA_ "Match" SG_ 871 ACRearHMIDis_TC "ACRearHMIDis_TC";
BA_ "Origin" SG_ 871 ACRearHMIDis_TC "fuel,ev";
BA_ "GenSigSendType" SG_ 871 ACAQSReq_TC 2;
BA_ "Match" SG_ 871 ACAQSReq_TC "ACAQSReq_TC";
BA_ "Origin" SG_ 871 ACAQSReq_TC "fuel,ev";
BA_ "GenSigSendType" SG_ 871 ACCmprReq_TC 2;
BA_ "Match" SG_ 871 ACCmprReq_TC "ACCmprReq_TC";
BA_ "Origin" SG_ 871 ACCmprReq_TC "fuel,ev";
BA_ "GenSigSendType" SG_ 871 ACFrntDefrstReq_TC 2;
BA_ "Match" SG_ 871 ACFrntDefrstReq_TC "ACFrntDefrstReq_TC";
BA_ "Origin" SG_ 871 ACFrntDefrstReq_TC "fuel,ev";
BA_ "GenSigSendType" SG_ 871 ACFrntBlwrSpdDecReq_TC 2;
BA_ "Match" SG_ 871 ACFrntBlwrSpdDecReq_TC "ACFrntBlwrSpdDecReq_TC";
BA_ "Origin" SG_ 871 ACFrntBlwrSpdDecReq_TC "fuel,ev";
BA_ "GenSigSendType" SG_ 871 ACRearBlwrSpdDecReq_TC 2;
BA_ "Match" SG_ 871 ACRearBlwrSpdDecReq_TC "ACRearBlwrSpdDecReq_TC";
BA_ "Origin" SG_ 871 ACRearBlwrSpdDecReq_TC "fuel,ev";
BA_ "GenSigSendType" SG_ 871 ACRearBlwrSpdIncReq_TC 2;
BA_ "Match" SG_ 871 ACRearBlwrSpdIncReq_TC "ACRearBlwrSpdIncReq_TC";
BA_ "Origin" SG_ 871 ACRearBlwrSpdIncReq_TC "fuel,ev";
BA_ "GenSigSendType" SG_ 871 DrvDrowsnsDetnSet 2;
BA_ "GenSigStartValue" SG_ 871 DrvDrowsnsDetnSet 1;
BA_ "Match" SG_ 871 DrvDrowsnsDetnSet "DrvDrowsnsDetnSet";
BA_ "Origin" SG_ 871 DrvDrowsnsDetnSet "fuel,ev";
BA_ "GenSigSendType" SG_ 871 ACFrntBlwrSpdIncReq_TC 2;
BA_ "Match" SG_ 871 ACFrntBlwrSpdIncReq_TC "ACFrntBlwrSpdIncReq_TC";
BA_ "Origin" SG_ 871 ACFrntBlwrSpdIncReq_TC "fuel,ev";
BA_ "GenSigSendType" SG_ 871 ACDrvAirDistribModReq_TC 2;
BA_ "Match" SG_ 871 ACDrvAirDistribModReq_TC "ACDrvAirDistribModReq_TC";
BA_ "Origin" SG_ 871 ACDrvAirDistribModReq_TC "fuel,ev";
BA_ "GenSigSendType" SG_ 871 ACDrvTempDecReq_TC 2;
BA_ "Match" SG_ 871 ACDrvTempDecReq_TC "ACDrvTempDecReq_TC";
BA_ "Origin" SG_ 871 ACDrvTempDecReq_TC "fuel,ev";
BA_ "GenSigSendType" SG_ 871 ChairMemPosnEna 2;
BA_ "GenSigStartValue" SG_ 871 ChairMemPosnEna 1;
BA_ "Match" SG_ 871 ChairMemPosnEna "ChairMemPosnEna";
BA_ "Origin" SG_ 871 ChairMemPosnEna "fuel,ev";
BA_ "GenSigSendType" SG_ 871 ACDrvTempIncReq_TC 2;
BA_ "Match" SG_ 871 ACDrvTempIncReq_TC "ACDrvTempIncReq_TC";
BA_ "Origin" SG_ 871 ACDrvTempIncReq_TC "fuel,ev";
BA_ "GenSigSendType" SG_ 871 ACFrntPassTempDecReq_TC 2;
BA_ "Match" SG_ 871 ACFrntPassTempDecReq_TC "ACFrntPassTempDecReq_TC";
BA_ "Origin" SG_ 871 ACFrntPassTempDecReq_TC "fuel,ev";
BA_ "GenSigSendType" SG_ 871 ACFrntPassTempIncReq_TC 2;
BA_ "Match" SG_ 871 ACFrntPassTempIncReq_TC "ACFrntPassTempIncReq_TC";
BA_ "Origin" SG_ 871 ACFrntPassTempIncReq_TC "fuel,ev";
BA_ "GenSigSendType" SG_ 871 ACAIUReq_TC 2;
BA_ "Match" SG_ 871 ACAIUReq_TC "ACAIUReq_TC";
BA_ "Origin" SG_ 871 ACAIUReq_TC "fuel,ev";
BA_ "GenSigSendType" SG_ 871 ACOffReq_TC 2;
BA_ "Match" SG_ 871 ACOffReq_TC "ACOffReq_TC";
BA_ "Origin" SG_ 871 ACOffReq_TC "fuel,ev";
BA_ "GenSigSendType" SG_ 871 ACBlwrsteplsSpdReq_TC 2;
BA_ "Match" SG_ 871 ACBlwrsteplsSpdReq_TC "ACBlwrsteplsSpdReq_TC";
BA_ "Origin" SG_ 871 ACBlwrsteplsSpdReq_TC "fuel,ev";
BA_ "GenSigSendType" SG_ 871 ACZoneReq_TC 2;
BA_ "Match" SG_ 871 ACZoneReq_TC "ACZoneReq_TC";
BA_ "Origin" SG_ 871 ACZoneReq_TC "fuel,ev";
BA_ "GenSigSendType" SG_ 68 ALCMStatSwt_OLE 2;
BA_ "Match" SG_ 68 ALCMStatSwt_OLE "ALCMStatSwt_OLE";
BA_ "Origin" SG_ 68 ALCMStatSwt_OLE "fuel";
BA_ "GenSigSendType" SG_ 68 ALCMClrSet_OLE 2;
BA_ "Match" SG_ 68 ALCMClrSet_OLE "ALCMClrSet_OLE";
BA_ "Origin" SG_ 68 ALCMClrSet_OLE "fuel";
BA_ "GenSigSendType" SG_ 68 ALCMDynModSet_OLE 2;
BA_ "Match" SG_ 68 ALCMDynModSet_OLE "ALCMDynModSet_OLE";
BA_ "Origin" SG_ 68 ALCMDynModSet_OLE "fuel";
BA_ "GenSigSendType" SG_ 68 ALCMLightLvlSet_OLE 2;
BA_ "GenSigStartValue" SG_ 68 ALCMLightLvlSet_OLE 5;
BA_ "Match" SG_ 68 ALCMLightLvlSet_OLE "ALCMLightLvlSet_OLE";
BA_ "Origin" SG_ 68 ALCMLightLvlSet_OLE "fuel";
BA_ "GenSigSendType" SG_ 68 ALCMRhmSwt_OLE 2;
BA_ "GenSigStartValue" SG_ 68 ALCMRhmSwt_OLE 1;
BA_ "Match" SG_ 68 ALCMRhmSwt_OLE "ALCMRhmSwt_OLE";
BA_ "Origin" SG_ 68 ALCMRhmSwt_OLE "fuel";
BA_ "GenSigSendType" SG_ 68 ALCMBreSwt_OLE 2;
BA_ "Match" SG_ 68 ALCMBreSwt_OLE "ALCMBreSwt_OLE";
BA_ "Origin" SG_ 68 ALCMBreSwt_OLE "fuel";
BA_ "GenSigSendType" SG_ 68 ALCMRdmSwt_OLE 2;
BA_ "Match" SG_ 68 ALCMRdmSwt_OLE "ALCMRdmSwt_OLE";
BA_ "Origin" SG_ 68 ALCMRdmSwt_OLE "fuel";
BA_ "GenSigSendType" SG_ 68 Rdm_SingleColorNr 2;
BA_ "GenSigStartValue" SG_ 68 Rdm_SingleColorNr 8;
BA_ "Match" SG_ 68 Rdm_SingleColorNr "Rdm_SingleColorNr";
BA_ "Origin" SG_ 68 Rdm_SingleColorNr "fuel";
BA_ "GenSigSendType" SG_ 68 HUT_VMDRTmpMonFctnSet 2;
BA_ "Match" SG_ 68 HUT_VMDRTmpMonFctnSet "HUT_VMDRTmpMonFctnSet";
BA_ "Origin" SG_ 68 HUT_VMDRTmpMonFctnSet "fuel,ev";
BA_ "GenSigSendType" SG_ 68 HUT_VMDRInitAlarmDlySet 2;
BA_ "Match" SG_ 68 HUT_VMDRInitAlarmDlySet "HUT_VMDRInitAlarmDlySet";
BA_ "Origin" SG_ 68 HUT_VMDRInitAlarmDlySet "fuel,ev";
BA_ "GenSigSendType" SG_ 68 OTA_UpgrdModReq 2;
BA_ "Match" SG_ 68 OTA_UpgrdModReq "OTA_UpgrdModReq";
BA_ "Origin" SG_ 68 OTA_UpgrdModReq "fuel,ev";
BA_ "GenSigSendType" SG_ 817 ACDualReq_VR 2;
BA_ "Match" SG_ 817 ACDualReq_VR "ACDualReq_VR";
BA_ "Origin" SG_ 817 ACDualReq_VR "fuel,ev";
BA_ "GenSigSendType" SG_ 817 ACAQSReq_VR 2;
BA_ "Match" SG_ 817 ACAQSReq_VR "ACAQSReq_VR";
BA_ "Origin" SG_ 817 ACAQSReq_VR "fuel,ev";
BA_ "GenSigSendType" SG_ 817 ACRearDefrstReq_VR 2;
BA_ "Match" SG_ 817 ACRearDefrstReq_VR "ACRearDefrstReq_VR";
BA_ "Origin" SG_ 817 ACRearDefrstReq_VR "fuel,ev";
BA_ "GenSigSendType" SG_ 817 ACPassTempReq_VR 2;
BA_ "Match" SG_ 817 ACPassTempReq_VR "ACPassTempReq_VR";
BA_ "Origin" SG_ 817 ACPassTempReq_VR "fuel,ev";
BA_ "GenSigSendType" SG_ 817 ACAIUReq_VR 2;
BA_ "Match" SG_ 817 ACAIUReq_VR "ACAIUReq_VR";
BA_ "Origin" SG_ 817 ACAIUReq_VR "fuel,ev";
BA_ "GenSigSendType" SG_ 817 ALCMStatSwt 2;
BA_ "Match" SG_ 817 ALCMStatSwt "ALCMStatSwt";
BA_ "Origin" SG_ 817 ALCMStatSwt "fuel,ev";
BA_ "GenSigSendType" SG_ 817 ALCMDynSwt 2;
BA_ "Match" SG_ 817 ALCMDynSwt "ALCMDynSwt";
BA_ "Origin" SG_ 817 ALCMDynSwt "fuel,ev";
BA_ "GenSigSendType" SG_ 817 ALCMClrSet 2;
BA_ "Match" SG_ 817 ALCMClrSet "ALCMClrSet";
BA_ "Origin" SG_ 817 ALCMClrSet "fuel,ev";
BA_ "GenSigSendType" SG_ 817 ALCMRhmSwt 2;
BA_ "GenSigStartValue" SG_ 817 ALCMRhmSwt 1;
BA_ "Match" SG_ 817 ALCMRhmSwt "ALCMRhmSwt";
BA_ "Origin" SG_ 817 ALCMRhmSwt "fuel,ev";
BA_ "GenSigSendType" SG_ 817 IPVolSet 2;
BA_ "GenSigStartValue" SG_ 817 IPVolSet 15;
BA_ "Match" SG_ 817 IPVolSet "IPVolSet";
BA_ "Origin" SG_ 817 IPVolSet "fuel,ev";
BA_ "GenSigSendType" SG_ 817 PASSwtReq_VR 2;
BA_ "Match" SG_ 817 PASSwtReq_VR "PASSwtReq_VR";
BA_ "Origin" SG_ 817 PASSwtReq_VR "fuel,ev";
BA_ "GenSigSendType" SG_ 817 HUT_BeanIDReq 2;
BA_ "Match" SG_ 817 HUT_BeanIDReq "HUT_BeanIDReq";
BA_ "Origin" SG_ 817 HUT_BeanIDReq "fuel,ev";
BA_ "GenSigSendType" SG_ 817 HUT_EgyRecvrySet 2;
BA_ "Match" SG_ 817 HUT_EgyRecvrySet "HUT_EgyRecvrySet";
BA_ "Origin" SG_ 817 HUT_EgyRecvrySet "ev";
BA_ "GenSigCycleTime" SG_ 943 WeatherCdn 1000;
BA_ "Match" SG_ 943 WeatherCdn "WeatherCdn";
BA_ "Origin" SG_ 943 WeatherCdn "fuel,ev";
BA_ "GenSigCycleTime" SG_ 943 PitchAng 1000;
BA_ "Match" SG_ 943 PitchAng "PitchAng";
BA_ "Origin" SG_ 943 PitchAng "fuel,ev";
BA_ "GenSigCycleTime" SG_ 943 PitchAngSign 1000;
BA_ "Match" SG_ 943 PitchAngSign "PitchAngSign";
BA_ "Origin" SG_ 943 PitchAngSign "fuel,ev";
BA_ "GenSigCycleTime" SG_ 796 AudioMuteSts 100;
BA_ "Match" SG_ 796 AudioMuteSts "AudioMuteSts";
BA_ "Origin" SG_ 796 AudioMuteSts "fuel,ev";
BA_ "GenSigCycleTime" SG_ 796 OrvmPosnEnaSts 100;
BA_ "Match" SG_ 796 OrvmPosnEnaSts "OrvmPosnEnaSts";
BA_ "Origin" SG_ 796 OrvmPosnEnaSts "fuel,ev";
BA_ "GenSigCycleTime" SG_ 796 ORVMFoldSwt_HUT 100;
BA_ "Match" SG_ 796 ORVMFoldSwt_HUT "ORVMFoldSwt_HUT";
BA_ "Origin" SG_ 796 ORVMFoldSwt_HUT "fuel,ev";
BA_ "GenSigCycleTime" SG_ 796 ORVMLensAdjmt_HUT 100;
BA_ "Match" SG_ 796 ORVMLensAdjmt_HUT "ORVMLensAdjmt_HUT";
BA_ "Origin" SG_ 796 ORVMLensAdjmt_HUT "fuel,ev";
BA_ "GenSigCycleTime" SG_ 796 DrvSeatAdjmt_HUT 100;
BA_ "Match" SG_ 796 DrvSeatAdjmt_HUT "DrvSeatAdjmt_HUT";
BA_ "Origin" SG_ 796 DrvSeatAdjmt_HUT "fuel,ev";
BA_ "GenSigCycleTime" SG_ 796 DrivingModReq_VR 100;
BA_ "GenSigStartValue" SG_ 796 DrivingModReq_VR 15;
BA_ "Match" SG_ 796 DrivingModReq_VR "DrivingModReq_VR";
BA_ "Origin" SG_ 796 DrivingModReq_VR "fuel,ev";
BA_ "GenSigCycleTime" SG_ 796 DWD_WorkCmd 100;
BA_ "Match" SG_ 796 DWD_WorkCmd "DWD_WorkCmd";
BA_ "Origin" SG_ 796 DWD_WorkCmd "fuel,ev";
BA_ "GenSigCycleTime" SG_ 796 DampgDrvModeReq 100;
BA_ "GenSigStartValue" SG_ 796 DampgDrvModeReq 1;
BA_ "Match" SG_ 796 DampgDrvModeReq "DampgDrvModeReq";
BA_ "Origin" SG_ 796 DampgDrvModeReq "fuel,ev";
BA_ "GenSigCycleTime" SG_ 796 VSGSwtSet 100;
BA_ "GenSigStartValue" SG_ 796 VSGSwtSet 1;
BA_ "Match" SG_ 796 VSGSwtSet "VSGSwtSet";
BA_ "Origin" SG_ 796 VSGSwtSet "ev";
BA_ "GenSigSendType" SG_ 494 ACOperMod_TC 2;
BA_ "Match" SG_ 494 ACOperMod_TC "ACOperMod_TC";
BA_ "Origin" SG_ 494 ACOperMod_TC "fuel,ev";
BA_ "GenSigSendType" SG_ 494 ACOperMod_VR 2;
BA_ "Match" SG_ 494 ACOperMod_VR "ACOperMod_VR";
BA_ "Origin" SG_ 494 ACOperMod_VR "fuel,ev";
BA_ "GenSigSendType" SG_ 494 ACDrvSetTempSteplsReq_TC 2;
BA_ "Match" SG_ 494 ACDrvSetTempSteplsReq_TC "ACDrvSetTempSteplsReq_TC";
BA_ "Origin" SG_ 494 ACDrvSetTempSteplsReq_TC "fuel,ev";
BA_ "GenSigSendType" SG_ 494 ACPassSetTempSteplsReq_TC 2;
BA_ "Match" SG_ 494 ACPassSetTempSteplsReq_TC "ACPassSetTempSteplsReq_TC";
BA_ "Origin" SG_ 494 ACPassSetTempSteplsReq_TC "fuel,ev";
BA_ "GenSigSendType" SG_ 494 SDWSwtSet 2;
BA_ "Match" SG_ 494 SDWSwtSet "SDWSwtSet";
BA_ "Origin" SG_ 494 SDWSwtSet "fuel,ev";
BA_ "GenSigSendType" SG_ 494 APSSwtReq_VR 2;
BA_ "Match" SG_ 494 APSSwtReq_VR "APSSwtReq_VR";
BA_ "Origin" SG_ 494 APSSwtReq_VR "fuel,ev";
BA_ "GenSigSendType" SG_ 494 APSPrkgTypSeln 2;
BA_ "Match" SG_ 494 APSPrkgTypSeln "APSPrkgTypSeln";
BA_ "Origin" SG_ 494 APSPrkgTypSeln "fuel,ev";
BA_ "GenSigSendType" SG_ 494 SunShadeSwtReq_VR 2;
BA_ "Match" SG_ 494 SunShadeSwtReq_VR "SunShadeSwtReq_VR";
BA_ "Origin" SG_ 494 SunShadeSwtReq_VR "fuel,ev";
BA_ "GenSigSendType" SG_ 494 SunRoofSwtReq_VR 2;
BA_ "Match" SG_ 494 SunRoofSwtReq_VR "SunRoofSwtReq_VR";
BA_ "Origin" SG_ 494 SunRoofSwtReq_VR "fuel,ev";
BA_ "GenSigSendType" SG_ 494 SportModLightSet 2;
BA_ "GenSigStartValue" SG_ 494 SportModLightSet 1;
BA_ "Match" SG_ 494 SportModLightSet "SportModLightSet";
BA_ "Origin" SG_ 494 SportModLightSet "fuel,ev";
BA_ "GenSigSendType" SG_ 494 ABSLmpSet 2;
BA_ "GenSigStartValue" SG_ 494 ABSLmpSet 1;
BA_ "Match" SG_ 494 ABSLmpSet "ABSLmpSet";
BA_ "Origin" SG_ 494 ABSLmpSet "fuel,ev";
BA_ "GenSigSendType" SG_ 494 AutoWshWipSet 2;
BA_ "GenSigStartValue" SG_ 494 AutoWshWipSet 2;
BA_ "Match" SG_ 494 AutoWshWipSet "AutoWshWipSet";
BA_ "Origin" SG_ 494 AutoWshWipSet "fuel,ev";
BA_ "GenSigSendType" SG_ 494 SeekVehSet 2;
BA_ "Match" SG_ 494 SeekVehSet "SeekVehSet";
BA_ "Origin" SG_ 494 SeekVehSet "fuel,ev";
BA_ "GenSigSendType" SG_ 494 SpdAutoLockModSet 2;
BA_ "GenSigStartValue" SG_ 494 SpdAutoLockModSet 2;
BA_ "Match" SG_ 494 SpdAutoLockModSet "SpdAutoLockModSet";
BA_ "Origin" SG_ 494 SpdAutoLockModSet "fuel,ev";
BA_ "GenSigSendType" SG_ 494 ParkLmpSet 2;
BA_ "GenSigStartValue" SG_ 494 ParkLmpSet 1;
BA_ "Match" SG_ 494 ParkLmpSet "ParkLmpSet";
BA_ "Origin" SG_ 494 ParkLmpSet "fuel,ev";
BA_ "GenSigSendType" SG_ 494 DoorUnlockModSet 2;
BA_ "Match" SG_ 494 DoorUnlockModSet "DoorUnlockModSet";
BA_ "Origin" SG_ 494 DoorUnlockModSet "fuel,ev";
BA_ "GenSigSendType" SG_ 494 SteerWheelHeatSwtReq 2;
BA_ "GenSigStartValue" SG_ 494 SteerWheelHeatSwtReq 1;
BA_ "Match" SG_ 494 SteerWheelHeatSwtReq "SteerWheelHeatSwtReq";
BA_ "Origin" SG_ 494 SteerWheelHeatSwtReq "fuel,ev";
BA_ "GenSigSendType" SG_ 494 PASExitSpdSwt 2;
BA_ "Match" SG_ 494 PASExitSpdSwt "PASExitSpdSwt";
BA_ "Origin" SG_ 494 PASExitSpdSwt "fuel,ev";
BA_ "GenSigSendType" SG_ 494 FrntRearACDispSts 2;
BA_ "Match" SG_ 494 FrntRearACDispSts "FrntRearACDispSts";
BA_ "Origin" SG_ 494 FrntRearACDispSts "fuel,ev";
BA_ "GenSigSendType" SG_ 494 FreshnessValue_HUT15 2;
BA_ "Match" SG_ 494 FreshnessValue_HUT15 "FreshnessValue_HUT15";
BA_ "Origin" SG_ 494 FreshnessValue_HUT15 "fuel,ev";
BA_ "GenSigSendType" SG_ 494 MAC_Check_HUT15 2;
BA_ "Match" SG_ 494 MAC_Check_HUT15 "MAC_Check_HUT15";
BA_ "Origin" SG_ 494 MAC_Check_HUT15 "fuel,ev";
BA_ "GenSigCycleTime" SG_ 840 PowerSet 500;
BA_ "GenSigStartValue" SG_ 840 PowerSet 1;
BA_ "Match" SG_ 840 PowerSet "PowerSet";
BA_ "Origin" SG_ 840 PowerSet "fuel,ev";
BA_ "GenSigCycleTime" SG_ 840 HUT_CallSts_Dialing 500;
BA_ "Match" SG_ 840 HUT_CallSts_Dialing "HUT_CallSts_Dialing";
BA_ "Origin" SG_ 840 HUT_CallSts_Dialing "fuel,ev";
BA_ "GenSigCycleTime" SG_ 840 HUT_CallSts_IncomingCall 500;
BA_ "Match" SG_ 840 HUT_CallSts_IncomingCall "HUT_CallSts_IncomingCall";
BA_ "Origin" SG_ 840 HUT_CallSts_IncomingCall "fuel,ev";
BA_ "GenSigCycleTime" SG_ 840 HUT_CallSts_ongoing 500;
BA_ "Match" SG_ 840 HUT_CallSts_ongoing "HUT_CallSts_ongoing";
BA_ "Origin" SG_ 840 HUT_CallSts_ongoing "fuel,ev";
BA_ "GenSigCycleTime" SG_ 840 HUT_CallTime 500;
BA_ "Match" SG_ 840 HUT_CallTime "HUT_CallTime";
BA_ "Origin" SG_ 840 HUT_CallTime "fuel,ev";
BA_ "GenSigSendType" SG_ 827 BackgroundLightLvlSet 2;
BA_ "GenSigStartValue" SG_ 827 BackgroundLightLvlSet 10;
BA_ "Match" SG_ 827 BackgroundLightLvlSet "BackgroundLightLvlSet";
BA_ "Origin" SG_ 827 BackgroundLightLvlSet "fuel,ev";
BA_ "GenSigSendType" SG_ 827 ManCmpSet 2;
BA_ "GenSigStartValue" SG_ 827 ManCmpSet 5;
BA_ "Match" SG_ 827 ManCmpSet "ManCmpSet";
BA_ "Origin" SG_ 827 ManCmpSet "fuel,ev";
BA_ "GenSigSendType" SG_ 827 DispModSet 2;
BA_ "Match" SG_ 827 DispModSet "DispModSet";
BA_ "Origin" SG_ 827 DispModSet "fuel,ev";
BA_ "GenSigSendType" SG_ 827 WPC_SwtReq 2;
BA_ "GenSigStartValue" SG_ 827 WPC_SwtReq 1;
BA_ "Match" SG_ 827 WPC_SwtReq "WPC_SwtReq";
BA_ "Origin" SG_ 827 WPC_SwtReq "fuel,ev";
BA_ "GenSigSendType" SG_ 827 AVMSwtReq 2;
BA_ "Match" SG_ 827 AVMSwtReq "AVMSwtReq";
BA_ "Origin" SG_ 827 AVMSwtReq "fuel,ev";
BA_ "GenSigSendType" SG_ 827 NaviMediaVolLvlReq 2;
BA_ "GenSigStartValue" SG_ 827 NaviMediaVolLvlReq 3;
BA_ "Match" SG_ 827 NaviMediaVolLvlReq "NaviMediaVolLvlReq";
BA_ "Origin" SG_ 827 NaviMediaVolLvlReq "fuel,ev";
BA_ "GenSigSendType" SG_ 827 AVMMediaVolLvlReq 2;
BA_ "GenSigStartValue" SG_ 827 AVMMediaVolLvlReq 3;
BA_ "Match" SG_ 827 AVMMediaVolLvlReq "AVMMediaVolLvlReq";
BA_ "Origin" SG_ 827 AVMMediaVolLvlReq "fuel,ev";
BA_ "GenSigSendType" SG_ 827 FPASChanSwtReq 2;
BA_ "Match" SG_ 827 FPASChanSwtReq "FPASChanSwtReq";
BA_ "Origin" SG_ 827 FPASChanSwtReq "fuel,ev";
BA_ "GenSigSendType" SG_ 827 RPASChanSwtReq 2;
BA_ "Match" SG_ 827 RPASChanSwtReq "RPASChanSwtReq";
BA_ "Origin" SG_ 827 RPASChanSwtReq "fuel,ev";
BA_ "GenSigSendType" SG_ 827 ACRearBlwrSpdReq_VR 2;
BA_ "Match" SG_ 827 ACRearBlwrSpdReq_VR "ACRearBlwrSpdReq_VR";
BA_ "Origin" SG_ 827 ACRearBlwrSpdReq_VR "fuel,ev";
BA_ "GenSigSendType" SG_ 827 ACRearBlwrsteplsSpdReq_TC 2;
BA_ "Match" SG_ 827 ACRearBlwrsteplsSpdReq_TC "ACRearBlwrsteplsSpdReq_TC";
BA_ "Origin" SG_ 827 ACRearBlwrsteplsSpdReq_TC "fuel,ev";
BA_ "GenSigSendType" SG_ 827 PLGReq_VR 2;
BA_ "Match" SG_ 827 PLGReq_VR "PLGReq_VR";
BA_ "Origin" SG_ 827 PLGReq_VR "fuel,ev";
BA_ "GenSigSendType" SG_ 827 ACRearAirDistribModReq_VR 2;
BA_ "Match" SG_ 827 ACRearAirDistribModReq_VR "ACRearAirDistribModReq_VR";
BA_ "Origin" SG_ 827 ACRearAirDistribModReq_VR "fuel,ev";
BA_ "GenSigSendType" SG_ 827 ACZoneReq_VR 2;
BA_ "Match" SG_ 827 ACZoneReq_VR "ACZoneReq_VR";
BA_ "Origin" SG_ 827 ACZoneReq_VR "fuel,ev";
BA_ "GenSigSendType" SG_ 827 OPDSwtSts 2;
BA_ "GenSigStartValue" SG_ 827 OPDSwtSts 1;
BA_ "Match" SG_ 827 OPDSwtSts "OPDSwtSts";
BA_ "Origin" SG_ 827 OPDSwtSts "ev";
BA_ "GenSigCycleTime" SG_ 1045 ADAS_Meta_MsgTyp 5000;
BA_ "Match" SG_ 1045 ADAS_Meta_MsgTyp "ADAS_Meta_MsgTyp";
BA_ "Origin" SG_ 1045 ADAS_Meta_MsgTyp "fuel,ev";
BA_ "GenSigCycleTime" SG_ 1045 ADAS_Meta_MapProvider 5000;
BA_ "Match" SG_ 1045 ADAS_Meta_MapProvider "ADAS_Meta_MapProvider";
BA_ "Origin" SG_ 1045 ADAS_Meta_MapProvider "fuel,ev";
BA_ "GenSigCycleTime" SG_ 1045 ADAS_Meta_CountryCode 5000;
BA_ "Match" SG_ 1045 ADAS_Meta_CountryCode "ADAS_Meta_CountryCode";
BA_ "Origin" SG_ 1045 ADAS_Meta_CountryCode "fuel,ev";
BA_ "GenSigCycleTime" SG_ 1045 ADAS_Meta_CycCnt 5000;
BA_ "Match" SG_ 1045 ADAS_Meta_CycCnt "ADAS_Meta_CycCnt";
BA_ "Origin" SG_ 1045 ADAS_Meta_CycCnt "fuel,ev";
BA_ "GenSigCycleTime" SG_ 1045 ADAS_Meta_ProtVer_Major 5000;
BA_ "Match" SG_ 1045 ADAS_Meta_ProtVer_Major "ADAS_Meta_ProtVer_Major";
BA_ "Origin" SG_ 1045 ADAS_Meta_ProtVer_Major "fuel,ev";
BA_ "GenSigCycleTime" SG_ 1045 ADAS_Meta_ProtVer_MinorSub 5000;
BA_ "Match" SG_ 1045 ADAS_Meta_ProtVer_MinorSub "ADAS_Meta_ProtVer_MinorSub";
BA_ "Origin" SG_ 1045 ADAS_Meta_ProtVer_MinorSub "fuel,ev";
BA_ "GenSigCycleTime" SG_ 1045 ADAS_Meta_HwVer 5000;
BA_ "Match" SG_ 1045 ADAS_Meta_HwVer "ADAS_Meta_HwVer";
BA_ "Origin" SG_ 1045 ADAS_Meta_HwVer "fuel,ev";
BA_ "GenSigCycleTime" SG_ 1045 ADAS_Meta_DrvSide 5000;
BA_ "GenSigStartValue" SG_ 1045 ADAS_Meta_DrvSide 1;
BA_ "Match" SG_ 1045 ADAS_Meta_DrvSide "ADAS_Meta_DrvSide";
BA_ "Origin" SG_ 1045 ADAS_Meta_DrvSide "fuel,ev";
BA_ "GenSigCycleTime" SG_ 1045 ADAS_Meta_RegionCode 5000;
BA_ "Match" SG_ 1045 ADAS_Meta_RegionCode "ADAS_Meta_RegionCode";
BA_ "Origin" SG_ 1045 ADAS_Meta_RegionCode "fuel,ev";
BA_ "GenSigCycleTime" SG_ 1045 ADAS_Meta_MapVerQtr 5000;
BA_ "Match" SG_ 1045 ADAS_Meta_MapVerQtr "ADAS_Meta_MapVerQtr";
BA_ "Origin" SG_ 1045 ADAS_Meta_MapVerQtr "fuel,ev";
BA_ "GenSigCycleTime" SG_ 1045 ADAS_Meta_MapVerYear 5000;
BA_ "Match" SG_ 1045 ADAS_Meta_MapVerYear "ADAS_Meta_MapVerYear";
BA_ "Origin" SG_ 1045 ADAS_Meta_MapVerYear "fuel,ev";
BA_ "GenSigCycleTime" SG_ 1045 ADAS_Meta_SpdUnits 5000;
BA_ "Match" SG_ 1045 ADAS_Meta_SpdUnits "ADAS_Meta_SpdUnits";
BA_ "Origin" SG_ 1045 ADAS_Meta_SpdUnits "fuel,ev";
BA_ "GenSigCycleTime" SG_ 1045 ADAS_Meta_ProtVer_Minor 5000;
BA_ "Match" SG_ 1045 ADAS_Meta_ProtVer_Minor "ADAS_Meta_ProtVer_Minor";
BA_ "Origin" SG_ 1045 ADAS_Meta_ProtVer_Minor "fuel,ev";
BA_ "GenSigSendType" SG_ 873 RearWinHeatCmd_TC 2;
BA_ "Match" SG_ 873 RearWinHeatCmd_TC "RearWinHeatCmd_TC";
BA_ "Origin" SG_ 873 RearWinHeatCmd_TC "fuel,ev";
BA_ "GenSigSendType" SG_ 873 AMP_MediaCallSourceSet 2;
BA_ "Match" SG_ 873 AMP_MediaCallSourceSet "AMP_MediaCallSourceSet";
BA_ "Origin" SG_ 873 AMP_MediaCallSourceSet "fuel,ev";
BA_ "GenSigSendType" SG_ 873 AMP_NaviSourceSet 2;
BA_ "Match" SG_ 873 AMP_NaviSourceSet "AMP_NaviSourceSet";
BA_ "Origin" SG_ 873 AMP_NaviSourceSet "fuel,ev";
BA_ "GenSigSendType" SG_ 873 AMP_BeepSourceSet 2;
BA_ "Match" SG_ 873 AMP_BeepSourceSet "AMP_BeepSourceSet";
BA_ "Origin" SG_ 873 AMP_BeepSourceSet "fuel,ev";
BA_ "GenSigSendType" SG_ 873 AMP_LRAudioBalanceSet 2;
BA_ "GenSigStartValue" SG_ 873 AMP_LRAudioBalanceSet 10;
BA_ "Match" SG_ 873 AMP_LRAudioBalanceSet "AMP_LRAudioBalanceSet";
BA_ "Origin" SG_ 873 AMP_LRAudioBalanceSet "fuel,ev";
BA_ "GenSigSendType" SG_ 873 AMP_AudioVolVSCModReq 2;
BA_ "GenSigStartValue" SG_ 873 AMP_AudioVolVSCModReq 2;
BA_ "Match" SG_ 873 AMP_AudioVolVSCModReq "AMP_AudioVolVSCModReq";
BA_ "Origin" SG_ 873 AMP_AudioVolVSCModReq "fuel,ev";
BA_ "GenSigSendType" SG_ 873 AMP_FRAudioFaderSet 2;
BA_ "GenSigStartValue" SG_ 873 AMP_FRAudioFaderSet 10;
BA_ "Match" SG_ 873 AMP_FRAudioFaderSet "AMP_FRAudioFaderSet";
BA_ "Origin" SG_ 873 AMP_FRAudioFaderSet "fuel,ev";
BA_ "GenSigSendType" SG_ 873 AMP_LRDrvSideSet 2;
BA_ "Match" SG_ 873 AMP_LRDrvSideSet "AMP_LRDrvSideSet";
BA_ "Origin" SG_ 873 AMP_LRDrvSideSet "fuel,ev";
BA_ "GenSigSendType" SG_ 873 AMP_LowFrqAudioSet 2;
BA_ "GenSigStartValue" SG_ 873 AMP_LowFrqAudioSet 10;
BA_ "Match" SG_ 873 AMP_LowFrqAudioSet "AMP_LowFrqAudioSet";
BA_ "Origin" SG_ 873 AMP_LowFrqAudioSet "fuel,ev";
BA_ "GenSigSendType" SG_ 873 AMP_MuteSet 2;
BA_ "GenSigStartValue" SG_ 873 AMP_MuteSet 1;
BA_ "Match" SG_ 873 AMP_MuteSet "AMP_MuteSet";
BA_ "Origin" SG_ 873 AMP_MuteSet "fuel,ev";
BA_ "GenSigSendType" SG_ 873 AMP_MidFrqAudioSet 2;
BA_ "GenSigStartValue" SG_ 873 AMP_MidFrqAudioSet 10;
BA_ "Match" SG_ 873 AMP_MidFrqAudioSet "AMP_MidFrqAudioSet";
BA_ "Origin" SG_ 873 AMP_MidFrqAudioSet "fuel,ev";
BA_ "GenSigSendType" SG_ 873 AMP_HighFrqAudioSet 2;
BA_ "GenSigStartValue" SG_ 873 AMP_HighFrqAudioSet 10;
BA_ "Match" SG_ 873 AMP_HighFrqAudioSet "AMP_HighFrqAudioSet";
BA_ "Origin" SG_ 873 AMP_HighFrqAudioSet "fuel,ev";
BA_ "GenSigSendType" SG_ 873 T_box_ECallSet 2;
BA_ "Match" SG_ 873 T_box_ECallSet "T_box_ECallSet";
BA_ "Origin" SG_ 873 T_box_ECallSet "fuel,ev";
BA_ "GenSigSendType" SG_ 873 QLISurroundSet 2;
BA_ "GenSigStartValue" SG_ 873 QLISurroundSet 1;
BA_ "Match" SG_ 873 QLISurroundSet "QLISurroundSet";
BA_ "Origin" SG_ 873 QLISurroundSet "fuel,ev";
BA_ "GenSigSendType" SG_ 873 ANCSwtSet 2;
BA_ "GenSigStartValue" SG_ 873 ANCSwtSet 1;
BA_ "Match" SG_ 873 ANCSwtSet "ANCSwtSet";
BA_ "Origin" SG_ 873 ANCSwtSet "fuel,ev";
BA_ "GenSigSendType" SG_ 734 ADAS_ProfLong_MsgTyp 2;
BA_ "Match" SG_ 734 ADAS_ProfLong_MsgTyp "ADAS_ProfLong_MsgTyp";
BA_ "Origin" SG_ 734 ADAS_ProfLong_MsgTyp "fuel,ev";
BA_ "GenSigSendType" SG_ 734 ADAS_ProfLong_Offset 2;
BA_ "Match" SG_ 734 ADAS_ProfLong_Offset "ADAS_ProfLong_Offset";
BA_ "Origin" SG_ 734 ADAS_ProfLong_Offset "fuel,ev";
BA_ "GenSigSendType" SG_ 734 ADAS_ProfLong_CycCnt 2;
BA_ "Match" SG_ 734 ADAS_ProfLong_CycCnt "ADAS_ProfLong_CycCnt";
BA_ "Origin" SG_ 734 ADAS_ProfLong_CycCnt "fuel,ev";
BA_ "GenSigSendType" SG_ 734 ADAS_ProfLong_PathIdx 2;
BA_ "Match" SG_ 734 ADAS_ProfLong_PathIdx "ADAS_ProfLong_PathIdx";
BA_ "Origin" SG_ 734 ADAS_ProfLong_PathIdx "fuel,ev";
BA_ "GenSigSendType" SG_ 734 ADAS_ProfLong_ProfTyp 2;
BA_ "Match" SG_ 734 ADAS_ProfLong_ProfTyp "ADAS_ProfLong_ProfTyp";
BA_ "Origin" SG_ 734 ADAS_ProfLong_ProfTyp "fuel,ev";
BA_ "GenSigSendType" SG_ 734 ADAS_ProfLong_CtrlPoint 2;
BA_ "Match" SG_ 734 ADAS_ProfLong_CtrlPoint "ADAS_ProfLong_CtrlPoint";
BA_ "Origin" SG_ 734 ADAS_ProfLong_CtrlPoint "fuel,ev";
BA_ "GenSigSendType" SG_ 734 ADAS_ProfLong_Retr 2;
BA_ "Match" SG_ 734 ADAS_ProfLong_Retr "ADAS_ProfLong_Retr";
BA_ "Origin" SG_ 734 ADAS_ProfLong_Retr "fuel,ev";
BA_ "GenSigSendType" SG_ 734 ADAS_ProfLong_Update 2;
BA_ "Match" SG_ 734 ADAS_ProfLong_Update "ADAS_ProfLong_Update";
BA_ "Origin" SG_ 734 ADAS_ProfLong_Update "fuel,ev";
BA_ "GenSigSendType" SG_ 734 ADAS_ProfLong_Value 2;
BA_ "Match" SG_ 734 ADAS_ProfLong_Value "ADAS_ProfLong_Value";
BA_ "Origin" SG_ 734 ADAS_ProfLong_Value "fuel,ev";
BA_ "GenSigSendType" SG_ 733 ADAS_ProfShort_MsgTyp 2;
BA_ "Match" SG_ 733 ADAS_ProfShort_MsgTyp "ADAS_ProfShort_MsgTyp";
BA_ "Origin" SG_ 733 ADAS_ProfShort_MsgTyp "fuel,ev";
BA_ "GenSigSendType" SG_ 733 ADAS_ProfShort_Offset 2;
BA_ "Match" SG_ 733 ADAS_ProfShort_Offset "ADAS_ProfShort_Offset";
BA_ "Origin" SG_ 733 ADAS_ProfShort_Offset "fuel,ev";
BA_ "GenSigSendType" SG_ 733 ADAS_ProfShort_CycCnt 2;
BA_ "Match" SG_ 733 ADAS_ProfShort_CycCnt "ADAS_ProfShort_CycCnt";
BA_ "Origin" SG_ 733 ADAS_ProfShort_CycCnt "fuel,ev";
BA_ "GenSigSendType" SG_ 733 ADAS_ProfShort_PathIdx 2;
BA_ "Match" SG_ 733 ADAS_ProfShort_PathIdx "ADAS_ProfShort_PathIdx";
BA_ "Origin" SG_ 733 ADAS_ProfShort_PathIdx "fuel,ev";
BA_ "GenSigSendType" SG_ 733 ADAS_ProfShort_ProfTyp 2;
BA_ "Match" SG_ 733 ADAS_ProfShort_ProfTyp "ADAS_ProfShort_ProfTyp";
BA_ "Origin" SG_ 733 ADAS_ProfShort_ProfTyp "fuel,ev";
BA_ "GenSigSendType" SG_ 733 ADAS_ProfShort_CtrlPoint 2;
BA_ "Match" SG_ 733 ADAS_ProfShort_CtrlPoint "ADAS_ProfShort_CtrlPoint";
BA_ "Origin" SG_ 733 ADAS_ProfShort_CtrlPoint "fuel,ev";
BA_ "GenSigSendType" SG_ 733 ADAS_ProfShort_Retr 2;
BA_ "Match" SG_ 733 ADAS_ProfShort_Retr "ADAS_ProfShort_Retr";
BA_ "Origin" SG_ 733 ADAS_ProfShort_Retr "fuel,ev";
BA_ "GenSigSendType" SG_ 733 ADAS_ProfShort_Update 2;
BA_ "Match" SG_ 733 ADAS_ProfShort_Update "ADAS_ProfShort_Update";
BA_ "Origin" SG_ 733 ADAS_ProfShort_Update "fuel,ev";
BA_ "GenSigSendType" SG_ 733 ADAS_ProfShort_AccurClass 2;
BA_ "GenSigStartValue" SG_ 733 ADAS_ProfShort_AccurClass 3;
BA_ "Match" SG_ 733 ADAS_ProfShort_AccurClass "ADAS_ProfShort_AccurClass";
BA_ "Origin" SG_ 733 ADAS_ProfShort_AccurClass "fuel,ev";
BA_ "GenSigSendType" SG_ 733 ADAS_ProfShort_Dist1 2;
BA_ "Match" SG_ 733 ADAS_ProfShort_Dist1 "ADAS_ProfShort_Dist1";
BA_ "Origin" SG_ 733 ADAS_ProfShort_Dist1 "fuel,ev";
BA_ "GenSigSendType" SG_ 733 ADAS_ProfShort_Value0 2;
BA_ "Match" SG_ 733 ADAS_ProfShort_Value0 "ADAS_ProfShort_Value0";
BA_ "Origin" SG_ 733 ADAS_ProfShort_Value0 "fuel,ev";
BA_ "GenSigSendType" SG_ 733 ADAS_ProfShort_Value1 2;
BA_ "Match" SG_ 733 ADAS_ProfShort_Value1 "ADAS_ProfShort_Value1";
BA_ "Origin" SG_ 733 ADAS_ProfShort_Value1 "fuel,ev";
BA_ "GenSigSendType" SG_ 730 ADAS_Seg_MsgTyp 2;
BA_ "Match" SG_ 730 ADAS_Seg_MsgTyp "ADAS_Seg_MsgTyp";
BA_ "Origin" SG_ 730 ADAS_Seg_MsgTyp "fuel,ev";
BA_ "GenSigSendType" SG_ 730 ADAS_Seg_Offset 2;
BA_ "Match" SG_ 730 ADAS_Seg_Offset "ADAS_Seg_Offset";
BA_ "Origin" SG_ 730 ADAS_Seg_Offset "fuel,ev";
BA_ "GenSigSendType" SG_ 730 ADAS_Seg_CycCnt 2;
BA_ "Match" SG_ 730 ADAS_Seg_CycCnt "ADAS_Seg_CycCnt";
BA_ "Origin" SG_ 730 ADAS_Seg_CycCnt "fuel,ev";
BA_ "GenSigSendType" SG_ 730 ADAS_Seg_PathIdx 2;
BA_ "Match" SG_ 730 ADAS_Seg_PathIdx "ADAS_Seg_PathIdx";
BA_ "Origin" SG_ 730 ADAS_Seg_PathIdx "fuel,ev";
BA_ "GenSigSendType" SG_ 730 ADAS_Seg_Tunnel 2;
BA_ "Match" SG_ 730 ADAS_Seg_Tunnel "ADAS_Seg_Tunnel";
BA_ "Origin" SG_ 730 ADAS_Seg_Tunnel "fuel,ev";
BA_ "GenSigSendType" SG_ 730 ADAS_Seg_Brdg 2;
BA_ "Match" SG_ 730 ADAS_Seg_Brdg "ADAS_Seg_Brdg";
BA_ "Origin" SG_ 730 ADAS_Seg_Brdg "fuel,ev";
BA_ "GenSigSendType" SG_ 730 ADAS_Seg_BuildUpArea 2;
BA_ "Match" SG_ 730 ADAS_Seg_BuildUpArea "ADAS_Seg_BuildUpArea";
BA_ "Origin" SG_ 730 ADAS_Seg_BuildUpArea "fuel,ev";
BA_ "GenSigSendType" SG_ 730 ADAS_Seg_Retr 2;
BA_ "Match" SG_ 730 ADAS_Seg_Retr "ADAS_Seg_Retr";
BA_ "Origin" SG_ 730 ADAS_Seg_Retr "fuel,ev";
BA_ "GenSigSendType" SG_ 730 ADAS_Seg_Update 2;
BA_ "Match" SG_ 730 ADAS_Seg_Update "ADAS_Seg_Update";
BA_ "Origin" SG_ 730 ADAS_Seg_Update "fuel,ev";
BA_ "GenSigSendType" SG_ 730 ADAS_Seg_RelProbb 2;
BA_ "Match" SG_ 730 ADAS_Seg_RelProbb "ADAS_Seg_RelProbb";
BA_ "Origin" SG_ 730 ADAS_Seg_RelProbb "fuel,ev";
BA_ "GenSigSendType" SG_ 730 ADAS_Seg_FuncRoadClass 2;
BA_ "Match" SG_ 730 ADAS_Seg_FuncRoadClass "ADAS_Seg_FuncRoadClass";
BA_ "Origin" SG_ 730 ADAS_Seg_FuncRoadClass "fuel,ev";
BA_ "GenSigSendType" SG_ 730 ADAS_Seg_PartOfCalcRoute 2;
BA_ "Match" SG_ 730 ADAS_Seg_PartOfCalcRoute "ADAS_Seg_PartOfCalcRoute";
BA_ "Origin" SG_ 730 ADAS_Seg_PartOfCalcRoute "fuel,ev";
BA_ "GenSigSendType" SG_ 730 ADAS_Seg_CmplxInsct 2;
BA_ "Match" SG_ 730 ADAS_Seg_CmplxInsct "ADAS_Seg_CmplxInsct";
BA_ "Origin" SG_ 730 ADAS_Seg_CmplxInsct "fuel,ev";
BA_ "GenSigSendType" SG_ 730 ADAS_Seg_FormOfWay 2;
BA_ "Match" SG_ 730 ADAS_Seg_FormOfWay "ADAS_Seg_FormOfWay";
BA_ "Origin" SG_ 730 ADAS_Seg_FormOfWay "fuel,ev";
BA_ "GenSigSendType" SG_ 730 ADAS_Seg_EffSpdLmt 2;
BA_ "Match" SG_ 730 ADAS_Seg_EffSpdLmt "ADAS_Seg_EffSpdLmt";
BA_ "Origin" SG_ 730 ADAS_Seg_EffSpdLmt "fuel,ev";
BA_ "GenSigSendType" SG_ 730 ADAS_Seg_EffSpdLmtTyp 2;
BA_ "Match" SG_ 730 ADAS_Seg_EffSpdLmtTyp "ADAS_Seg_EffSpdLmtTyp";
BA_ "Origin" SG_ 730 ADAS_Seg_EffSpdLmtTyp "fuel,ev";
BA_ "GenSigSendType" SG_ 730 ADAS_Seg_DivideRoad 2;
BA_ "Match" SG_ 730 ADAS_Seg_DivideRoad "ADAS_Seg_DivideRoad";
BA_ "Origin" SG_ 730 ADAS_Seg_DivideRoad "fuel,ev";
BA_ "GenSigSendType" SG_ 730 ADAS_Seg_NumOfLaneOppDir 2;
BA_ "Match" SG_ 730 ADAS_Seg_NumOfLaneOppDir "ADAS_Seg_NumOfLaneOppDir";
BA_ "Origin" SG_ 730 ADAS_Seg_NumOfLaneOppDir "fuel,ev";
BA_ "GenSigSendType" SG_ 730 ADAS_Seg_NumOfLaneDrvDir 2;
BA_ "Match" SG_ 730 ADAS_Seg_NumOfLaneDrvDir "ADAS_Seg_NumOfLaneDrvDir";
BA_ "Origin" SG_ 730 ADAS_Seg_NumOfLaneDrvDir "fuel,ev";
VAL_ 762 HCU_TotalScore_P0 0 "Valid value" 5 "Valid value" 6 "Reserved" 7 "Reserved";
VAL_ 762 HCU_GearChngPorNTXT 0 "Not indicate" 1 "Indicate";
VAL_ 762 HCU_SOCLow_Indcn 0 "Not active" 1 "Active";
VAL_ 762 HCU_RemoveChrgLine_Indcn 0 "Not active" 1 "Active";
VAL_ 762 HCU_Shift_P_Indcn 0 "Not active" 1 "Active";
VAL_ 762 HCU_ConnectChrgLine_Indcn 0 "Not active" 1 "Active";
VAL_ 762 HCU_EgyRecFB 0 "Standard" 1 "Enhanced" 2 "Low" 3 "Not Available";
VAL_ 762 HCU_OilTankCoverSts 0 "Closed" 1 "Open";
VAL_ 762 HCU_InhbChrgInfo 0 "No warning" 1 "When vehicle is refueling inhibit charge";
VAL_ 762 ImdtlyChrgSts 0 "Not active" 1 "Active";
VAL_ 762 HCU_EnerSavePowerMod 0 "No action" 1 "Close blower" 2 "Close seat heat" 3 "Close both blower and seat heat";
VAL_ 762 HCU_RefuReq 0 "No request" 1 "Refueling request" 2 "When vehicle is ready inhibit refuel" 3 "When engine is run inhibit refuel" 4 "When charger is connected inhibit refuel" 5 "Reserved" 7 "Reserved";
VAL_ 762 HCU_OPDFail 0 "Normal (Default)" 1 "OPD function not available due to temporary hybrid system limitations" 2 "OPD function not available due to Snow mode" 3 "Reserved";
VAL_ 762 OPDParkWarnReq 0 "No Request" 1 "Request";
VAL_ 762 HCU_ACStsReq 0 "Disable" 1 "Derating" 2 "Normal" 3 "Invalid";
VAL_ 584 HCU_12VSysErr_1 0 "Not indicate" 1 "Indicate";
VAL_ 584 HCU_12VSysErr_2 0 "Not indicate" 1 "Indicate";
VAL_ 584 HCU_HybSysErr_1 0 "Not indicate" 1 "Indicate";
VAL_ 584 HCU_HybSysErr_2 0 "Not indicate" 1 "Indicate";
VAL_ 584 HCU_HybSysErr_5 0 "Not indicate" 1 "Indicate";
VAL_ 584 HCU_HybSysErr_6 0 "Not indicate" 1 "Indicate";
VAL_ 584 HCU_HybSysErr_7 0 "Not indicate" 1 "Indicate";
VAL_ 584 HCU_12VSysErrLmpSts 0 "OFF" 1 "ON";
VAL_ 584 HCU_HybSysErrLmpSts 0 "OFF" 1 "Yellow Light ON" 2 "Red Light ON" 3 "Reserved";
VAL_ 584 HCU_PowerRedWarnLmpCmd 0 "Lamp off" 1 "Lamp on";
VAL_ 584 HCU_EnrgFlowInd 0 "Mode 0 Vehicle standstill" 1 "Engine running and BSG is a conventional generator" 2 "Boost" 3 "Energy Recovery" 4 "E-Creep" 5 "Pure engine drive" 6 "BSG generate electricity when engine idling" 7 "Engine idling and the BSG doesnÃ¢Â€Â™t generate electricity" 8 "Reserved" 31 "Reserved";
VAL_ 584 HCU_HybSysErr_3 0 "Not indicate" 1 "Indicate";
VAL_ 584 HCU_RdyLmpSts 0 "OFF" 1 "ON";
VAL_ 584 CheckSum_HCU_PT7 0 "Valid values" 255 "Valid values";
VAL_ 584 HCU_HybSysErr_4 0 "Not indicate" 1 "Indicate";
VAL_ 584 HCU_EnrgFlowInd_P2 0 "Mode 1 Vehicle standstill(P2&P2+P4)" 1 "Mode 2 engine drive , P2M generate electricity and P4M generates electricity(P2+P4)" 2 "Mode 3 engine drive, P2M generate electricity and P4M drive the vehicle(P2+P4)" 3 "Mode 4 engine drive and P2M generate electricity(P2&P2+P4)" 4 "Mode 5 engine drive, P2M don't generate electricity and P4M generate electricity(P2+P4)" 5 "Mode 6 P2M with engine and P4M drive the vehicle at the same time(P2+P4)" 6 "Mode 7 P2M supply boost for engine (P2&P2+P4)" 7 "Mode 8 engine and P4M drive the vehicle at the same time(P2+P4)" 8 "Mode 9 engine drives the vehicle only (P2&P2+P4)" 9 "Mode 10 engine drives P2M to generate electricity,P4M drives the vehicle(P2MÃ£Â€Âbattery supply power)(P2+P4)" 10 "Mode 11 P2M generate electricity when engine idling(P2&P2+P4)" 11 "Mode 12 engine idling and the P2M doesnÃ¢Â€Â™t generate electricity(P2&P2+P4)" 12 "Mode 13 brake recuperation of the front wheels(P2&P2+P4)" 13 "Mode 14 brake recuperation of the rear wheels(P2+P4)" 14 "Mode 15 P2M and P4M drive the vehicle at the same time(P2+P4)" 15 "Mode 16 P4M drive the vehicle,only(P2&P2+P4)  P2M drive the vehicle,only(P2)" 16 "Mode 17 plug-in-charging(P2&P2+P4)" 17 "Mode 18 Charging heating(P2&P2+P4)" 18 "Mode 19 Charging while heating (P2&P2+P4)" 19 "Mode 20 plug-inDC-charging(P2&P2+P4)" 20 "Mode21 engine drive and P2M generate electricity(AWD)(P2&P2+P4)" 21 "Mode22 engine drives the vehicle only (AWD)(P2&P2+P4)" 22 "Mode23 P2M supply boost for engine (AWD)(P2&P2+P4)" 23 "Mode24 brake recuperation of four wheels(AWD)(P2&P2+P4)" 24 "Mode25 V2L discharging(engine stop)" 25 "Mode26 V2L discharging(engine start)" 26 "Reserved" 31 "Reserved";
VAL_ 584 HCU_12VSysErr_3 0 "Not indicate" 1 "Indicate";
VAL_ 584 HCU_OPDLmpSts 0 "Off" 1 "On";
VAL_ 584 HCU_OPDSts 0 "Not active" 1 "Active" 2 "Abnormal quit" 3 "Cannot active" 4 "Have no OPD function" 5 "Reserved" 7 "Reserved";
VAL_ 584 HCU_ModSwtFail 0 "Default" 1 "EV not available due to low battery charge" 2 "EV not available due to temporary hybrid system limitations" 3 "SAVE not available due to temporary hybrid system limitations" 4 "AWD not available due to temporary hybrid system limitations" 5 "SPORT not available due to temporary hybrid system limitations" 6 "Manual gear change ,drive mode goes SPORT" 7 "Manual gear change,only SPORT available" 8 "Forced EV mode,battery power low,performance maylimited" 9 "Snow not available due to temporary hybrid system limitations" 10 "Muddy not available due to temporary hybrid system limitations" 11 "Sand not available due to temporary hybrid system limitations" 12 "SPORT Plus Mode not available due to temporary hybrid system limitations" 13 "ECO mode not available due to temporary hybrid system limitations" 14 "EV not available due to engine needs to start" 15 "Reserved";
VAL_ 584 RollingCounter_HCU_PT7 0 "Valid value" 14 "Valid value" 15 "Invalid value";
VAL_ 805 HUD_SwtSts 0 "OFF" 1 "ON";
VAL_ 805 HUD_BrightnessLvl 0 "Level 1" 1 "Level 2" 2 "Level 3" 3 "Level 4" 4 "Level 5" 5 "Level 6" 6 "Level 7" 7 "Level 8" 8 "Level 9" 9 "Reserved" 15 "Reserved";
VAL_ 805 HUD_HeightLvl 0 "Level 1" 1 "Level 2" 2 "Level 3" 3 "Level 4" 4 "Level 5" 5 "Level 6" 6 "Level 7" 7 "Level 8" 8 "Level 9" 9 "Level 10" 10 "Level 11" 11 "Level 12" 12 "Level 13" 13 "Level 14" 14 "Level 15" 15 "Level 16" 16 "Level 17" 17 "Level 18" 18 "Level 19" 19 "Level 20" 20 "Level 21" 21 "Reserved" 31 "Reserved";
VAL_ 805 HUD_UIMod 0 "Normal Mode" 1 "Dot Matrix Mode";
VAL_ 805 HUD_UIModVld 0 "Invalid" 1 "Valid";
VAL_ 805 HUD_Manufactor 0 "ADAYO" 1 "Reserved" 6 "Reserved" 7 "Not configured";
VAL_ 805 HUD_ReslType 0 "LVDS1" 1 "LVDS2" 2 "LVDS3" 3 "LVDS4" 4 "Reserved" 6 "Reserved" 7 "Not configured";
VAL_ 707 SSSSet_HUT 0 "OFF" 1 "ON";
VAL_ 707 IFC_SnvtySet 0 "Normal" 1 "High sensitivity" 2 "Low sensitivity" 3 "Reserved";
VAL_ 707 DOWSwtReq 0 "OFF" 1 "ON";
VAL_ 707 AEB_PedSwtReq 0 "OFF" 1 "ON";
VAL_ 707 ALCMLightLvlSet 0 "Reserved" 1 "10" 2 "20" 3 "30" 4 "40" 5 "50" 6 "60" 7 "70" 8 "80" 9 "90" 10 "100" 11 "Reserved" 15 "Reserved";
VAL_ 707 FlashLmpSwtReq 0 "OFF" 1 "ON";
VAL_ 707 LCASwtReq 0 "OFF" 1 "ON";
VAL_ 707 RCTASwtReq 0 "OFF" 1 "ON";
VAL_ 707 RCTABrkSwtReq 0 "OFF" 1 "ON";
VAL_ 707 RCWSwtReq 0 "OFF" 1 "ON";
VAL_ 707 FCW_SnvtySet 0 "Normal" 1 "High sensitivity" 2 "Low sensitivity" 3 "Reserved";
VAL_ 707 AEB_VehSwtReq 0 "OFF" 1 "ON";
VAL_ 707 LKASwtReq 0 "OFF" 1 "ON";
VAL_ 707 LCKSwtReq 0 "OFF" 1 "ON";
VAL_ 707 ELKSwtReq 0 "OFF" 1 "ON";
VAL_ 707 ESS_PedSwtReq 0 "OFF" 1 "ON";
VAL_ 707 ESS_VehSwtReq 0 "OFF" 1 "ON";
VAL_ 707 LDWSwtReq 0 "OFF" 1 "ON";
VAL_ 707 TSRSwtReq 0 "OFF" 1 "ON";
VAL_ 707 TSRWarnSwtReq 0 "OFF" 1 "ON";
VAL_ 707 ICA_HandsOffSwtReq 0 "OFF" 1 "ON";
VAL_ 707 ISLSwtReq 0 "OFF" 1 "ON";
VAL_ 707 TSR_SnvtySet 0 "valid" 30 "valid" 31 "Invalid";
VAL_ 707 HFASwtSts 0 "OFF" 1 "ON";
VAL_ 707 EPSSteerModSwtReq 0 "Comfort Mode" 1 "SportÃ‚Â mode" 2 "Handiness Mode" 3 "NO Hut Control";
VAL_ 707 DSTSwtReq 0 "OFF" 1 "ON";
VAL_ 707 LSSWarnFormSwtReq 0 "Voice" 1 "Haptic" 2 "Voice+Haptic" 3 "Reserved";
VAL_ 707 HUT_ESPFuncOffSwtSts 0 "Not Pressed" 1 "Pressed";
VAL_ 707 DrivingModReq_HUT 0 "StandardNormal Mode" 1 "Snow_Nex" 2 "Off Road" 3 "Economic" 4 "Sport" 5 "Reserved" 8 "Reserved" 9 "Auto" 10 "4L" 11 "Mud" 12 "Reserved" 13 "Sand" 14 "Reserved" 15 "Invalid Value";
VAL_ 707 OilLvlDispReq 0 "No request" 1 "Measurement request";
VAL_ 707 DrvgModeMemReq 0 "OFF" 1 "ON";
VAL_ 707 IntelligentEvaSwtReq 0 "OFF" 1 "ON";
VAL_ 707 LSSSwtReq 0 "OFF" 1 "ON";
VAL_ 707 HUTRadioFrq 0 "Radio frequency value" 4094 "Radio frequency value" 4095 "Invalid value";
VAL_ 707 MediaPlaySrc 0 "unknown" 1 "USB Audio" 2 "USB Video" 3 "BT Audio" 4 "iPod" 5 "AM" 6 "FM" 7 "Applink" 8 "QQ Music" 9 "Kaola FM" 10 "Online News" 11 "TOD" 12 "Reversed" 15 "Reversed";
VAL_ 707 USB_AudioSts 0 "Invalid" 1 "Play" 2 "Pause" 3 "Reserved";
VAL_ 707 USB_VideoSts 0 "Invalid" 1 "Play" 2 "Pause" 3 "Reserved";
VAL_ 707 BT_AudioSts 0 "Invalid" 1 "Play" 2 "Pause" 3 "Reserved";
VAL_ 707 IPod_Sts 0 "Invalid" 1 "Play" 2 "Pause" 3 "Reserved";
VAL_ 707 AM_Sts 0 "Invalid" 1 "Play" 2 "Pause" 3 "Reserved";
VAL_ 707 FM_Sts 0 "Invalid" 1 "Play" 2 "Pause" 3 "Reserved";
VAL_ 707 APPLink_Sts 0 "Invalid" 1 "Play" 2 "Pause" 3 "Reserved";
VAL_ 707 QQMusic_Sts 0 "Invalid" 1 "Play" 2 "Pause" 3 "Reserved";
VAL_ 707 KaolaFM_Sts 0 "Invalid" 1 "Play" 2 "Pause" 3 "Reserved";
VAL_ 707 OnlineNews_Sts 0 "Invalid" 1 "Play" 2 "Pause" 3 "Reserved";
VAL_ 707 HUT_WadeModeSet 0 "OFF" 1 "ON";
VAL_ 707 ExpertModReq_HUT_ECM 0 "Standard" 1 "Sport" 2 "Economic" 3 "4L" 4 "Reserved" 7 "Reserved";
VAL_ 707 ExpertModReq_HUT_TCU 0 "Standard" 1 "Sport" 2 "Economic" 3 "4L" 4 "Reserved" 7 "Reserved";
VAL_ 707 ExpertModReq_HUT_TOD 0 "2H" 1 "4H" 2 "4A" 3 "4L";
VAL_ 707 ChairMemPosnSet 0 "No Command" 1 "Binding Account" 2 "Bring Up The Account" 3 "Unbinding Account";
VAL_ 707 ChairMemPosnSetResult 0 "Factory Default" 1 "User ID1" 2 "User ID2" 3 "User ID3" 4 "User ID4" 5 "User ID5" 6 "User ID6" 7 "User ID7" 8 "User ID8" 9 "User ID9" 10 "User ID10" 11 "Reserved" 15 "Reserved";
VAL_ 707 TABSwtReq_HUT 0 "Not activate" 1 "Activate";
VAL_ 707 NavVehToTrafEyeDist 0 "Valid value" 1023 "Valid value";
VAL_ 707 NavRoadType 0 "Unknown" 1 "Expressway" 2 "City expressway" 3 "National rode" 4 "Provincial rode" 5 "County rode" 6 "City or Village rode" 7 "ramp" 8 "Tunnel" 9 "Side rode" 10 "Channel" 11 "Reserved" 15 "Reserved";
VAL_ 707 NavSpdLimType 0 "Unknown" 1 "Traffic sign" 2 "Electronic eye" 3 "Rode Default";
VAL_ 707 NavSpdLimValue 0 "No Display" 1 "SPL 5" 2 "SPL 10" 3 "SPL 15" 4 "SPL 20" 5 "SPL 25" 6 "SPL 30" 7 "SPL 35" 8 "SPL 40" 9 "SPL 45" 10 "SPL 50" 11 "SPL 55" 12 "SPL 60" 13 "SPL 65" 14 "SPL 70" 15 "SPL 75" 16 "SPL 80" 17 "SPL 85" 18 "SPL 90" 19 "SPL 95" 20 "SPL 100" 21 "SPL 105" 22 "SPL 110" 23 "SPL 115" 24 "SPL 120" 25 "SPL 125" 26 "SPL 130" 27 "SPL 135" 28 "SPL 140" 29 "SPL 145" 30 "SPL 150" 31 "Reserved" 62 "Reserved" 63 "Invalid";
VAL_ 707 NavSpdLimUnit_HUT 0 "Unknown" 1 "KMH" 2 "MPH" 3 "Reserved";
VAL_ 707 NavCtryType 0 "Reserved" 155 "Reserved" 156 "China" 157 "Reserved" 1023 "Reserved";
VAL_ 707 NavSpdLimSignSts 0 "Unknow" 1 "Exist SPL sign" 2 "Exist Traffic sign" 3 "Exist SPL and Traffic sign" 4 "None" 5 "Plural" 6 "Reserved" 7 "Reserved";
VAL_ 707 NavTSRTrafSign 0 "None" 1 "Snow" 2 "Fog" 3 "ThunderStorm" 4 "Rain" 5 "FWay" 6 "EFWay" 7 "Straight" 8 "FrontageLeft" 9 "TurnLeftRight" 10 "FrontageRight" 11 "Right" 12 "TurnRight" 13 "Left" 14 "TurnLeft" 15 "RelieveNoOvertake" 16 "NoOvertake" 17 "StopGiveWay" 18 "GiveWay" 19 "NoPass" 20 "NoEntry" 21 "NoCar" 22 "NoTruck" 23 "NoBus" 24 "NoTurnaround" 25 "NoStraightLeftTurn" 26 "NoStraightRightTurn" 27 "NoLeftRightTurn" 28 "NoLeftTurn" 29 "NoRightTurn" 30 "NoStraight" 31 "WarnKids" 32 "WarnPed" 33 "WarnBike" 34 "WarnWorks" 35 "WarnWildanimal" 36 "WarnCattle" 37 "ACCidentProneSection" 38 "Town" 39 "Slow" 40 "SharpTurnR" 41 "SharpTurnL" 42 "ReverseCurveL" 43 "ReverseCurveR" 44 "ContinuousBend" 45 "Crossroads" 46 "ConfluenceR" 47 "ConfluenceL" 48 "Reserved" 254 "Reserved" 255 "Invalid";
VAL_ 707 AESSwtReq 0 "OFF" 1 "ON";
VAL_ 707 HWA_SwtReq 0 "OFF" 1 "ON";
VAL_ 707 HWA_SnvtySet 0 "Normal" 1 "High sensitivity" 2 "Low sensitivity" 3 "Reserved";
VAL_ 707 FCTASwtReq 0 "OFF" 1 "ON";
VAL_ 707 FCTABrkSwtReq 0 "OFF" 1 "ON";
VAL_ 707 AEB_JASwtReq 0 "OFF" 1 "ON";
VAL_ 707 HWA_WarnFormSwtReq 0 "No haptic" 1 "Haptic";
VAL_ 707 SteerCorrnReq 0 "OFF" 1 "ON";
VAL_ 707 ALC_SwtReq 0 "OFF" 1 "ON";
VAL_ 707 ExpertModSwtReq_HUT 0 "Not active" 1 "Active";
VAL_ 707 ExpertModReq_HUT_ESP 0 "No request" 1 "Pata One" 2 "Pata two" 3 "Reserved";
VAL_ 707 ADAS_Posn_MsgTye 0 "System Specific" 1 "Position" 2 "Segment" 3 "Stub" 4 "Profile Short" 5 "Profile Long" 6 "Meta-data" 7 "Reserved";
VAL_ 707 ADAS_Posn_Offset 0 "Valid value" 8190 "Valid value" 8191 "Invalid data";
VAL_ 707 ADAS_Posn_CycCnt 0 "Valid value" 3 "Valid value";
VAL_ 707 ADAS_Posn_Pathldx 0 "Valid value" 63 "Valid value";
VAL_ 707 ADAS_Posn_Idx 0 "Valid value" 3 "Valid value";
VAL_ 707 ADAS_Posn_PosProbb 0 "Unknown" 1 "Valid data" 30 "Valid data" 31 "Invalid";
VAL_ 707 ADAS_Posn_Age 0 "0~2545ms" 509 "0~2545ms" 510 ">2545ms" 511 "Invalid data";
VAL_ 707 ADAS_Posn_PosConfdc 0 "Valid value" 6 "Valid value" 7 "Invalid value";
VAL_ 707 ADAS_Posn_CurLane 0 "Unknown" 1 "Emergency lane" 2 "Single-lane road" 3 "Left-most lane" 4 "Right-most lane" 5 "One of middle lanes on road with three or more lanes" 6 "Reserved" 7 "Invalid data";
VAL_ 707 ADAS_Posn_Spd 0 "Ã¢Â‰Â¤ -12.8 ms" 1 "(-12.6)~(-0.2)ms" 63 "(-12.6)~(-0.2)ms" 64 "Standing still" 65 "(+0.2)~(+89.0)ms" 509 "(+0.2)~(+89.0)ms" 510 "Ã¢Â‰Â¥ +89.2 ms" 511 "Invalid data";
VAL_ 707 ADAS_Posn_Rehead 0 "In path direction" 1 "1.417 degrees right" 2 "Right from path direction" 125 "Right from path direction" 126 "178.583 degrees right" 127 "Opposite direction" 128 "178.583 degrees left (181.417 degrees right)" 129 "Left from path direction" 252 "Left from path direction" 253 "1.417 degrees left (358.583 degrees right)" 254 "Unknown" 255 "Invalid";
VAL_ 707 EngStrtDischrgn 0 "Enable" 1 "Disable";
VAL_ 707 HUT_HybModReq 0 "No request" 1 "HEV" 2 "EV" 3 "SAVE";
VAL_ 707 HUT_HybFctnReq 0 "No request" 1 "OFF" 2 "SAVE" 3 "SPORT+";
VAL_ 707 HUT_DrvModReq 0 "Normal Mode started" 1 "EV Mode started" 2 "Save Mode started" 3 "SPORT Mode started" 4 "AWD Normal Mode started" 5 "Snow Mode started" 6 "Muddy Mode started" 7 "Sand Mode started" 8 "ECO Mode started" 9 "SPORT Plus Mode started" 10 "NO request" 11 "AUTO Mode started" 12 "Individual" 13 "Reserved" 15 "Reserved";
VAL_ 515 HUT_OD_Obj0_ID 0 "Valid values" 9 "Valid values" 10 "Invalid values" 15 "Invalid values";
VAL_ 515 HUT_OD_Obj0_type 0 "No target" 1 "Pedestrian or Biker" 2 "Vehicle" 3 "Ground Locker or Barrier" 4 "Unknown type" 5 "Invalid values" 7 "Invalid values";
VAL_ 515 HUT_OD_Obj0_Confidence 0 "0-1" 10 "0-1" 11 "Invalid values" 15 "Invalid values";
VAL_ 515 HUT_OD_Obj0_width 0 "Valid values" 126 "Valid values" 127 "Invalid values";
VAL_ 515 HUT_OD_Obj0_Ground_Pos_X 0 "Valid values" 4000 "Valid values" 4001 "Reserved" 4094 "Reserved" 4095 "Invalid values";
VAL_ 515 HUT_OD_Obj0_Ground_Pos_Y 0 "Valid values" 4000 "Valid values" 4001 "Reserved" 4094 "Reserved" 4095 "Invalid values";
VAL_ 515 HTU_OD_Obj1_ID 0 "Valid values" 9 "Valid values" 10 "Invalid values" 15 "Invalid values";
VAL_ 515 HUT_OD_Obj1_type 0 "No target" 1 "Pedestrian or Biker" 2 "Vehicle" 3 "Ground Locker or Barrier" 4 "Unknown type" 5 "Invalid values" 7 "Invalid values";
VAL_ 515 HUT_OD_Obj1_Confidence 0 "0-1" 10 "0-1" 11 "Invalid values" 15 "Invalid values";
VAL_ 515 HUT_OD_Obj1_width 0 "Valid values" 126 "Valid values" 127 "Invalid values";
VAL_ 515 HUT_OD_Obj1_Ground_Pos_X 0 "Valid values" 4000 "Valid values" 4001 "Reserved" 4094 "Reserved" 4095 "Invalid values";
VAL_ 515 HUT_OD_Obj1_Ground_Pos_Y 0 "Valid values" 4000 "Valid values" 4001 "Reserved" 4094 "Reserved" 4095 "Invalid values";
VAL_ 515 HUT_OD_Obj2_ID 0 "Valid values" 9 "Valid values" 10 "Invalid values" 15 "Invalid values";
VAL_ 515 HUT_OD_Obj2_type 0 "No target" 1 "Pedestrian or Biker" 2 "Vehicle" 3 "Ground Locker or Barrier" 4 "Unknown type" 5 "Invalid values" 7 "Invalid values";
VAL_ 515 HUT_OD_Obj2_Confidence 0 "0-1" 10 "0-1" 11 "Invalid values" 15 "Invalid values";
VAL_ 515 HUT_OD_Obj2_width 0 "Valid values" 126 "Valid values" 127 "Invalid values";
VAL_ 515 HUT_OD_Obj2_Ground_Pos_X 0 "Valid values" 4000 "Valid values" 4001 "Reserved" 4094 "Reserved" 4095 "Invalid values";
VAL_ 515 HUT_OD_Obj2_Ground_Pos_Y 0 "Valid values" 4000 "Valid values" 4001 "Reserved" 4094 "Reserved" 4095 "Invalid values";
VAL_ 515 HUT_OD_Obj3_ID 0 "Valid values" 9 "Valid values" 10 "Invalid values" 15 "Invalid values";
VAL_ 515 HUT_OD_Obj3_type 0 "No target" 1 "Pedestrian or Biker" 2 "Vehicle" 3 "Ground Locker or Barrier" 4 "Unknown type" 5 "Invalid values" 7 "Invalid values";
VAL_ 515 HUT_OD_Obj3_Confidence 0 "0-1" 10 "0-1" 11 "Invalid values" 15 "Invalid values";
VAL_ 515 HUT_OD_Obj3_width 0 "Valid values" 126 "Valid values" 127 "Invalid values";
VAL_ 515 HUT_OD_Obj3_Ground_Pos_X 0 "Valid values" 4000 "Valid values" 4001 "Reserved" 4094 "Reserved" 4095 "Invalid values";
VAL_ 515 HUT_OD_Obj3_Ground_Pos_Y 0 "Valid values" 4000 "Valid values" 4001 "Reserved" 4094 "Reserved" 4095 "Invalid values";
VAL_ 515 HUT_OD_Obj4_ID 0 "Valid values" 9 "Valid values" 10 "Invalid values" 15 "Invalid values";
VAL_ 515 HUT_OD_Obj4_type 0 "No target" 1 "Pedestrian or Biker" 2 "Vehicle" 3 "Ground Locker or Barrier" 4 "Unknown type" 5 "Invalid values" 7 "Invalid values";
VAL_ 515 HUT_OD_Obj4_Confidence 0 "0-1" 10 "0-1" 11 "Invalid values" 15 "Invalid values";
VAL_ 515 HUT_OD_Obj4_width 0 "Valid values" 126 "Valid values" 127 "Invalid values";
VAL_ 515 HUT_OD_Obj4_Ground_Pos_X 0 "Valid values" 4000 "Valid values" 4001 "Reserved" 4094 "Reserved" 4095 "Invalid values";
VAL_ 515 HUT_OD_Obj4_Ground_Pos_Y 0 "Valid values" 4000 "Valid values" 4001 "Reserved" 4094 "Reserved" 4095 "Invalid values";
VAL_ 515 HUT_OD_Obj5_ID 0 "Valid values" 9 "Valid values" 10 "Invalid values" 15 "Invalid values";
VAL_ 515 HUT_OD_Obj5_type 0 "No target" 1 "Pedestrian or Biker" 2 "Vehicle" 3 "Ground Locker or Barrier" 4 "Unknown type" 5 "Invalid values" 7 "Invalid values";
VAL_ 515 HUT_OD_Obj5_Confidence 0 "0-1" 10 "0-1" 11 "Invalid values" 15 "Invalid values";
VAL_ 515 HUT_OD_Obj5_width 0 "Valid values" 126 "Valid values" 127 "Invalid values";
VAL_ 515 HUT_OD_Obj5_Ground_Pos_X 0 "Valid values" 4000 "Valid values" 4001 "Reserved" 4094 "Reserved" 4095 "Invalid values";
VAL_ 515 HUT_OD_Obj5_Ground_Pos_Y 0 "Valid values" 4000 "Valid values" 4001 "Reserved" 4094 "Reserved" 4095 "Invalid values";
VAL_ 515 HUT_OD_Obj6_ID 0 "Valid values" 9 "Valid values" 10 "Invalid values" 15 "Invalid values";
VAL_ 515 HUT_OD_Obj6_type 0 "No target" 1 "Pedestrian or Biker" 2 "Vehicle" 3 "Ground Locker or Barrier" 4 "Unknown type" 5 "Invalid values" 7 "Invalid values";
VAL_ 515 HUT_OD_Obj6_Confidence 0 "0-1" 10 "0-1" 11 "Invalid values" 15 "Invalid values";
VAL_ 515 HUT_OD_Obj6_width 0 "Valid values" 126 "Valid values" 127 "Invalid values";
VAL_ 515 HUT_OD_Obj6_Ground_Pos_X 0 "Valid values" 4000 "Valid values" 4001 "Reserved" 4094 "Reserved" 4095 "Invalid values";
VAL_ 515 HUT_OD_Obj6_Ground_Pos_Y 0 "Valid values" 4000 "Valid values" 4001 "Reserved" 4094 "Reserved" 4095 "Invalid values";
VAL_ 579 HUT_OD_Obj7_ID 0 "Valid values" 9 "Valid values" 10 "Invalid values" 15 "Invalid values";
VAL_ 579 HUT_OD_Obj7_type 0 "No target" 1 "Pedestrian or Biker" 2 "Vehicle" 3 "Ground Locker or Barrier" 4 "Unknown type" 5 "Invalid values" 7 "Invalid values";
VAL_ 579 HUT_OD_Obj7_Confidence 0 "0-1" 10 "0-1" 11 "Invalid values" 15 "Invalid values";
VAL_ 579 HUT_OD_Obj7_width 0 "Valid values" 126 "Valid values" 127 "Invalid values";
VAL_ 579 HUT_OD_Obj7_Ground_Pos_X 0 "Valid values" 4000 "Valid values" 4001 "Reserved" 4094 "Reserved" 4095 "Invalid values";
VAL_ 579 HUT_OD_Obj7_Ground_Pos_Y 0 "Valid values" 4000 "Valid values" 4001 "Reserved" 4094 "Reserved" 4095 "Invalid values";
VAL_ 579 AutoSpdSetSwt 0 "OFF" 1 "ON";
VAL_ 579 LaneChngCfmSwt 0 "OFF" 1 "ON";
VAL_ 579 VoiceBrdcSwt 0 "OFF" 1 "ON";
VAL_ 579 UsrManSts 0 "OFF" 1 "Page_1" 2 "Page_2" 3 "Page_3" 4 "Page_4" 5 "Page_5" 6 "Page_6" 7 "Page_7" 8 "Page_8" 9 "Page_9";
VAL_ 579 HUT_OD_WorkSts 0 "OFF" 1 "FOD Active" 2 "ROD Active" 3 "Reserved";
VAL_ 579 HUT_OD_Obj_Timestamp 0 "Valid values" 65535 "Valid values";
VAL_ 579 HUT_FSD1_distance 0 "Valid values" 60 "Valid values" 61 "Invalid values" 63 "Invalid values";
VAL_ 579 HUT_FSD2_distance 0 "Valid values" 60 "Valid values" 61 "Invalid values" 63 "Invalid values";
VAL_ 579 HUT_FSD3_distance 0 "Valid values" 60 "Valid values" 61 "Invalid values" 63 "Invalid values";
VAL_ 579 HUT_FSD4_distance 0 "Valid values" 60 "Valid values" 61 "Invalid values" 63 "Invalid values";
VAL_ 579 HUT_FSD5_distance 0 "Valid values" 60 "Valid values" 61 "Invalid values" 63 "Invalid values";
VAL_ 579 HUT_FSD6_distance 0 "Valid values" 60 "Valid values" 61 "Invalid values" 63 "Invalid values";
VAL_ 579 HUT_FSD7_distance 0 "Valid values" 60 "Valid values" 61 "Invalid values" 63 "Invalid values";
VAL_ 579 HUT_FSD8_distance 0 "Valid values" 60 "Valid values" 61 "Invalid values" 63 "Invalid values";
VAL_ 579 HUT_FSD9_distance 0 "Valid values" 60 "Valid values" 61 "Invalid values" 63 "Invalid values";
VAL_ 579 HUT_FSD10_distance 0 "Valid values" 60 "Valid values" 61 "Invalid values" 63 "Invalid values";
VAL_ 579 HUT_FSD11_distance 0 "Valid values" 60 "Valid values" 61 "Invalid values" 63 "Invalid values";
VAL_ 579 HUT_FSD12_distance 0 "Valid values" 60 "Valid values" 61 "Invalid values" 63 "Invalid values";
VAL_ 579 HUT_FSD13_distance 0 "Valid values" 60 "Valid values" 61 "Invalid values" 63 "Invalid values";
VAL_ 579 HUT_FSD14_distance 0 "Valid values" 60 "Valid values" 61 "Invalid values" 63 "Invalid values";
VAL_ 579 HUT_FSD15_distance 0 "Valid values" 60 "Valid values" 61 "Invalid values" 63 "Invalid values";
VAL_ 579 HUT_FSD16_distance 0 "Valid values" 60 "Valid values" 61 "Invalid values" 63 "Invalid values";
VAL_ 579 HUT_FSD17_distance 0 "Valid values" 60 "Valid values" 61 "Invalid values" 63 "Invalid values";
VAL_ 579 HUT_FSD18_distance 0 "Valid values" 60 "Valid values" 61 "Invalid values" 63 "Invalid values";
VAL_ 579 NOH_Swt_Req 0 "OFF" 1 "ON";
VAL_ 579 NOH_Act_Req 0 "deactivate" 1 "activate";
VAL_ 474 SlotNum_VR 0 "Valid values" 6 "Invalid" 15 "Invalid";
VAL_ 474 UserDefinedParkCmd 0 "No Request" 1 "Request";
VAL_ 474 HUT_HAVP_Set_Starting 0 "No Request" 1 "Request";
VAL_ 474 HUT_HAVP_Set_Path_Ending 0 "No request" 1 "Request";
VAL_ 474 HUT_HAVP_APA_Permit 0 "Idle" 1 "NO" 2 "YES" 3 "Reserved";
VAL_ 474 UserDefPrkMenuSelCmd 0 "No Request" 1 "Parallel Slot Selected" 2 "Vertical Slot Selected" 3 "Reserved" 4 "Reserved" 5 "Clock wise Selected" 6 "Anticlock wise Selected" 7 "Reserved";
VAL_ 474 HUT_HAVP_SelfParLot_Ending 0 "No Request" 1 "Request";
VAL_ 474 HUT_HAVP_Return_Btn 0 "No Request" 1 "Request";
VAL_ 871 DomeLmpDlyTimSet 0 "3seconds" 1 "10seconds" 2 "20seconds" 3 "30seconds" 4 "Reserved" 7 "Reserved";
VAL_ 871 FolwMeHomeDlyTimSet 0 "0seconds" 1 "30seconds" 2 "60seconds" 3 "90seconds" 4 "Reserved" 7 "Reserved";
VAL_ 871 TranPMode_Req 0 "Transport Mode OFF" 1 "Transport Mode ON";
VAL_ 871 RearviewFoldModSet 0 "Automatical" 1 "Manual";
VAL_ 871 BattSaveDelayTimeSet 0 "2minutes" 1 "5minutes" 2 "8minutes" 3 "Reserved";
VAL_ 871 ACDualReq_TC 0 "No action" 1 "Pressed" 2 "Reserved" 3 "Reserved";
VAL_ 871 ACAutoModReq_TC 0 "No action" 1 "Pressed" 2 "Reserved" 3 "Reserved";
VAL_ 871 ACAirInletReq_TC 0 "No action" 1 "Pressed" 2 "OneButtonCloseWindows" 3 "Reserved";
VAL_ 871 ACFrntHMIDis_TC 0 "No action" 1 "Pressed";
VAL_ 871 ACRearHMIDis_TC 0 "No action" 1 "Pressed";
VAL_ 871 ACAQSReq_TC 0 "No action" 1 "Pressed" 2 "Reserved" 3 "Reserved";
VAL_ 871 ACCmprReq_TC 0 "No action" 1 "Pressed" 2 "Reserved" 3 "Reserved";
VAL_ 871 ACFrntDefrstReq_TC 0 "No action" 1 "Pressed" 2 "Reserved" 3 "Reserved";
VAL_ 871 ACFrntBlwrSpdDecReq_TC 0 "No action" 1 "Pressed" 2 "Reserved" 3 "Reserved";
VAL_ 871 ACRearBlwrSpdDecReq_TC 0 "No action" 1 "Pressed";
VAL_ 871 ACRearBlwrSpdIncReq_TC 0 "No action" 1 "Pressed";
VAL_ 871 DrvDrowsnsDetnSet 0 "OFF" 1 "ON";
VAL_ 871 ACFrntBlwrSpdIncReq_TC 0 "No action" 1 "Pressed" 2 "Reserved" 3 "Reserved";
VAL_ 871 ACDrvAirDistribModReq_TC 0 "No action" 1 "Face" 2 "Face & Foot" 3 "Foot" 4 "Foot & Defrost" 5 "Reserved" 7 "Reserved";
VAL_ 871 ACDrvTempDecReq_TC 0 "No action" 1 "Pressed" 2 "Reserved" 3 "Reserved";
VAL_ 871 ChairMemPosnEna 0 "Disable" 1 "Enable";
VAL_ 871 ACDrvTempIncReq_TC 0 "No action" 1 "Pressed" 2 "Reserved" 3 "Reserved";
VAL_ 871 ACFrntPassTempDecReq_TC 0 "No action" 1 "Pressed" 2 "Reserved" 3 "Reserved";
VAL_ 871 ACFrntPassTempIncReq_TC 0 "No action" 1 "Pressed" 2 "Reserved" 3 "Reserved";
VAL_ 871 ACAIUReq_TC 0 "No action" 1 "Pressed";
VAL_ 871 ACOffReq_TC 0 "No action" 1 "Pressed" 2 "Reserved" 3 "Reserved";
VAL_ 871 ACBlwrsteplsSpdReq_TC 0 "No Command" 1 "Stepless Speed1_Low" 2 "Stepless Speed2" 3 "Stepless Speed3" 4 "Stepless Speed4" 5 "Stepless Speed5" 6 "Stepless Speed6" 7 "Stepless Speed7_High" 8 "Reserved" 15 "Reserved";
VAL_ 871 ACZoneReq_TC 0 "No action" 1 "Pressed";
VAL_ 68 ALCMStatSwt_OLE 0 "Off" 1 "On";
VAL_ 68 ALCMClrSet_OLE 0 "Colour set 0-63" 63 "Colour set 0-63";
VAL_ 68 ALCMDynModSet_OLE 0 "DynModOFF" 1 "DynMod1" 2 "DynMod2" 3 "DynMod3" 4 "DynMod4" 5 "DynMod5" 6 "DynMod6" 7 "DynMod7";
VAL_ 68 ALCMLightLvlSet_OLE 0 "Reserved" 1 "10" 2 "20" 3 "30" 4 "40" 5 "50" 6 "60" 7 "70" 8 "80" 9 "90" 10 "100" 11 "Reserved" 15 "Reserved";
VAL_ 68 ALCMRhmSwt_OLE 0 "Off" 1 "On";
VAL_ 68 ALCMBreSwt_OLE 0 "OFF" 1 "ON";
VAL_ 68 ALCMRdmSwt_OLE 0 "OFF" 1 "ON";
VAL_ 68 Rdm_SingleColorNr 0 "No command" 1 "Valid" 64 "Valid" 65 "Reserved" 127 "Reserved";
VAL_ 68 HUT_VMDRTmpMonFctnSet 0 "NO action" 1 "Disable" 2 "Enable" 3 "Reserved";
VAL_ 68 HUT_VMDRInitAlarmDlySet 0 "NO action" 1 "Disable" 2 "Enable" 3 "Reserved";
VAL_ 68 OTA_UpgrdModReq 0 "No_Action" 1 "Enter_the_Remote_upgrade_mode" 2 "Enter_the_Immediately_upgrade_mode" 3 "End_upgrade_mode_via_HUT" 4 "Powertrain_ON_upgrade_mode" 5 "Powertrain_OFF_upgrade_mode" 6 "Reserved" 7 "Reserved";
VAL_ 817 ACDualReq_VR 0 "No action" 1 "Close" 2 "Open" 3 "Reserved";
VAL_ 817 ACAQSReq_VR 0 "No action" 1 "Close" 2 "Open" 3 "Reserved";
VAL_ 817 ACRearDefrstReq_VR 0 "No action" 1 "Close" 2 "Open" 3 "Reserved";
VAL_ 817 ACPassTempReq_VR 0 "No action" 1 "Low" 2 "Valid value(phys = 0.5 * raw + 15.5)" 32 "Valid value(phys = 0.5 * raw + 15.5)" 33 "High" 34 "Reserved" 63 "Reserved";
VAL_ 817 ACAIUReq_VR 0 "No action" 1 "Close" 2 "Open" 3 "Reserved";
VAL_ 817 ALCMStatSwt 0 "Off" 1 "On";
VAL_ 817 ALCMDynSwt 0 "Off" 1 "On";
VAL_ 817 ALCMClrSet 0 "Colour set 0-63" 63 "Colour set 0-63";
VAL_ 817 ALCMRhmSwt 0 "Off" 1 "On";
VAL_ 817 IPVolSet 0 "Reserved" 9 "Reserved" 10 "IP volume step 10-20" 20 "IP volume step 10-20" 21 "Reserved" 62 "Reserved" 63 "Invalid Value";
VAL_ 817 PASSwtReq_VR 0 "No action" 1 "OFF" 2 "ON" 3 "Reserved";
VAL_ 817 HUT_BeanIDReq 0 "No action" 1 "Request" 2 "Clear Data" 3 "Reserved";
VAL_ 817 HUT_EgyRecvrySet 0 "Strong" 1 "Normal" 2 "Weak" 3 "No action";
VAL_ 943 WeatherCdn 0 "None Display" 1 "icon 100 SunnyClear" 2 "icon 101 Cloudy" 3 "icon 102 Few Clouds" 4 "icon 103 Partly Cloudy" 5 "icon 104 Overcast" 6 "icon 200 Windy" 7 "icon 201 Calm" 8 "icon 202 Light Breeze" 9 "icon 203 ModerateGentle Breeze" 10 "icon 204 Fresh Breeze" 11 "icon 205 Strong Breeze" 12 "icon 206 High Wind, Near Gale" 13 "icon 207 Gale" 14 "icon 208 Strong Gale" 15 "icon 209 Storm" 16 "icon 210 Violent Storm" 17 "icon 211 Hurricane" 18 "icon 212 Tornado" 19 "icon 213 Tropical Storm" 20 "icon 300 Shower Rain" 21 "icon 301 Heavy Shower Rain" 22 "icon 302 Thundershower" 23 "icon 303 Heavy Thunderstorm" 24 "icon 304 Thundershower with hail" 25 "icon 305 Light Rain" 26 "icon 306 Moderate Rain" 27 "icon 307 Heavy Rain" 28 "icon 308 Extreme Rain" 29 "icon 309 Drizzle Rain" 31 "icon 310 Storm" 32 "icon 311 Heavy Storm" 33 "icon 312 Severe Storm" 34 "icon 313 Freezing Rain" 35 "icon 314 Light to moderate rain" 36 "icon 315 Moderate to heavy rain" 37 "icon 316 Heavy rain to storm" 38 "icon 317 Storm to heavy storm" 39 "icon 318 Heavy to severe storm" 40 "icon 399 Rain" 41 "icon 400 Light Snow" 42 "icon 401 Moderate Snow" 43 "icon 402 Heavy Snow" 44 "icon 403 Snowstorm" 45 "icon 404 Sleet" 46 "icon 405 Rain And Snow" 47 "icon 406 Shower Snow" 48 "icon 407 Snow Flurry" 49 "icon 408 Light to moderate snow" 50 "icon 409 Moderate to heavy snow" 51 "icon 410 Heavy snow to snowstorm" 52 "icon 499 Snow" 53 "icon 500 Mist" 54 "icon 501 Foggy" 55 "icon 502 Haze" 56 "icon 503 Sand" 57 "icon 504 Dust" 58 "icon 507 Duststorm" 59 "icon 508 Sandstorm" 60 "icon 509 Dense fog" 61 "icon 510 Strong fog" 62 "icon 511 Moderate haze" 63 "icon 512 Heavy haze" 64 "icon 513 Severe haze" 65 "icon 514 Heavy fog" 66 "icon 515 Extra heavy fog" 67 "icon 900 Hot" 68 "icon 901 Cold" 69 "icon 999 Unknown" 70 "Reserved" 127 "Reserved";
VAL_ 943 PitchAng 0 "Valid Value" 90 "Valid Value" 91 "Reserved" 127 "Reserved";
VAL_ 943 PitchAngSign 0 "Uphill(Positive)" 1 "Downhil(Negative)";
VAL_ 796 AudioMuteSts 0 "Not used" 1 "not producing audio" 2 "producing audio" 3 "Reserved";
VAL_ 796 OrvmPosnEnaSts 0 "No command" 1 "Both side disable" 2 "Both side enable" 3 "Only driver enable" 4 "Only passager enable" 5 "Reserved" 7 "Reserved";
VAL_ 796 ORVMFoldSwt_HUT 0 "None" 1 "Fold" 2 "Unfold" 3 "Reserved";
VAL_ 796 ORVMLensAdjmt_HUT 0 "Mir_Swt_Idle" 1 "Mir_Swt_Drv_up" 2 "Mir_Swt_Drv_down" 3 "Mir_Swt_Drv_left" 4 "Mir_Swt_Drv_right" 5 "Mir_Swt_Pass_up" 6 "Mir_Swt_Pass_down" 7 "Mir_Swt_Pass_left" 8 "Mir_Swt_Pass_right" 9 "Reserved" 15 "Reserved";
VAL_ 796 DrvSeatAdjmt_HUT 0 "Seat_Swt_Idle" 1 "Seat_Swt_Slide_Fwd" 2 "Seat_Swt_Slide_Rwd" 3 "Seat_Swt_BckRst_Fwd" 4 "Seat_Swt_BckRst_Rwd" 5 "Seat_Swt_Height_F_up" 6 "Seat_Swt_Height_F_down" 7 "Seat_Swt_Height_R_up" 8 "Seat_Swt_Height_R_down" 9 "Reserved" 15 "Reserved";
VAL_ 796 DrivingModReq_VR 0 "Standard" 1 "Reserved" 2 "Reserved" 3 "ECO" 4 "Sport" 5 "Reserved" 8 "Reserved" 9 "AUTO" 10 "Reserved" 11 "Mud" 12 "Snow_TOD" 13 "Sand" 14 "Reserved" 15 "Initial Value";
VAL_ 796 DWD_WorkCmd 0 "OFF" 1 "ON";
VAL_ 796 DampgDrvModeReq 0 "Normal (Reserved)" 1 "Comfort(Default)" 2 "Sport" 3 "No HUT Control";
VAL_ 796 VSGSwtSet 0 "VSG OFF" 1 "VSG ON";
VAL_ 494 ACOperMod_TC 0 "No action" 1 "Standard Mode" 2 "Comfort Mode" 3 "Strong Mode";
VAL_ 494 ACOperMod_VR 0 "No action" 1 "Standard Mode" 2 "Comfort Mode" 3 "Strong Mode";
VAL_ 494 ACDrvSetTempSteplsReq_TC 0 "No action" 1 "Low" 2 "Valid value" 32 "Valid value" 33 "High" 34 "Reserved" 63 "Reserved";
VAL_ 494 ACPassSetTempSteplsReq_TC 0 "No action" 1 "Low" 2 "Valid value" 32 "Valid value" 33 "High" 34 "Reserved" 63 "Reserved";
VAL_ 494 SDWSwtSet 0 "No Request" 1 "Request";
VAL_ 494 APSSwtReq_VR 0 "No action" 1 "off" 2 "on" 3 "Reserved";
VAL_ 494 APSPrkgTypSeln 0 "No Select" 1 "Select parallel parking" 2 "Select vertical parking" 3 "Reserved";
VAL_ 494 SunShadeSwtReq_VR 0 "No action" 1 "Full closed" 2 "10%" 3 "20%" 4 "30%" 5 "40%" 6 "50%" 7 "60%" 8 "70%" 9 "80%" 10 "90%" 11 "full open" 12 "stop" 13 "reserved" 15 "reserved";
VAL_ 494 SunRoofSwtReq_VR 0 "No action" 1 "Full closed" 2 "Tilt Up" 3 "10%" 4 "20%" 5 "30%" 6 "40%" 7 "50%" 8 "60%" 9 "70%" 10 "80%" 11 "90%" 12 "full open" 13 "stop" 14 "reserved" 15 "reserved";
VAL_ 494 SportModLightSet 0 "OFF" 1 "Flashing&Light" 2 "Flash Only" 3 "Reserved";
VAL_ 494 ABSLmpSet 0 "OFF" 1 "ON";
VAL_ 494 AutoWshWipSet 0 "short time 300ms" 1 "middle time 500ms" 2 "long time 800ms" 3 "Reserved";
VAL_ 494 SeekVehSet 0 "Horn&Light" 1 "HornOnly" 2 "LightOnly" 3 "Reserved";
VAL_ 494 SpdAutoLockModSet 0 "OFF" 1 "8kmh" 2 "15kmh" 3 "Reserved";
VAL_ 494 ParkLmpSet 0 "OFF" 1 "ON";
VAL_ 494 DoorUnlockModSet 0 "All Door" 1 "Driver Door";
VAL_ 494 SteerWheelHeatSwtReq 0 "No action" 1 "No request" 2 "Request" 3 "Reserved";
VAL_ 494 PASExitSpdSwt 0 "No command" 1 "15kmh" 2 "30kmh" 3 "Reserved";
VAL_ 494 FrntRearACDispSts 0 "No display" 1 "Front AC display" 2 "Rear AC display" 3 "Reserved";
VAL_ 840 PowerSet 0 "OFF" 1 "ON";
VAL_ 840 HUT_CallSts_Dialing 0 "No" 1 "Yes";
VAL_ 840 HUT_CallSts_IncomingCall 0 "No" 1 "Yes";
VAL_ 840 HUT_CallSts_ongoing 0 "No" 1 "Yes";
VAL_ 840 HUT_CallTime 0 "00" 359999 "99" 360000 "invalid  do not display the call time" 16777215 "invalid  do not display the call time";
VAL_ 827 BackgroundLightLvlSet 0 "1" 1 "2" 2 "3" 3 "4" 4 "5" 5 "6" 6 "7" 7 "8" 8 "9" 9 "10" 10 "No action" 11 "Reserved" 15 "Reserved";
VAL_ 827 ManCmpSet 0 "0" 1 "1" 2 "2" 3 "3" 4 "4" 5 "5" 6 "6" 7 "7" 8 "8" 9 "9" 10 "10" 11 "Reserved" 15 "Reserved";
VAL_ 827 DispModSet 0 "Automode" 1 "Day mode" 2 "Night mode" 3 "Reserved";
VAL_ 827 WPC_SwtReq 0 "No action" 1 "Initial value" 2 "Close" 3 "Open";
VAL_ 827 AVMSwtReq 0 "OFF" 1 "ON";
VAL_ 827 NaviMediaVolLvlReq 0 "Level 0" 1 "Level 1" 2 "Level 2" 3 "Level 3" 4 "Level 4" 5 "Level 5" 6 "Level 6" 7 "Level 7" 8 "Level 8" 9 "Level 9" 10 "Level 10" 11 "Invalid" 15 "Invalid";
VAL_ 827 AVMMediaVolLvlReq 0 "Level 0" 1 "Level 1" 2 "Level 2" 3 "Level 3" 4 "Level 4" 5 "Level 5" 6 "Level 6" 7 "Level 7" 8 "Level 8" 9 "Level 9" 10 "Level 10" 11 "Invalid" 15 "Invalid";
VAL_ 827 FPASChanSwtReq 0 "OFF" 1 "ON";
VAL_ 827 RPASChanSwtReq 0 "OFF" 1 "ON";
VAL_ 827 ACRearBlwrSpdReq_VR 0 "No Command" 1 "Stepless Speed1_Low" 2 "Stepless Speed2" 3 "Stepless Speed3" 4 "Stepless Speed4" 5 "Stepless Speed5" 6 "Stepless Speed6" 7 "Stepless Speed7_High" 8 "Reserved" 15 "Reserved";
VAL_ 827 ACRearBlwrsteplsSpdReq_TC 0 "No Command" 1 "Stepless Speed1_Low" 2 "Stepless Speed2" 3 "Stepless Speed3" 4 "Stepless Speed4" 5 "Stepless Speed5" 6 "Stepless Speed6" 7 "Stepless Speed7_High" 8 "Reserved" 15 "Reserved";
VAL_ 827 PLGReq_VR 0 "No action" 1 "Close" 2 "Open" 3 "Reserved";
VAL_ 827 ACRearAirDistribModReq_VR 0 "No action" 1 "Face" 2 "Face & Foot" 3 "Foot" 4 "Reserved" 7 "Reserved";
VAL_ 827 ACZoneReq_VR 0 "No action" 1 "Close" 2 "Open" 3 "Reserved";
VAL_ 827 OPDSwtSts 0 "ON" 1 "OFF" 2 "Unselect able" 3 "No action";
VAL_ 1045 ADAS_Meta_MsgTyp 0 "System Specific" 1 "Position" 2 "Segment" 3 "Stub" 4 "Profile Short" 5 "Profile Long" 6 "Meta-data" 7 "Reserved";
VAL_ 1045 ADAS_Meta_MapProvider 0 "Unknown" 1 "Nokia HERE (NAVTEQ)" 2 "TomTom (Tele Atlas)" 3 "Zenrin" 4 "IPC" 5 "NavInfo" 6 "Other" 7 "NA";
VAL_ 1045 ADAS_Meta_CountryCode 0 "Unknown" 1 "Valid values" 1023 "Valid values";
VAL_ 1045 ADAS_Meta_CycCnt 0 "Valid values" 3 "Valid values";
VAL_ 1045 ADAS_Meta_ProtVer_Major 0 "Valid values" 3 "Valid values";
VAL_ 1045 ADAS_Meta_ProtVer_MinorSub 0 "Valid values" 7 "Valid values";
VAL_ 1045 ADAS_Meta_HwVer 0 "Unknown" 1 "Valid values" 511 "Valid values";
VAL_ 1045 ADAS_Meta_DrvSide 0 "Drvg Side Left" 1 "Drvg Side Right";
VAL_ 1045 ADAS_Meta_RegionCode 0 "Unknow" 1 "Valid values" 32766 "Valid values" 32767 "Invalid";
VAL_ 1045 ADAS_Meta_MapVerQtr 0 "Valid values" 3 "Valid values";
VAL_ 1045 ADAS_Meta_MapVerYear 0 "Valid values" 62 "Valid values" 63 "invalid";
VAL_ 1045 ADAS_Meta_SpdUnits 0 "KMH" 1 "MPH";
VAL_ 1045 ADAS_Meta_ProtVer_Minor 0 "Valid values" 15 "Valid values";
VAL_ 873 RearWinHeatCmd_TC 0 "No action" 1 "Pressed" 2 "Reserved" 3 "Reserved";
VAL_ 873 AMP_MediaCallSourceSet 0 "Media Source on" 1 "Call Source on" 2 "Reserved" 15 "Reserved";
VAL_ 873 AMP_NaviSourceSet 0 "None" 1 "Navi on" 2 "VR & TTS on" 3 "Reserved" 7 "Reserved";
VAL_ 873 AMP_BeepSourceSet 0 "None" 1 "Beep on" 2 "IP on" 3 "IP turn light on" 4 "Radar alarm on" 5 "Reserved" 7 "Reserved";
VAL_ 873 AMP_LRAudioBalanceSet 0 "Lch+10-Lch+1" 9 "Lch+10-Lch+1" 10 "Center" 11 "Rch+1-Rch+10" 20 "Rch+1-Rch+10" 21 "Reserved" 31 "Reserved";
VAL_ 873 AMP_AudioVolVSCModReq 0 "OFF" 1 "Low" 2 "Middle" 3 "High";
VAL_ 873 AMP_FRAudioFaderSet 0 "Rear+10-Rear+1" 9 "Rear+10-Rear+1" 10 "Center" 11 "Front+1-Front+10" 20 "Front+1-Front+10" 21 "Reserved" 31 "Reserved";
VAL_ 873 AMP_LRDrvSideSet 0 "Left" 1 "Right";
VAL_ 873 AMP_LowFrqAudioSet 0 "-10" 1 "-9" 2 "-8" 3 "-7" 4 "-6" 5 "-5" 6 "-4" 7 "-3" 8 "-2" 9 "-1" 10 "0" 11 "1" 12 "2" 13 "3" 14 "4" 15 "5" 16 "6" 17 "7" 18 "8" 19 "9" 20 "10" 21 "Reserved" 31 "Reserved";
VAL_ 873 AMP_MuteSet 0 "Unmute" 1 "Mute";
VAL_ 873 AMP_MidFrqAudioSet 0 "-10" 1 "-9" 2 "-8" 3 "-7" 4 "-6" 5 "-5" 6 "-4" 7 "-3" 8 "-2" 9 "-1" 10 "0" 11 "1" 12 "2" 13 "3" 14 "4" 15 "5" 16 "6" 17 "7" 18 "8" 19 "9" 20 "10" 21 "Reserved" 31 "Reserved";
VAL_ 873 AMP_HighFrqAudioSet 0 "-10" 1 "-9" 2 "-8" 3 "-7" 4 "-6" 5 "-5" 6 "-4" 7 "-3" 8 "-2" 9 "-1" 10 "0" 11 "1" 12 "2" 13 "3" 14 "4" 15 "5" 16 "6" 17 "7" 18 "8" 19 "9" 20 "10" 21 "Reserved" 31 "Reserved";
VAL_ 873 T_box_ECallSet 0 "OFF" 1 "ON";
VAL_ 873 QLISurroundSet 0 "Stereo" 1 "QLI Surround";
VAL_ 873 ANCSwtSet 0 "OFF" 1 "ON";
VAL_ 734 ADAS_ProfLong_MsgTyp 0 "System Specific" 1 "Position" 2 "Segment" 3 "Stub" 4 "Profile Short" 5 "Profile Long" 6 "Meta-data" 7 "Reserved";
VAL_ 734 ADAS_ProfLong_Offset 0 "Valid value" 8190 "Valid value" 8191 "Invalid";
VAL_ 734 ADAS_ProfLong_CycCnt 0 "Valid value" 3 "Valid value";
VAL_ 734 ADAS_ProfLong_PathIdx 0 "Valid value" 63 "Valid value";
VAL_ 734 ADAS_ProfLong_ProfTyp 0 "unkown" 1 "Longitude" 2 "Latitude" 3 "Altitude" 4 "Control Point Longitude" 5 "Control Point Latitude" 6 "Control Point Altitude" 7 "Link Identifier" 8 "Traffic Sign" 9 "Truck Speed Limits" 10 "Extended Lane" 11 "Reserved for standard types" 15 "Reserved for standard types" 16 "Reserved for system specific types" 18 "Reserved for system specific types" 19 "Traffic Event" 20 "weather" 21 "Reserved for system specific types" 31 "Reserved for system specific types";
VAL_ 734 ADAS_ProfLong_CtrlPoint 0 "false" 1 "true";
VAL_ 734 ADAS_ProfLong_Retr 0 "false" 1 "true";
VAL_ 734 ADAS_ProfLong_Update 0 "false" 1 "true";
VAL_ 734 ADAS_ProfLong_Value -2147483648 "invalid" 0 "Valid value";
VAL_ 733 ADAS_ProfShort_MsgTyp 0 "System Specific" 1 "Position" 2 "Segment" 3 "Stub" 4 "Profile Short" 5 "Profile Long" 6 "Meta-data" 7 "Reserved";
VAL_ 733 ADAS_ProfShort_Offset 0 "0-8190m" 8190 "0-8190m" 8191 "Invalid";
VAL_ 733 ADAS_ProfShort_CycCnt 0 "Valid value" 3 "Valid value";
VAL_ 733 ADAS_ProfShort_PathIdx 0 "Valid value" 63 "Valid value";
VAL_ 733 ADAS_ProfShort_ProfTyp 0 "Unknow" 1 "Curvature" 2 "Route Number Types" 3 "SlopeÃ¯Â¼ÂˆstepÃ¯Â¼Â‰" 4 "SlopeÃ¯Â¼ÂˆlinerÃ¯Â¼Â‰" 5 "Road ACCessibility" 6 "Road condition" 7 "Variable Speed Sign Position" 8 "Heading Change" 9 "Reserved for standard types" 15 "Reserved for standard types" 16 "Reserved for system specific types" 17 "Reserved for system specific types" 18 "History average speed" 19 "Traffic Flow" 20 "Reserved for system specific types" 31 "Reserved for system specific types";
VAL_ 733 ADAS_ProfShort_CtrlPoint 0 "false" 1 "true";
VAL_ 733 ADAS_ProfShort_Retr 0 "false" 1 "true";
VAL_ 733 ADAS_ProfShort_Update 0 "false" 1 "true";
VAL_ 733 ADAS_ProfShort_AccurClass 0 "Hiest accuracy" 1 "Medium accuracy" 2 "Lowest accuracy" 3 "Unknown";
VAL_ 733 ADAS_ProfShort_Dist1 0 "no other profile values are defined in this message" 1 "Valid value" 1022 "Valid value" 1023 "Invalid";
VAL_ 733 ADAS_ProfShort_Value0 0 "Valid data" 1022 "Valid data" 1023 "Unknow";
VAL_ 733 ADAS_ProfShort_Value1 0 "Valid data" 1022 "Valid data" 1023 "Unknow";
VAL_ 730 ADAS_Seg_MsgTyp 0 "System Specific" 1 "Position" 2 "Segment" 3 "Stub" 4 "Profile Short" 5 "Profile Long" 6 "Meta-data" 7 "Reserved";
VAL_ 730 ADAS_Seg_Offset 0 "Valid data" 8190 "Valid data" 8191 "Invalid data";
VAL_ 730 ADAS_Seg_CycCnt 0 "Valid value" 3 "Valid value";
VAL_ 730 ADAS_Seg_PathIdx 0 "Valid value" 63 "Valid value";
VAL_ 730 ADAS_Seg_Tunnel 0 "Segment is not part of a tunnel" 1 "Segment is part of a tunnel" 2 "Unknown" 3 "Invalid";
VAL_ 730 ADAS_Seg_Brdg 0 "Segment is not part of a bridge" 1 "Segment is part of a bridge" 2 "Unknown" 3 "Invalid";
VAL_ 730 ADAS_Seg_BuildUpArea 0 "Segment is not part of a built-up area" 1 "Segment is part of a built-up area" 2 "Unknown" 3 "Invalid";
VAL_ 730 ADAS_Seg_Retr 0 "False" 1 "True";
VAL_ 730 ADAS_Seg_Update 0 "False" 1 "True";
VAL_ 730 ADAS_Seg_RelProbb 0 "Unknown" 1 "Valid data" 30 "Valid data" 31 "Invalid";
VAL_ 730 ADAS_Seg_FuncRoadClass 0 "Unkown" 1 "Expressway" 2 "City expressway" 3 "National road" 4 "Provincial rode or County road" 5 "City or Village road" 6 "Other road" 7 "Invalid";
VAL_ 730 ADAS_Seg_PartOfCalcRoute 0 "Segment is not part of Calculated Route" 1 "Segment is part of Calculated Route" 2 "Unknown" 3 "Invalid";
VAL_ 730 ADAS_Seg_CmplxInsct 0 "Segment is not part of complex intersection" 1 "Segment is part of a complex intersection" 2 "Unknown" 3 "Invalid";
VAL_ 730 ADAS_Seg_FormOfWay 0 "Unkown" 1 "Freeway or Controlled Access road that is not a slip roadramp" 2 "Multiple Carriageway or Multiply Digitized Road" 3 "Single Carriageway (default)" 4 "Roundabout Circle" 5 "Traffic SquareSpecial Traffic Figure" 6 "Reserved" 7 "Reserved" 8 "Parallel Road (as special type of a slip roadramp)" 9 "Slip RoadRamp on a Freeway or Controlled Access road" 10 "Slip RoadRamp (not on a Freeway or Controlled Access road)" 11 "Service Road or Frontage Road" 12 "Entrance to or exit of a Car Park" 13 "Entrance to or exit to Service" 14 "Pedestrian Zone" 15 "Unknow";
VAL_ 730 ADAS_Seg_EffSpdLmt 0 "Unknown (including variable speed sign controlled)" 1 "value Ã¢Â‰Â¤ 5 kmh [mph]" 2 "5 < value Ã¢Â‰Â¤ 7 kmh [mph]" 3 "7 < value Ã¢Â‰Â¤ 10 kmh [mph]" 4 "10 < value Ã¢Â‰Â¤ 15 kmh [mph]" 5 "15 < value Ã¢Â‰Â¤ 20 kmh [mph]" 6 "20 < value Ã¢Â‰Â¤ 25 kmh [mph]" 7 "25 < value Ã¢Â‰Â¤ 30 kmh [mph]" 8 "30 < value Ã¢Â‰Â¤ 35 kmh [mph]" 9 "35 < value Ã¢Â‰Â¤ 40 kmh [mph]" 10 "40 < value Ã¢Â‰Â¤ 45 kmh [mph]" 11 "45 < value Ã¢Â‰Â¤ 50 kmh [mph]" 12 "50 < value Ã¢Â‰Â¤ 55 kmh [mph]" 13 "55 < value Ã¢Â‰Â¤ 60 kmh [mph]" 14 "60 < value Ã¢Â‰Â¤ 65 kmh [mph]" 15 "65 < value Ã¢Â‰Â¤ 70 kmh [mph]" 16 "70 < value Ã¢Â‰Â¤ 75 kmh [mph]" 17 "75 < value Ã¢Â‰Â¤ 80 kmh [mph]" 18 "80 < value Ã¢Â‰Â¤ 85 kmh [mph]" 19 "85 < value Ã¢Â‰Â¤ 90 kmh [mph]" 20 "90 < value Ã¢Â‰Â¤ 95 kmh [mph]" 21 "95 < value Ã¢Â‰Â¤ 100 kmh [mph]" 22 "100 < value Ã¢Â‰Â¤ 105 kmh [mph]" 23 "105 < value Ã¢Â‰Â¤ 110 kmh [mph]" 24 "110 < value Ã¢Â‰Â¤ 115 kmh [mph]" 25 "115 < value Ã¢Â‰Â¤ 120 kmh [mph]" 26 "120 < value Ã¢Â‰Â¤ 130 kmh [mph]" 27 "130 < value Ã¢Â‰Â¤ 140 kmh [mph]" 28 "140 < value Ã¢Â‰Â¤ 150 kmh [mph]" 29 "150 < value < unlimited" 30 "Unlimited" 31 "NA";
VAL_ 730 ADAS_Seg_EffSpdLmtTyp 0 "Implicit (for instance, default speed limit in the cities)" 1 "Explicit Ã¢Â€Â“ on traffic sign" 2 "Explicit Ã¢Â€Â“ by night" 3 "Explicit Ã¢Â€Â“ by day" 4 "Explicit Ã¢Â€Â“ time of day" 5 "Explicit Ã¢Â€Â“ Electronic eye" 6 "Explicit Ã¢Â€Â“ snow" 7 "Unknown";
VAL_ 730 ADAS_Seg_DivideRoad 0 "Segment is not part of a divided roaddual carriageway" 1 "Segment is part of a divided roaddual carriageway" 2 "Unknown" 3 "NA";
VAL_ 730 ADAS_Seg_NumOfLaneOppDir 0 "One-direction road" 1 "One lane only" 2 "Indicates 2 or more lanes" 3 "Invalid";
VAL_ 730 ADAS_Seg_NumOfLaneDrvDir 0 "One-direction road driven in wrong direction" 1 "Verbatim values" 5 "Verbatim values" 6 "Six or more lanes" 7 "invalid";
SIG_GROUP_ 584 HCU_PT7 1 : CheckSum_HCU_PT7 HCU_HybSysErr_1 HCU_HybSysErr_2 HCU_HybSysErr_3 HCU_HybSysErr_4 HCU_HybSysErr_5 HCU_HybSysErr_6 HCU_HybSysErr_7 HCU_12VSysErrLmpSts HCU_EnrgFlowInd_P2 HCU_HybSysErrLmpSts HCU_PowerRedWarnLmpCmd HCU_12VSysErr_1 HCU_12VSysErr_2 HCU_12VSysErr_3 HCU_RdyLmpSts HCU_OPDLmpSts HCU_OPDSts HCU_ModSwtFail RollingCounter_HCU_PT7;
